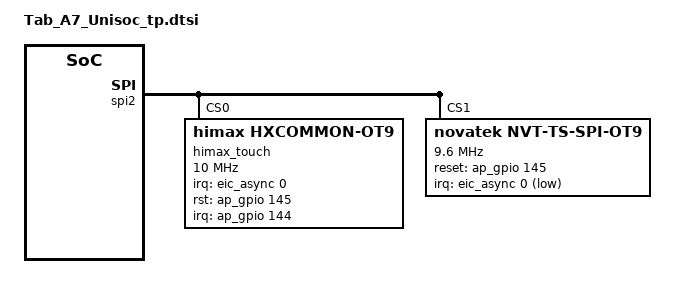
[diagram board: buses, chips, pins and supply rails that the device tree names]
/*Tab A7 T618 code for AX6189DEV-20|AX6189DEV-26 by suyurui at 2021/12/21 start*/

&spi2 {
	status = "okay";
	cs-gpios = <0>, <0>;

	himax_touch@0 {
		compatible = "himax,hxcommon-ot9";
		reg = <0>;
		status = "okay";
		spi-max-frequency = <10000000>;
		interrupt-parent = <&ap_gpio>;
		interrupts = <144 0x2004>;
		himax,panel-sense-nums = <18 32>;
		himax,panel-coords = <0 800 0 1340>;
		himax,display-coords = <0 800 0 1340>;
		himax,panel-max-points = <10>;
		himax,int-is-edge = <1>;
		/*Tab A7 T618 code for SR-AX6189A-01-425 by suyurui at 2021/12/28 start*/
		himax,irq-gpio = <&eic_async 0 GPIO_ACTIVE_HIGH>;
		/*Tab A7 T618 code for SR-AX6189A-01-425 by suyurui at 2021/12/28 end*/
		himax,rst-gpio = <&ap_gpio 145 GPIO_ACTIVE_HIGH>;
		report_type = <1>;
	};

	/*Tab A7 T618 code for SR-AX6189A-01-148 by suyurui at 2021/12/22 start*/
	novatek@1 {
		compatible = "novatek,NVT-ts-spi-ot9";
		reg = <1>; //Same as CS ID
		status = "ok";

		spi-max-frequency = <9600000>;	//4800000,9600000,15000000,19200000
		novatek,reset-gpio = <&ap_gpio 145 0x00>;
		/*Tab A7 T618 code for SR-AX6189A-01-425 by suyurui at 2021/12/28 start*/
		novatek,irq-gpio = <&eic_async 0 0x2001>;
		/*Tab A7 T618 code for SR-AX6189A-01-425 by suyurui at 2021/12/28 end*/

		//novatek,pen-support;
		//novatek,wgp-stylus;

		/* 525 */
		//novatek,swrst-n8-addr = <0x01F01A>;

		/* 672A, 525B, 675, 526, 672C, 523 */
		novatek,swrst-n8-addr = <0x03F0FE>;
		novatek,spi-rd-fast-addr = <0x03F310>;

		/*Panel setting*/
		novatek,resolution = <800 1340>;
		novatek,max_touch_num = <10>;
		novatek,area-size = <56 112 60>;	//indicator navigation edge
		novatek,fw_name = "novatek_ts_fw.bin", "tsp_novatek/nt36525_a01core_tp.bin";
		novatek,fw_name_mp = "novatek_ts_mp.bin", "tsp_novatek/nt36525_a01core_mp.bin";
		//novatek,support_ear_detect_mode;
		novatek,enable_settings_aot;

		/* MP */
		novatek,mp-support-dt;

		novatek-mp-criteria-724A@0 {
			#address-cells = <1>;
			#size-cells = <0>;
			compatible = "novatek-mp-criteria-724A";

			/* sec cmd test config */
			open_test_spec = <(-511) 5120>;
			short_test_spec = <10000 14008>;
			diff_test_frame = <50>;
			/* sec cmd fdm test config */
			fdm_x_num = <2>;
			fdm_diff_test_frame = <50>;

			/* MP Config */
			IC_X_CFG_SIZE = <22>;
			IC_Y_CFG_SIZE = <36>;
			IC_KEY_CFG_SIZE = <4>;
			X_Channel = <22>;
			Y_Channel = <36>;
			AIN_X = <0 1 2 3 4 5 6 7 8 9 10 11 12 13 14 15 16 17 18 19 20 21>;
			AIN_Y = <0 1 2 3 4 5 6 7 8 9 10 11 12 13 14 15 16 17
						18 19 20 21 22 23 24 25 26 27 28 29 30 31 32 33 34 35>;
			AIN_KEY = <0 1 2 0xFF 0xFF 0xFF 0xFF 0xFF>;

			/* MP Criteria */
			PS_Config_Lmt_Short_Rawdata_P = <
				14008 14008 14008 14008 14008 14008 14008 14008 14008 14008 14008 14008 14008 14008 14008 14008 14008 14008 14008 14008 14008 14008
				14008 14008 14008 14008 14008 14008 14008 14008 14008 14008 14008 14008 14008 14008 14008 14008 14008 14008 14008 14008 14008 14008
				14008 14008 14008 14008 14008 14008 14008 14008 14008 14008 14008 14008 14008 14008 14008 14008 14008 14008 14008 14008 14008 14008
				14008 14008 14008 14008 14008 14008 14008 14008 14008 14008 14008 14008 14008 14008 14008 14008 14008 14008 14008 14008 14008 14008
				14008 14008 14008 14008 14008 14008 14008 14008 14008 14008 14008 14008 14008 14008 14008 14008 14008 14008 14008 14008 14008 14008
				14008 14008 14008 14008 14008 14008 14008 14008 14008 14008 14008 14008 14008 14008 14008 14008 14008 14008 14008 14008 14008 14008
				14008 14008 14008 14008 14008 14008 14008 14008 14008 14008 14008 14008 14008 14008 14008 14008 14008 14008 14008 14008 14008 14008
				14008 14008 14008 14008 14008 14008 14008 14008 14008 14008 14008 14008 14008 14008 14008 14008 14008 14008 14008 14008 14008 14008
				14008 14008 14008 14008 14008 14008 14008 14008 14008 14008 14008 14008 14008 14008 14008 14008 14008 14008 14008 14008 14008 14008
				14008 14008 14008 14008 14008 14008 14008 14008 14008 14008 14008 14008 14008 14008 14008 14008 14008 14008 14008 14008 14008 14008
				14008 14008 14008 14008 14008 14008 14008 14008 14008 14008 14008 14008 14008 14008 14008 14008 14008 14008 14008 14008 14008 14008
				14008 14008 14008 14008 14008 14008 14008 14008 14008 14008 14008 14008 14008 14008 14008 14008 14008 14008 14008 14008 14008 14008
				14008 14008 14008 14008 14008 14008 14008 14008 14008 14008 14008 14008 14008 14008 14008 14008 14008 14008 14008 14008 14008 14008
				14008 14008 14008 14008 14008 14008 14008 14008 14008 14008 14008 14008 14008 14008 14008 14008 14008 14008 14008 14008 14008 14008
				14008 14008 14008 14008 14008 14008 14008 14008 14008 14008 14008 14008 14008 14008 14008 14008 14008 14008 14008 14008 14008 14008
				14008 14008 14008 14008 14008 14008 14008 14008 14008 14008 14008 14008 14008 14008 14008 14008 14008 14008 14008 14008 14008 14008
				14008 14008 14008 14008 14008 14008 14008 14008 14008 14008 14008 14008 14008 14008 14008 14008 14008 14008 14008 14008 14008 14008
				14008 14008 14008 14008 14008 14008 14008 14008 14008 14008 14008 14008 14008 14008 14008 14008 14008 14008 14008 14008 14008 14008
				14008 14008 14008 14008 14008 14008 14008 14008 14008 14008 14008 14008 14008 14008 14008 14008 14008 14008 14008 14008 14008 14008
				14008 14008 14008 14008 14008 14008 14008 14008 14008 14008 14008 14008 14008 14008 14008 14008 14008 14008 14008 14008 14008 14008
				14008 14008 14008 14008 14008 14008 14008 14008 14008 14008 14008 14008 14008 14008 14008 14008 14008 14008 14008 14008 14008 14008
				14008 14008 14008 14008 14008 14008 14008 14008 14008 14008 14008 14008 14008 14008 14008 14008 14008 14008 14008 14008 14008 14008
				14008 14008 14008 14008 14008 14008 14008 14008 14008 14008 14008 14008 14008 14008 14008 14008 14008 14008 14008 14008 14008 14008
				14008 14008 14008 14008 14008 14008 14008 14008 14008 14008 14008 14008 14008 14008 14008 14008 14008 14008 14008 14008 14008 14008
				14008 14008 14008 14008 14008 14008 14008 14008 14008 14008 14008 14008 14008 14008 14008 14008 14008 14008 14008 14008 14008 14008
				14008 14008 14008 14008 14008 14008 14008 14008 14008 14008 14008 14008 14008 14008 14008 14008 14008 14008 14008 14008 14008 14008
				14008 14008 14008 14008 14008 14008 14008 14008 14008 14008 14008 14008 14008 14008 14008 14008 14008 14008 14008 14008 14008 14008
				14008 14008 14008 14008 14008 14008 14008 14008 14008 14008 14008 14008 14008 14008 14008 14008 14008 14008 14008 14008 14008 14008
				14008 14008 14008 14008 14008 14008 14008 14008 14008 14008 14008 14008 14008 14008 14008 14008 14008 14008 14008 14008 14008 14008
				14008 14008 14008 14008 14008 14008 14008 14008 14008 14008 14008 14008 14008 14008 14008 14008 14008 14008 14008 14008 14008 14008
				14008 14008 14008 14008 14008 14008 14008 14008 14008 14008 14008 14008 14008 14008 14008 14008 14008 14008 14008 14008 14008 14008
				14008 14008 14008 14008 14008 14008 14008 14008 14008 14008 14008 14008 14008 14008 14008 14008 14008 14008 14008 14008 14008 14008
				14008 14008 14008 14008 14008 14008 14008 14008 14008 14008 14008 14008 14008 14008 14008 14008 14008 14008 14008 14008 14008 14008
				14008 14008 14008 14008 14008 14008 14008 14008 14008 14008 14008 14008 14008 14008 14008 14008 14008 14008 14008 14008 14008 14008
				14008 14008 14008 14008 14008 14008 14008 14008 14008 14008 14008 14008 14008 14008 14008 14008 14008 14008 14008 14008 14008 14008
				14008 14008 14008 14008 14008 14008 14008 14008 14008 14008 14008 14008 14008 14008 14008 14008 14008 14008 14008 14008 14008 14008
				14008 14008 14008>;

			PS_Config_Lmt_Short_Rawdata_N = <
				10100	10100	10100	10100	10100	10100	10100	10100	10100	10100	10100	10100	10100	10100	10100	10100	10100	10100	10100	10100	10100	10100
				10100	10100	10100	10100	10100	10100	10100	10100	10100	10100	10100	10100	10100	10100	10100	10100	10100	10100	10100	10100	10100	10100
				10100	10100	10100	10100	10100	10100	10100	10100	10100	10100	10100	10100	10100	10100	10100	10100	10100	10100	10100	10100	10100	10100
				10100	10100	10100	10100	10100	10100	10100	10100	10100	10100	10100	10100	10100	10100	10100	10100	10100	10100	10100	10100	10100	10100
				10100	10100	10100	10100	10100	10100	10100	10100	10100	10100	10100	10100	10100	10100	10100	10100	10100	10100	10100	10100	10100	10100
				10100	10100	10100	10100	10100	10100	10100	10100	10100	10100	10100	10100	10100	10100	10100	10100	10100	10100	10100	10100	10100	10100
				10100	10100	10100	10100	10100	10100	10100	10100	10100	10100	10100	10100	10100	10100	10100	10100	10100	10100	10100	10100	10100	10100
				10100	10100	10100	10100	10100	10100	10100	10100	10100	10100	10100	10100	10100	10100	10100	10100	10100	10100	10100	10100	10100	10100
				10100	10100	10100	10100	10100	10100	10100	10100	10100	10100	10100	10100	10100	10100	10100	10100	10100	10100	10100	10100	10100	10100
				10100	10100	10100	10100	10100	10100	10100	10100	10100	10100	10100	10100	10100	10100	10100	10100	10100	10100	10100	10100	10100	10100
				10100	10100	10100	10100	10100	10100	10100	10100	10100	10100	10100	10100	10100	10100	10100	10100	10100	10100	10100	10100	10100	10100
				10100	10100	10100	10100	10100	10100	10100	10100	10100	10100	10100	10100	10100	10100	10100	10100	10100	10100	10100	10100	10100	10100
				10100	10100	10100	10100	10100	10100	10100	10100	10100	10100	10100	10100	10100	10100	10100	10100	10100	10100	10100	10100	10100	10100
				10100	10100	10100	10100	10100	10100	10100	10100	10100	10100	10100	10100	10100	10100	10100	10100	10100	10100	10100	10100	10100	10100
				10100	10100	10100	10100	10100	10100	10100	10100	10100	10100	10100	10100	10100	10100	10100	10100	10100	10100	10100	10100	10100	10100
				10100	10100	10100	10100	10100	10100	10100	10100	10100	10100	10100	10100	10100	10100	10100	10100	10100	10100	10100	10100	10100	10100
				10100	10100	10100	10100	10100	10100	10100	10100	10100	10100	10100	10100	10100	10100	10100	10100	10100	10100	10100	10100	10100	10100
				10100	10100	10100	10100	10100	10100	10100	10100	10100	10100	10100	10100	10100	10100	10100	10100	10100	10100	10100	10100	10100	10100
				10100	10100	10100	10100	10100	10100	10100	10100	10100	10100	10100	10100	10100	10100	10100	10100	10100	10100	10100	10100	10100	10100
				10100	10100	10100	10100	10100	10100	10100	10100	10100	10100	10100	10100	10100	10100	10100	10100	10100	10100	10100	10100	10100	10100
				10100	10100	10100	10100	10100	10100	10100	10100	10100	10100	10100	10100	10100	10100	10100	10100	10100	10100	10100	10100	10100	10100
				10100	10100	10100	10100	10100	10100	10100	10100	10100	10100	10100	10100	10100	10100	10100	10100	10100	10100	10100	10100	10100	10100
				10100	10100	10100	10100	10100	10100	10100	10100	10100	10100	10100	10100	10100	10100	10100	10100	10100	10100	10100	10100	10100	10100
				10100	10100	10100	10100	10100	10100	10100	10100	10100	10100	10100	10100	10100	10100	10100	10100	10100	10100	10100	10100	10100	10100
				10100	10100	10100	10100	10100	10100	10100	10100	10100	10100	10100	10100	10100	10100	10100	10100	10100	10100	10100	10100	10100	10100
				10100	10100	10100	10100	10100	10100	10100	10100	10100	10100	10100	10100	10100	10100	10100	10100	10100	10100	10100	10100	10100	10100
				10100	10100	10100	10100	10100	10100	10100	10100	10100	10100	10100	10100	10100	10100	10100	10100	10100	10100	10100	10100	10100	10100
				10100	10100	10100	10100	10100	10100	10100	10100	10100	10100	10100	10100	10100	10100	10100	10100	10100	10100	10100	10100	10100	10100
				10100	10100	10100	10100	10100	10100	10100	10100	10100	10100	10100	10100	10100	10100	10100	10100	10100	10100	10100	10100	10100	10100
				10100	10100	10100	10100	10100	10100	10100	10100	10100	10100	10100	10100	10100	10100	10100	10100	10100	10100	10100	10100	10100	10100
				10100	10100	10100	10100	10100	10100	10100	10100	10100	10100	10100	10100	10100	10100	10100	10100	10100	10100	10100	10100	10100	10100
				10100	10100	10100	10100	10100	10100	10100	10100	10100	10100	10100	10100	10100	10100	10100	10100	10100	10100	10100	10100	10100	10100
				10100	10100	10100	10100	10100	10100	10100	10100	10100	10100	10100	10100	10100	10100	10100	10100	10100	10100	10100	10100	10100	10100
				10100	10100	10100	10100	10100	10100	10100	10100	10100	10100	10100	10100	10100	10100	10100	10100	10100	10100	10100	10100	10100	10100
				10100	10100	10100	10100	10100	10100	10100	10100	10100	10100	10100	10100	10100	10100	10100	10100	10100	10100	10100	10100	10100	10100
				10100	10100	10100	10100	10100	10100	10100	10100	10100	10100	10100	10100	10100	10100	10100	10100	10100	10100	10100	10100	10100	10100
				10000 10000 10000>;

			PS_Config_Lmt_Open_Rawdata_P = <
				3568	3542	3516	3416	3431	3397	3400	3369	3477	3388	3287	3339	3417	3354	3336	3413	3374	3403	3488	3607	3595	3565
				3494	3445	3483	3442	3396	3392	3306	3288	3365	3298	3250	3259	3343	3298	3318	3448	3399	3340	3420	3514	3498	3507
				3563	3542	3530	3438	3319	3390	3323	3288	3446	3364	3123	3320	3414	3383	3360	3474	3395	3379	3477	3571	3568	3399
				3497	3455	3462	3434	3337	3396	3392	3365	3403	3264	3259	3285	3357	3315	3313	3420	3371	3341	3460	3553	3451	3508
				3444	3484	3488	3418	3312	3395	3327	3264	3383	3201	3273	3284	3362	3337	3323	3425	3403	3319	3437	3504	3388	3544
				3537	3431	3441	3396	3301	3376	3318	3246	3339	3346	3222	3270	3346	3288	3288	3362	3341	3361	3327	3445	3488	3451
				3455	3453	3456	3459	3361	3438	3346	3197	3297	3313	3299	3285	3340	3319	3353	3339	3404	3358	3334	3414	3480	3535
				3539	3488	3490	3395	3318	3376	3236	3318	3386	3332	3245	3264	3365	3322	3281	3288	3360	3245	3428	3560	3543	3491
				3462	3444	3467	3477	3371	3465	3312	3312	3249	3325	3255	3276	3351	3316	3346	3340	3430	3353	3469	3574	3521	3542
				3498	3438	3484	3418	3200	3263	3326	3309	3257	3330	3312	3281	3407	3375	3308	3189	3256	3355	3435	3515	3491	3488
				3490	3427	3465	3427	3283	3413	3389	3325	3274	3374	3298	3313	3423	3368	3347	3308	3378	3417	3493	3568	3565	3498
				3493	3442	3465	3353	3392	3409	3346	3304	3263	3353	3291	3283	3368	3340	3176	3340	3411	3369	3453	3493	3500	3549
				3511	3460	3504	3460	3337	3437	3372	3362	3320	3414	3320	3332	3423	3409	3304	3357	3404	3400	3502	3500	3561	3529
				3483	3284	3325	3467	3399	3472	3404	3306	3284	3351	3309	3294	3361	3193	3374	3334	3437	3403	3430	3442	3519	3505
				3543	3505	3553	3501	3353	3430	3385	3386	3330	3431	3353	3357	3312	3414	3374	3348	3414	3395	3495	3501	3582	3584
				3322	3467	3490	3487	3376	3430	3404	3319	3280	3353	3295	3110	3264	3374	3347	3344	3472	3453	3469	3469	3518	3497
				3558	3522	3568	3529	3372	3277	3393	3332	3284	3428	3354	3341	3320	3438	3425	3376	3490	3442	3511	3516	3572	3563
				3494	3465	3481	3470	3368	3292	3393	3392	3353	3376	3313	3315	3287	3381	3358	3347	3438	3416	3472	3498	3551	3505
				3487	3472	3554	3537	3390	3311	3430	3379	3299	3400	3341	3351	3332	3430	3417	3396	3491	3488	3486	3515	3542	3537
				3567	3544	3500	3495	3367	3295	3414	3371	3358	3438	3383	3319	3318	3414	3378	3358	3425	3425	3530	3493	3571	3544
				3528	3487	3518	3515	3425	3353	3483	3400	3313	3403	3350	3334	3327	3413	3407	3420	3367	3493	3528	3493	3542	3525
				3518	3546	3556	3547	3371	3313	3418	3389	3333	3400	3367	3367	3304	3439	3400	3336	3319	3451	3497	3501	3602	3581
				3532	3497	3514	3512	3444	3360	3493	3424	3326	3231	3354	3365	3318	3413	3393	3399	3374	3511	3586	3532	3607	3556
				3519	3523	3508	3539	3382	3309	3410	3364	3326	3243	3353	3336	3319	3472	3451	3369	3337	3452	3515	3500	3553	3521
				3558	3521	3428	3519	3392	3313	3487	3424	3347	3259	3393	3417	3346	3487	3437	3407	3382	3500	3574	3557	3605	3599
				3497	3515	3444	3518	3455	3379	3431	3379	3323	3243	3371	3347	3316	3434	3414	3371	3364	3487	3523	3511	3528	3532
				3560	3536	3458	3551	3437	3322	3456	3413	3381	3302	3435	3409	3365	3487	3484	3382	3376	3480	3554	3578	3549	3595
				3519	3508	3439	3533	3425	3374	3495	3446	3313	3262	3368	3357	3318	3418	3421	3423	3344	3505	3556	3486	3493	3540
				3523	3563	3498	3586	3445	3327	3451	3411	3392	3306	3442	3386	3379	3340	3479	3418	3354	3479	3542	3550	3553	3606
				3565	3502	3452	3523	3434	3354	3445	3425	3325	3253	3358	3378	3302	3285	3432	3383	3354	3539	3598	3516	3511	3533
				3519	3582	3502	3595	3465	3343	3257	3409	3334	3257	3431	3361	3361	3341	3490	3459	3382	3544	3575	3558	3554	3591
				3536	3514	3444	3505	3402	3337	3267	3403	3390	3318	3379	3423	3326	3299	3424	3393	3348	3481	3540	3514	3528	3565
				3571	3564	3490	3627	3509	3404	3323	3495	3417	3308	3449	3459	3410	3381	3528	3494	3444	3578	3656	3572	3592	3600
				3568	3627	3556	3561	3462	3372	3308	3469	3404	3350	3480	3424	3362	3360	3502	3441	3388	3502	3584	3614	3556	3621
				3596	3574	3490	3568	3474	3417	3350	3523	3424	3294	3424	3486	3367	3364	3487	3465	3444	3402	3641	3596	3554	3588
				3586	3567	3554	3605	3519	3361	3318	3462	3420	3333	3434	3432	3416	3347	3518	3463	3369	3357	3599	3565	3567	3680
				5120 5120 5120>;

			PS_Config_Lmt_Open_Rawdata_N = <
				1529	1518	1507	1464	1470	1456	1457	1444	1490	1452	1408	1431	1464	1437	1429	1462	1446	1458	1495	1546	1540	1528
				1497	1476	1492	1475	1455	1453	1417	1409	1442	1413	1393	1396	1432	1413	1422	1477	1456	1431	1465	1506	1499	1503
				1527	1518	1513	1473	1422	1453	1424	1409	1477	1441	1338	1423	1463	1450	1440	1489	1455	1448	1490	1530	1529	1456
				1498	1480	1483	1471	1430	1455	1453	1442	1458	1399	1396	1408	1438	1420	1420	1465	1444	1432	1483	1522	1479	1503
				1476	1493	1495	1465	1419	1455	1426	1399	1450	1372	1402	1407	1441	1430	1424	1468	1458	1422	1473	1501	1452	1519
				1516	1470	1474	1455	1414	1447	1422	1391	1431	1434	1381	1401	1434	1409	1409	1441	1432	1440	1426	1476	1495	1479
				1480	1480	1481	1482	1440	1473	1434	1370	1413	1420	1414	1408	1431	1422	1437	1431	1459	1439	1429	1463	1491	1515
				1516	1495	1495	1455	1422	1447	1387	1422	1451	1428	1390	1399	1442	1423	1406	1409	1440	1390	1469	1525	1518	1496
				1483	1476	1486	1490	1444	1485	1419	1419	1392	1425	1395	1404	1436	1421	1434	1431	1470	1437	1486	1531	1509	1518
				1499	1473	1493	1465	1371	1398	1425	1418	1396	1427	1419	1406	1460	1446	1417	1366	1395	1438	1472	1506	1496	1495
				1495	1468	1485	1468	1407	1462	1452	1425	1403	1446	1413	1420	1467	1443	1434	1417	1447	1464	1497	1529	1528	1499
				1497	1475	1485	1437	1453	1461	1434	1416	1398	1437	1410	1407	1443	1431	1361	1431	1462	1444	1480	1497	1500	1521
				1504	1483	1501	1483	1430	1473	1445	1441	1423	1463	1423	1428	1467	1461	1416	1438	1459	1457	1501	1500	1526	1512
				1492	1407	1425	1486	1456	1488	1459	1417	1407	1436	1418	1411	1440	1368	1446	1429	1473	1458	1470	1475	1508	1502
				1518	1502	1522	1500	1437	1470	1450	1451	1427	1470	1437	1438	1419	1463	1446	1435	1463	1455	1498	1500	1535	1536
				1423	1486	1495	1494	1447	1470	1459	1422	1405	1437	1412	1333	1399	1446	1434	1433	1488	1480	1486	1486	1507	1498
				1525	1509	1529	1512	1445	1404	1454	1428	1407	1469	1437	1432	1423	1473	1468	1447	1495	1475	1504	1507	1531	1527
				1497	1485	1492	1487	1443	1411	1454	1453	1437	1447	1420	1420	1408	1449	1439	1434	1473	1464	1488	1499	1522	1502
				1494	1488	1523	1516	1453	1419	1470	1448	1414	1457	1432	1436	1428	1470	1464	1455	1496	1495	1494	1506	1518	1516
				1528	1519	1500	1498	1443	1412	1463	1444	1439	1473	1450	1422	1422	1463	1447	1439	1468	1468	1513	1497	1530	1519
				1512	1494	1507	1506	1468	1437	1492	1457	1420	1458	1435	1429	1426	1462	1460	1465	1443	1497	1512	1497	1518	1510
				1507	1519	1524	1520	1444	1420	1465	1452	1428	1457	1443	1443	1416	1474	1457	1429	1422	1479	1498	1500	1543	1534
				1513	1498	1506	1505	1476	1440	1497	1467	1425	1384	1437	1442	1422	1462	1454	1456	1446	1504	1537	1513	1546	1524
				1508	1510	1503	1516	1449	1418	1461	1441	1425	1390	1437	1429	1422	1488	1479	1444	1430	1479	1506	1500	1522	1509
				1525	1509	1469	1508	1453	1420	1494	1467	1434	1396	1454	1464	1434	1494	1473	1460	1449	1500	1531	1524	1545	1542
				1498	1506	1476	1507	1480	1448	1470	1448	1424	1390	1444	1434	1421	1471	1463	1444	1441	1494	1510	1504	1512	1513
				1525	1515	1482	1522	1473	1423	1481	1462	1449	1415	1472	1461	1442	1494	1493	1449	1447	1491	1523	1533	1521	1540
				1508	1503	1474	1514	1468	1446	1498	1477	1420	1398	1443	1438	1422	1465	1466	1467	1433	1502	1524	1494	1497	1517
				1510	1527	1499	1537	1476	1426	1479	1462	1453	1417	1475	1451	1448	1431	1491	1465	1437	1491	1518	1521	1522	1545
				1528	1501	1479	1510	1471	1437	1476	1468	1425	1394	1439	1447	1415	1408	1471	1450	1437	1516	1542	1507	1504	1514
				1508	1535	1501	1540	1485	1432	1396	1461	1429	1396	1470	1440	1440	1432	1495	1482	1449	1519	1532	1525	1523	1539
				1515	1506	1476	1502	1458	1430	1400	1458	1453	1422	1448	1467	1425	1414	1467	1454	1435	1492	1517	1506	1512	1528
				1530	1527	1495	1554	1504	1459	1424	1498	1464	1417	1478	1482	1461	1449	1512	1497	1476	1533	1567	1531	1539	1543
				1529	1554	1524	1526	1483	1445	1417	1486	1459	1435	1491	1467	1441	1440	1501	1474	1452	1501	1536	1549	1524	1552
				1541	1531	1495	1529	1489	1464	1435	1510	1467	1411	1467	1494	1443	1441	1494	1485	1476	1458	1560	1541	1523	1537
				1537	1528	1523	1545	1508	1440	1422	1483	1465	1428	1471	1471	1464	1434	1507	1484	1444	1438	1542	1528	1528	1577
				(-511) (-511) (-511)>;

			PS_Config_Lmt_FW_Rawdata_P = <
				1125	1122	1129	1127	1127	1118	1114	1120	1117	1120	1121	1122	1124	1117	1127	1121	1120	1114	1131	1122	1128	1129
				1115	1117	1124	1122	1110	1111	1118	1108	1128	1118	1128	1113	1124	1111	1120	1117	1118	1117	1122	1122	1113	1122
				1115	1117	1125	1121	1124	1120	1121	1122	1122	1115	1120	1122	1118	1120	1124	1124	1117	1117	1108	1114	1127	1115
				1118	1120	1121	1127	1122	1114	1117	1129	1113	1118	1111	1131	1121	1114	1117	1111	1128	1127	1117	1111	1104	1103
				1122	1125	1121	1118	1121	1107	1120	1138	1113	1111	1121	1127	1124	1120	1121	1122	1120	1113	1114	1118	1125	1115
				1127	1131	1121	1118	1129	1110	1125	1134	1115	1121	1122	1118	1118	1115	1131	1122	1120	1124	1125	1113	1103	1122
				1128	1120	1111	1122	1117	1122	1114	1117	1131	1115	1125	1120	1120	1121	1121	1120	1120	1111	1122	1125	1113	1122
				1122	1118	1122	1127	1114	1118	1118	1124	1117	1127	1122	1120	1118	1115	1118	1117	1114	1122	1122	1114	1125	1122
				1120	1114	1117	1128	1120	1121	1114	1113	1127	1122	1118	1124	1114	1117	1110	1117	1122	1120	1122	1113	1117	1118
				1122	1125	1124	1122	1120	1117	1118	1120	1122	1128	1120	1120	1117	1121	1128	1125	1117	1128	1120	1113	1117	1125
				1120	1122	1122	1118	1124	1114	1114	1121	1124	1125	1120	1113	1117	1120	1124	1111	1124	1115	1117	1125	1120	1114
				1122	1122	1122	1120	1117	1128	1135	1115	1128	1120	1113	1120	1124	1111	1124	1121	1125	1124	1132	1124	1117	1131
				1122	1120	1122	1124	1127	1114	1118	1128	1117	1121	1131	1120	1115	1122	1118	1118	1120	1122	1124	1117	1121	1122
				1114	1124	1115	1118	1132	1120	1122	1124	1111	1127	1118	1131	1118	1124	1121	1125	1121	1118	1121	1129	1108	1117
				1113	1115	1127	1134	1120	1115	1115	1121	1118	1117	1117	1128	1114	1122	1115	1115	1122	1113	1113	1113	1125	1122
				1110	1111	1121	1114	1121	1129	1113	1124	1120	1128	1120	1120	1129	1127	1122	1114	1111	1118	1117	1122	1115	1107
				1122	1114	1118	1124	1113	1121	1121	1122	1122	1124	1128	1113	1117	1120	1120	1122	1125	1118	1125	1111	1118	1120
				1110	1115	1124	1120	1118	1121	1125	1120	1115	1113	1107	1117	1114	1120	1125	1114	1122	1108	1114	1122	1127	1120
				1121	1124	1122	1122	1121	1118	1129	1125	1129	1121	1125	1128	1108	1121	1120	1113	1113	1117	1124	1118	1125	1120
				1117	1122	1121	1111	1120	1118	1138	1120	1127	1127	1117	1114	1121	1125	1128	1128	1122	1125	1118	1124	1122	1125
				1120	1131	1127	1124	1131	1115	1114	1132	1117	1115	1118	1127	1121	1124	1113	1117	1118	1117	1122	1115	1124	1124
				1127	1125	1121	1121	1121	1110	1118	1117	1121	1125	1122	1122	1122	1124	1129	1114	1131	1129	1120	1115	1117	1121
				1107	1114	1110	1115	1115	1120	1115	1120	1118	1117	1120	1124	1115	1125	1115	1111	1114	1117	1111	1114	1121	1124
				1118	1120	1125	1104	1118	1113	1115	1117	1121	1120	1114	1121	1110	1124	1111	1127	1117	1120	1120	1113	1129	1124
				1131	1120	1120	1118	1117	1125	1120	1124	1114	1115	1118	1117	1121	1115	1122	1121	1110	1121	1127	1115	1117	1118
				1136	1122	1122	1111	1114	1115	1120	1107	1120	1122	1104	1124	1114	1113	1121	1113	1118	1114	1129	1128	1120	1108
				1122	1120	1118	1114	1122	1127	1111	1127	1124	1114	1125	1124	1118	1129	1122	1122	1122	1117	1113	1120	1115	1129
				1127	1117	1120	1114	1125	1129	1118	1118	1121	1110	1120	1124	1124	1118	1124	1122	1127	1122	1129	1120	1138	1111
				1121	1127	1115	1121	1131	1114	1121	1118	1111	1120	1117	1118	1117	1114	1118	1120	1111	1114	1120	1111	1121	1118
				1114	1120	1113	1113	1120	1121	1113	1106	1127	1113	1120	1135	1117	1135	1127	1125	1114	1127	1108	1120	1121	1122
				1124	1122	1118	1117	1114	1121	1120	1122	1111	1124	1120	1117	1115	1115	1115	1122	1120	1118	1122	1124	1114	1118
				1124	1118	1108	1125	1117	1128	1121	1121	1127	1120	1117	1118	1127	1115	1118	1128	1117	1121	1114	1124	1127	1131
				1118	1120	1127	1118	1122	1115	1114	1120	1124	1125	1113	1117	1118	1114	1117	1122	1128	1114	1121	1120	1114	1118
				1114	1128	1121	1122	1124	1111	1117	1128	1117	1114	1114	1113	1120	1115	1129	1114	1107	1121	1125	1125	1125	1122
				1117	1114	1122	1124	1120	1113	1121	1127	1113	1120	1113	1122	1121	1122	1124	1124	1125	1121	1114	1110	1120	1125
				1121	1121	1124	1118	1124	1121	1125	1127	1124	1125	1120	1111	1115	1108	1121	1107	1127	1120	1118	1118	1117	1124
				3840 3840 3840>;

			PS_Config_Lmt_FW_Rawdata_N = <
				482	481	484	483	483	479	477	480	478	480	480	481	481	478	483	480	480	477	484	481	483	484
				478	478	481	481	475	476	479	475	483	479	483	477	481	476	480	478	479	478	481	481	477	481
				478	478	482	480	481	480	480	481	481	478	480	481	479	480	481	481	478	478	475	477	483	478
				479	480	480	483	481	477	478	484	477	479	476	484	480	477	478	476	483	483	478	476	473	472
				481	482	480	479	480	474	480	487	477	476	480	483	481	480	480	481	480	477	477	479	482	478
				483	484	480	479	484	475	482	486	478	480	481	479	479	478	484	481	480	481	482	477	472	481
				483	480	476	481	478	481	477	478	484	478	482	480	480	480	480	480	480	476	481	482	477	481
				481	479	481	483	477	479	479	481	478	483	481	480	479	478	479	478	477	481	481	477	482	481
				480	477	478	483	480	480	477	477	483	481	479	481	477	478	475	478	481	480	481	477	478	479
				481	482	481	481	480	478	479	480	481	483	480	480	478	480	483	482	478	483	480	477	478	482
				480	481	481	479	481	477	477	480	481	482	480	477	478	480	481	476	481	478	478	482	480	477
				481	481	481	480	478	483	486	478	483	480	477	480	481	476	481	480	482	481	485	481	478	484
				481	480	481	481	483	477	479	483	478	480	484	480	478	481	479	479	480	481	481	478	480	481
				477	481	478	479	485	480	481	481	476	483	479	484	479	481	480	482	480	479	480	484	475	478
				477	478	483	486	480	478	478	480	479	478	478	483	477	481	478	478	481	477	477	477	482	481
				475	476	480	477	480	484	477	481	480	483	480	480	484	483	481	477	476	479	478	481	478	474
				481	477	479	481	477	480	480	481	481	481	483	477	478	480	480	481	482	479	482	476	479	480
				475	478	481	480	479	480	482	480	478	477	474	478	477	480	482	477	481	475	477	481	483	480
				480	481	481	481	480	479	484	482	484	480	482	483	475	480	480	477	477	478	481	479	482	480
				478	481	480	476	480	479	487	480	483	483	478	477	480	482	483	483	481	482	479	481	481	482
				480	484	483	481	484	478	477	485	478	478	479	483	480	481	477	478	479	478	481	478	481	481
				483	482	480	480	480	475	479	478	480	482	481	481	481	481	484	477	484	484	480	478	478	480
				474	477	475	478	478	480	478	480	479	478	480	481	478	482	478	476	477	478	476	477	480	481
				479	480	482	473	479	477	478	478	480	480	477	480	475	481	476	483	478	480	480	477	484	481
				484	480	480	479	478	482	480	481	477	478	479	478	480	478	481	480	475	480	483	478	478	479
				487	481	481	476	477	478	480	474	480	481	473	481	477	477	480	477	479	477	484	483	480	475
				481	480	479	477	481	483	476	483	481	477	482	481	479	484	481	481	481	478	477	480	478	484
				483	478	480	477	482	484	479	479	480	475	480	481	481	479	481	481	483	481	484	480	487	476
				480	483	478	480	484	477	480	479	476	480	478	479	478	477	479	480	476	477	480	476	480	479
				477	480	477	477	480	480	477	474	483	477	480	486	478	486	483	482	477	483	475	480	480	481
				481	481	479	478	477	480	480	481	476	481	480	478	478	478	478	481	480	479	481	481	477	479
				481	479	475	482	478	483	480	480	483	480	478	479	483	478	479	483	478	480	477	481	483	484
				479	480	483	479	481	478	477	480	481	482	477	478	479	477	478	481	483	477	480	480	477	479
				477	483	480	481	481	476	478	483	478	477	477	477	480	478	484	477	474	480	482	482	482	481
				478	477	481	481	480	477	480	483	477	480	477	481	480	481	481	481	482	480	477	475	480	482
				480	480	481	479	481	480	482	483	481	482	480	476	478	475	480	474	483	480	479	479	478	481
				240 240 240>;

			PS_Config_Lmt_FW_CC_P = <
				71	69	70	69	67	69	71	70	70	70	70	66	70	69	70	70	70	70	71	71	70	71
				70	67	67	69	66	69	69	67	67	69	67	64	69	69	69	69	69	69	69	67	69	70
				70	69	69	69	63	67	67	69	70	70	69	70	70	69	69	69	69	69	69	69	70	70
				69	67	69	69	64	69	69	69	69	69	69	69	69	69	69	69	69	69	70	69	69	69
				70	69	70	69	69	70	67	69	69	69	69	69	69	70	69	69	70	69	70	69	69	71
				71	67	69	69	67	69	69	69	69	70	69	70	70	69	69	67	69	70	69	69	70	69
				70	67	69	69	69	69	70	69	67	69	70	70	69	69	70	64	70	69	69	69	69	70
				70	70	70	69	69	69	69	69	67	70	69	70	69	70	69	63	69	69	69	70	70	70
				69	67	69	70	69	70	69	70	63	69	69	69	69	70	69	70	70	70	70	69	70	70
				70	66	70	69	67	69	70	69	64	69	70	69	70	70	70	69	69	69	70	69	69	70
				70	63	69	69	69	70	70	69	69	70	69	70	70	70	70	69	69	71	69	69	70	70
				69	64	69	70	70	69	69	69	67	69	69	70	69	69	69	70	70	69	69	66	69	70
				70	69	70	69	69	69	69	69	69	70	70	70	69	70	70	70	69	69	71	64	70	70
				70	67	69	69	70	70	70	69	69	70	69	69	67	69	70	69	70	70	69	63	69	70
				70	69	70	70	69	69	69	70	69	70	70	71	64	70	69	69	69	70	69	70	70	71
				69	69	70	69	69	67	70	69	67	69	70	69	63	69	69	69	70	70	70	69	69	70
				71	69	70	70	70	63	69	69	69	71	70	70	70	71	69	69	70	70	70	69	69	71
				70	67	69	70	69	64	70	70	70	70	69	70	67	69	69	69	69	69	70	70	70	70
				69	69	70	70	69	69	70	69	69	69	70	70	69	70	71	69	69	70	70	70	70	70
				71	70	70	69	69	67	69	69	70	70	70	70	69	70	69	69	67	70	70	69	70	71
				69	69	69	69	70	69	70	70	69	69	70	70	69	70	70	70	64	70	69	69	70	70
				71	69	70	70	69	69	70	69	69	67	70	70	69	70	71	69	63	70	69	69	70	71
				71	69	69	70	70	69	70	70	70	63	69	69	69	70	70	69	70	71	70	69	70	71
				70	69	67	70	69	67	69	70	69	64	70	69	69	71	70	70	67	70	69	69	69	70
				70	70	63	69	69	69	71	70	69	69	71	70	69	70	70	70	69	70	71	69	69	71
				70	69	64	70	70	70	70	69	69	67	70	69	69	69	70	69	69	71	69	69	67	70
				71	69	69	71	69	69	70	70	70	69	70	71	69	70	70	70	69	70	70	70	64	71
				70	69	67	70	69	69	70	70	69	69	70	69	69	67	70	70	69	70	71	69	63	70
				70	70	69	70	70	69	69	70	70	69	71	70	70	64	70	69	69	70	70	69	71	73
				71	69	69	70	69	69	69	70	69	67	70	71	69	63	70	69	69	71	70	70	67	70
				70	70	69	70	70	69	63	69	69	69	71	70	69	70	71	69	69	70	70	70	69	70
				71	69	67	69	70	69	64	70	70	70	70	70	69	67	69	69	69	69	69	69	69	71
				70	69	69	71	70	69	69	70	69	69	70	70	70	69	70	71	69	70	70	69	69	71
				70	70	69	70	69	69	67	69	69	69	70	69	69	69	70	69	69	67	69	70	69	71
				71	69	69	69	69	69	67	70	70	67	69	70	69	69	70	69	70	64	70	69	69	70
				70	69	69	70	70	67	69	70	69	69	69	69	69	69	70	70	67	63	69	69	69	71
				314 314 314>;

			PS_Config_Lmt_FW_CC_N = <
				32	31	31	31	30	31	32	31	31	31	31	29	31	31	31	31	31	31	32	32	31	32
				31	30	30	31	29	31	31	30	30	31	30	29	31	31	31	31	31	31	31	30	31	31
				31	31	31	31	28	30	30	31	31	31	31	31	31	31	31	31	31	31	31	31	31	31
				31	30	31	31	29	31	31	31	31	31	31	31	31	31	31	31	31	31	31	31	31	31
				31	31	31	31	31	31	30	31	31	31	31	31	31	31	31	31	31	31	31	31	31	32
				32	30	31	31	30	31	31	31	31	31	31	31	31	31	31	30	31	31	31	31	31	31
				31	30	31	31	31	31	31	31	30	31	31	31	31	31	31	29	31	31	31	31	31	31
				31	31	31	31	31	31	31	31	30	31	31	31	31	31	31	28	31	31	31	31	31	31
				31	30	31	31	31	31	31	31	28	31	31	31	31	31	31	31	31	31	31	31	31	31
				31	29	31	31	30	31	31	31	29	31	31	31	31	31	31	31	31	31	31	31	31	31
				31	28	31	31	31	31	31	31	31	31	31	31	31	31	31	31	31	32	31	31	31	31
				31	29	31	31	31	31	31	31	30	31	31	31	31	31	31	31	31	31	31	29	31	31
				31	31	31	31	31	31	31	31	31	31	31	31	31	31	31	31	31	31	32	29	31	31
				31	30	31	31	31	31	31	31	31	31	31	31	30	31	31	31	31	31	31	28	31	31
				31	31	31	31	31	31	31	31	31	31	31	32	29	31	31	31	31	31	31	31	31	32
				31	31	31	31	31	30	31	31	30	31	31	31	28	31	31	31	31	31	31	31	31	31
				32	31	31	31	31	28	31	31	31	32	31	31	31	32	31	31	31	31	31	31	31	32
				31	30	31	31	31	29	31	31	31	31	31	31	30	31	31	31	31	31	31	31	31	31
				31	31	31	31	31	31	31	31	31	31	31	31	31	31	32	31	31	31	31	31	31	31
				32	31	31	31	31	30	31	31	31	31	31	31	31	31	31	31	30	31	31	31	31	32
				31	31	31	31	31	31	31	31	31	31	31	31	31	31	31	31	29	31	31	31	31	31
				32	31	31	31	31	31	31	31	31	30	31	31	31	31	32	31	28	31	31	31	31	32
				32	31	31	31	31	31	31	31	31	28	31	31	31	31	31	31	31	32	31	31	31	32
				31	31	30	31	31	30	31	31	31	29	31	31	31	32	31	31	30	31	31	31	31	31
				31	31	28	31	31	31	32	31	31	31	32	31	31	31	31	31	31	31	32	31	31	32
				31	31	29	31	31	31	31	31	31	30	31	31	31	31	31	31	31	32	31	31	30	31
				32	31	31	32	31	31	31	31	31	31	31	32	31	31	31	31	31	31	31	31	29	32
				31	31	30	31	31	31	31	31	31	31	31	31	31	30	31	31	31	31	32	31	28	31
				31	31	31	31	31	31	31	31	31	31	32	31	31	29	31	31	31	31	31	31	32	32
				32	31	31	31	31	31	31	31	31	30	31	32	31	28	31	31	31	32	31	31	30	31
				31	31	31	31	31	31	28	31	31	31	32	31	31	31	32	31	31	31	31	31	31	31
				32	31	30	31	31	31	29	31	31	31	31	31	31	30	31	31	31	31	31	31	31	32
				31	31	31	32	31	31	31	31	31	31	31	31	31	31	31	32	31	31	31	31	31	32
				31	31	31	31	31	31	30	31	31	31	31	31	31	31	31	31	31	30	31	31	31	32
				32	31	31	31	31	31	30	31	31	30	31	31	31	31	31	31	31	29	31	31	31	31
				31	31	31	31	31	30	31	31	31	31	31	31	31	31	31	31	30	28	31	31	31	32
				0 0 0>;

			PS_Config_Lmt_FW_Diff_P = <
				50	50	50	50	50	50	50	50	50	50	50	50	50	50	50	50	50	50	50	50	50	50
				50	50	50	50	50	50	50	50	50	50	50	50	50	50	50	50	50	50	50	50	50	50
				50	50	50	50	50	50	50	50	50	50	50	50	50	50	50	50	50	50	50	50	50	50
				50	50	50	50	50	50	50	50	50	50	50	50	50	50	50	50	50	50	50	50	50	50
				50	50	50	50	50	50	50	50	50	50	50	50	50	50	50	50	50	50	50	50	50	50
				50	50	50	50	50	50	50	50	50	50	50	50	50	50	50	50	50	50	50	50	50	50
				50	50	50	50	50	50	50	50	50	50	50	50	50	50	50	50	50	50	50	50	50	50
				50	50	50	50	50	50	50	50	50	50	50	50	50	50	50	50	50	50	50	50	50	50
				50	50	50	50	50	50	50	50	50	50	50	50	50	50	50	50	50	50	50	50	50	50
				50	50	50	50	50	50	50	50	50	50	50	50	50	50	50	50	50	50	50	50	50	50
				50	50	50	50	50	50	50	50	50	50	50	50	50	50	50	50	50	50	50	50	50	50
				50	50	50	50	50	50	50	50	50	50	50	50	50	50	50	50	50	50	50	50	50	50
				50	50	50	50	50	50	50	50	50	50	50	50	50	50	50	50	50	50	50	50	50	50
				50	50	50	50	50	50	50	50	50	50	50	50	50	50	50	50	50	50	50	50	50	50
				50	50	50	50	50	50	50	50	50	50	50	50	50	50	50	50	50	50	50	50	50	50
				50	50	50	50	50	50	50	50	50	50	50	50	50	50	50	50	50	50	50	50	50	50
				50	50	50	50	50	50	50	50	50	50	50	50	50	50	50	50	50	50	50	50	50	50
				50	50	50	50	50	50	50	50	50	50	50	50	50	50	50	50	50	50	50	50	50	50
				50	50	50	50	50	50	50	50	50	50	50	50	50	50	50	50	50	50	50	50	50	50
				50	50	50	50	50	50	50	50	50	50	50	50	50	50	50	50	50	50	50	50	50	50
				50	50	50	50	50	50	50	50	50	50	50	50	50	50	50	50	50	50	50	50	50	50
				50	50	50	50	50	50	50	50	50	50	50	50	50	50	50	50	50	50	50	50	50	50
				50	50	50	50	50	50	50	50	50	50	50	50	50	50	50	50	50	50	50	50	50	50
				50	50	50	50	50	50	50	50	50	50	50	50	50	50	50	50	50	50	50	50	50	50
				50	50	50	50	50	50	50	50	50	50	50	50	50	50	50	50	50	50	50	50	50	50
				50	50	50	50	50	50	50	50	50	50	50	50	50	50	50	50	50	50	50	50	50	50
				50	50	50	50	50	50	50	50	50	50	50	50	50	50	50	50	50	50	50	50	50	50
				50	50	50	50	50	50	50	50	50	50	50	50	50	50	50	50	50	50	50	50	50	50
				50	50	50	50	50	50	50	50	50	50	50	50	50	50	50	50	50	50	50	50	50	50
				50	50	50	50	50	50	50	50	50	50	50	50	50	50	50	50	50	50	50	50	50	50
				50	50	50	50	50	50	50	50	50	50	50	50	50	50	50	50	50	50	50	50	50	50
				50	50	50	50	50	50	50	50	50	50	50	50	50	50	50	50	50	50	50	50	50	50
				50	50	50	50	50	50	50	50	50	50	50	50	50	50	50	50	50	50	50	50	50	50
				50	50	50	50	50	50	50	50	50	50	50	50	50	50	50	50	50	50	50	50	50	50
				50	50	50	50	50	50	50	50	50	50	50	50	50	50	50	50	50	50	50	50	50	50
				50	50	50	50	50	50	50	50	50	50	50	50	50	50	50	50	50	50	50	50	50	50
				75 75 75>;

			PS_Config_Lmt_FW_Diff_N = <
				(-50)	(-50)	(-50)	(-50)	(-50)	(-50)	(-50)	(-50)	(-50)	(-50)	(-50)	(-50)	(-50)	(-50)	(-50)	(-50)	(-50)	(-50)	(-50)	(-50)	(-50)	(-50)
				(-50)	(-50)	(-50)	(-50)	(-50)	(-50)	(-50)	(-50)	(-50)	(-50)	(-50)	(-50)	(-50)	(-50)	(-50)	(-50)	(-50)	(-50)	(-50)	(-50)	(-50)	(-50)
				(-50)	(-50)	(-50)	(-50)	(-50)	(-50)	(-50)	(-50)	(-50)	(-50)	(-50)	(-50)	(-50)	(-50)	(-50)	(-50)	(-50)	(-50)	(-50)	(-50)	(-50)	(-50)
				(-50)	(-50)	(-50)	(-50)	(-50)	(-50)	(-50)	(-50)	(-50)	(-50)	(-50)	(-50)	(-50)	(-50)	(-50)	(-50)	(-50)	(-50)	(-50)	(-50)	(-50)	(-50)
				(-50)	(-50)	(-50)	(-50)	(-50)	(-50)	(-50)	(-50)	(-50)	(-50)	(-50)	(-50)	(-50)	(-50)	(-50)	(-50)	(-50)	(-50)	(-50)	(-50)	(-50)	(-50)
				(-50)	(-50)	(-50)	(-50)	(-50)	(-50)	(-50)	(-50)	(-50)	(-50)	(-50)	(-50)	(-50)	(-50)	(-50)	(-50)	(-50)	(-50)	(-50)	(-50)	(-50)	(-50)
				(-50)	(-50)	(-50)	(-50)	(-50)	(-50)	(-50)	(-50)	(-50)	(-50)	(-50)	(-50)	(-50)	(-50)	(-50)	(-50)	(-50)	(-50)	(-50)	(-50)	(-50)	(-50)
				(-50)	(-50)	(-50)	(-50)	(-50)	(-50)	(-50)	(-50)	(-50)	(-50)	(-50)	(-50)	(-50)	(-50)	(-50)	(-50)	(-50)	(-50)	(-50)	(-50)	(-50)	(-50)
				(-50)	(-50)	(-50)	(-50)	(-50)	(-50)	(-50)	(-50)	(-50)	(-50)	(-50)	(-50)	(-50)	(-50)	(-50)	(-50)	(-50)	(-50)	(-50)	(-50)	(-50)	(-50)
				(-50)	(-50)	(-50)	(-50)	(-50)	(-50)	(-50)	(-50)	(-50)	(-50)	(-50)	(-50)	(-50)	(-50)	(-50)	(-50)	(-50)	(-50)	(-50)	(-50)	(-50)	(-50)
				(-50)	(-50)	(-50)	(-50)	(-50)	(-50)	(-50)	(-50)	(-50)	(-50)	(-50)	(-50)	(-50)	(-50)	(-50)	(-50)	(-50)	(-50)	(-50)	(-50)	(-50)	(-50)
				(-50)	(-50)	(-50)	(-50)	(-50)	(-50)	(-50)	(-50)	(-50)	(-50)	(-50)	(-50)	(-50)	(-50)	(-50)	(-50)	(-50)	(-50)	(-50)	(-50)	(-50)	(-50)
				(-50)	(-50)	(-50)	(-50)	(-50)	(-50)	(-50)	(-50)	(-50)	(-50)	(-50)	(-50)	(-50)	(-50)	(-50)	(-50)	(-50)	(-50)	(-50)	(-50)	(-50)	(-50)
				(-50)	(-50)	(-50)	(-50)	(-50)	(-50)	(-50)	(-50)	(-50)	(-50)	(-50)	(-50)	(-50)	(-50)	(-50)	(-50)	(-50)	(-50)	(-50)	(-50)	(-50)	(-50)
				(-50)	(-50)	(-50)	(-50)	(-50)	(-50)	(-50)	(-50)	(-50)	(-50)	(-50)	(-50)	(-50)	(-50)	(-50)	(-50)	(-50)	(-50)	(-50)	(-50)	(-50)	(-50)
				(-50)	(-50)	(-50)	(-50)	(-50)	(-50)	(-50)	(-50)	(-50)	(-50)	(-50)	(-50)	(-50)	(-50)	(-50)	(-50)	(-50)	(-50)	(-50)	(-50)	(-50)	(-50)
				(-50)	(-50)	(-50)	(-50)	(-50)	(-50)	(-50)	(-50)	(-50)	(-50)	(-50)	(-50)	(-50)	(-50)	(-50)	(-50)	(-50)	(-50)	(-50)	(-50)	(-50)	(-50)
				(-50)	(-50)	(-50)	(-50)	(-50)	(-50)	(-50)	(-50)	(-50)	(-50)	(-50)	(-50)	(-50)	(-50)	(-50)	(-50)	(-50)	(-50)	(-50)	(-50)	(-50)	(-50)
				(-50)	(-50)	(-50)	(-50)	(-50)	(-50)	(-50)	(-50)	(-50)	(-50)	(-50)	(-50)	(-50)	(-50)	(-50)	(-50)	(-50)	(-50)	(-50)	(-50)	(-50)	(-50)
				(-50)	(-50)	(-50)	(-50)	(-50)	(-50)	(-50)	(-50)	(-50)	(-50)	(-50)	(-50)	(-50)	(-50)	(-50)	(-50)	(-50)	(-50)	(-50)	(-50)	(-50)	(-50)
				(-50)	(-50)	(-50)	(-50)	(-50)	(-50)	(-50)	(-50)	(-50)	(-50)	(-50)	(-50)	(-50)	(-50)	(-50)	(-50)	(-50)	(-50)	(-50)	(-50)	(-50)	(-50)
				(-50)	(-50)	(-50)	(-50)	(-50)	(-50)	(-50)	(-50)	(-50)	(-50)	(-50)	(-50)	(-50)	(-50)	(-50)	(-50)	(-50)	(-50)	(-50)	(-50)	(-50)	(-50)
				(-50)	(-50)	(-50)	(-50)	(-50)	(-50)	(-50)	(-50)	(-50)	(-50)	(-50)	(-50)	(-50)	(-50)	(-50)	(-50)	(-50)	(-50)	(-50)	(-50)	(-50)	(-50)
				(-50)	(-50)	(-50)	(-50)	(-50)	(-50)	(-50)	(-50)	(-50)	(-50)	(-50)	(-50)	(-50)	(-50)	(-50)	(-50)	(-50)	(-50)	(-50)	(-50)	(-50)	(-50)
				(-50)	(-50)	(-50)	(-50)	(-50)	(-50)	(-50)	(-50)	(-50)	(-50)	(-50)	(-50)	(-50)	(-50)	(-50)	(-50)	(-50)	(-50)	(-50)	(-50)	(-50)	(-50)
				(-50)	(-50)	(-50)	(-50)	(-50)	(-50)	(-50)	(-50)	(-50)	(-50)	(-50)	(-50)	(-50)	(-50)	(-50)	(-50)	(-50)	(-50)	(-50)	(-50)	(-50)	(-50)
				(-50)	(-50)	(-50)	(-50)	(-50)	(-50)	(-50)	(-50)	(-50)	(-50)	(-50)	(-50)	(-50)	(-50)	(-50)	(-50)	(-50)	(-50)	(-50)	(-50)	(-50)	(-50)
				(-50)	(-50)	(-50)	(-50)	(-50)	(-50)	(-50)	(-50)	(-50)	(-50)	(-50)	(-50)	(-50)	(-50)	(-50)	(-50)	(-50)	(-50)	(-50)	(-50)	(-50)	(-50)
				(-50)	(-50)	(-50)	(-50)	(-50)	(-50)	(-50)	(-50)	(-50)	(-50)	(-50)	(-50)	(-50)	(-50)	(-50)	(-50)	(-50)	(-50)	(-50)	(-50)	(-50)	(-50)
				(-50)	(-50)	(-50)	(-50)	(-50)	(-50)	(-50)	(-50)	(-50)	(-50)	(-50)	(-50)	(-50)	(-50)	(-50)	(-50)	(-50)	(-50)	(-50)	(-50)	(-50)	(-50)
				(-50)	(-50)	(-50)	(-50)	(-50)	(-50)	(-50)	(-50)	(-50)	(-50)	(-50)	(-50)	(-50)	(-50)	(-50)	(-50)	(-50)	(-50)	(-50)	(-50)	(-50)	(-50)
				(-50)	(-50)	(-50)	(-50)	(-50)	(-50)	(-50)	(-50)	(-50)	(-50)	(-50)	(-50)	(-50)	(-50)	(-50)	(-50)	(-50)	(-50)	(-50)	(-50)	(-50)	(-50)
				(-50)	(-50)	(-50)	(-50)	(-50)	(-50)	(-50)	(-50)	(-50)	(-50)	(-50)	(-50)	(-50)	(-50)	(-50)	(-50)	(-50)	(-50)	(-50)	(-50)	(-50)	(-50)
				(-50)	(-50)	(-50)	(-50)	(-50)	(-50)	(-50)	(-50)	(-50)	(-50)	(-50)	(-50)	(-50)	(-50)	(-50)	(-50)	(-50)	(-50)	(-50)	(-50)	(-50)	(-50)
				(-50)	(-50)	(-50)	(-50)	(-50)	(-50)	(-50)	(-50)	(-50)	(-50)	(-50)	(-50)	(-50)	(-50)	(-50)	(-50)	(-50)	(-50)	(-50)	(-50)	(-50)	(-50)
				(-50)	(-50)	(-50)	(-50)	(-50)	(-50)	(-50)	(-50)	(-50)	(-50)	(-50)	(-50)	(-50)	(-50)	(-50)	(-50)	(-50)	(-50)	(-50)	(-50)	(-50)	(-50)
				(-75) (-75) (-75)>;

			PS_Config_Diff_Test_Frame = <50>;

			PS_Config_Lmt_LPWG_Rawdata_P = <
				3840 3840 3840 3840 3840 3840 3840 3840 3840 3840 3840 3840 3840 3840 3840 3840 3840 3840 3840 3840 3840 3840 3840 3840 3840 3840 3840 3840 3840 3840 3840 3840
				3840 3840 3840 3840 3840 3840 3840 3840 3840 3840 3840 3840 3840 3840 3840 3840 3840 3840 3840 3840 3840 3840 3840 3840 3840 3840 3840 3840 3840 3840 3840 3840
				3840 3840 3840 3840 3840 3840 3840 3840 3840 3840 3840 3840 3840 3840 3840 3840 3840 3840 3840 3840 3840 3840 3840 3840 3840 3840 3840 3840 3840 3840 3840 3840
				3840 3840 3840 3840 3840 3840 3840 3840 3840 3840 3840 3840 3840 3840 3840 3840 3840 3840 3840 3840 3840 3840 3840 3840 3840 3840 3840 3840 3840 3840 3840 3840
				3840 3840 3840 3840 3840 3840 3840 3840 3840 3840 3840 3840 3840 3840 3840 3840 3840 3840 3840 3840 3840 3840 3840 3840 3840 3840 3840 3840 3840 3840 3840 3840
				3840 3840 3840 3840 3840 3840 3840 3840 3840 3840 3840 3840 3840 3840 3840 3840 3840 3840 3840 3840 3840 3840 3840 3840 3840 3840 3840 3840 3840 3840 3840 3840
				3840 3840 3840 3840 3840 3840 3840 3840 3840 3840 3840 3840 3840 3840 3840 3840 3840 3840 3840 3840 3840 3840 3840 3840 3840 3840 3840 3840 3840 3840 3840 3840
				3840 3840 3840 3840 3840 3840 3840 3840 3840 3840 3840 3840 3840 3840 3840 3840 3840 3840 3840 3840 3840 3840 3840 3840 3840 3840 3840 3840 3840 3840 3840 3840
				3840 3840 3840 3840 3840 3840 3840 3840 3840 3840 3840 3840 3840 3840 3840 3840 3840 3840 3840 3840 3840 3840 3840 3840 3840 3840 3840 3840 3840 3840 3840 3840
				3840 3840 3840 3840 3840 3840 3840 3840 3840 3840 3840 3840 3840 3840 3840 3840 3840 3840 3840 3840 3840 3840 3840 3840 3840 3840 3840 3840 3840 3840 3840 3840
				3840 3840 3840 3840 3840 3840 3840 3840 3840 3840 3840 3840 3840 3840 3840 3840 3840 3840 3840 3840 3840 3840 3840 3840 3840 3840 3840 3840 3840 3840 3840 3840
				3840 3840 3840 3840 3840 3840 3840 3840 3840 3840 3840 3840 3840 3840 3840 3840 3840 3840 3840 3840 3840 3840 3840 3840 3840 3840 3840 3840 3840 3840 3840 3840
				3840 3840 3840 3840 3840 3840 3840 3840 3840 3840 3840 3840 3840 3840 3840 3840 3840 3840 3840 3840 3840 3840 3840 3840 3840 3840 3840 3840 3840 3840 3840 3840
				3840 3840 3840 3840 3840 3840 3840 3840 3840 3840 3840 3840 3840 3840 3840 3840 3840 3840 3840 3840 3840 3840 3840 3840 3840 3840 3840 3840 3840 3840 3840 3840
				3840 3840 3840 3840 3840 3840 3840 3840 3840 3840 3840 3840 3840 3840 3840 3840 3840 3840 3840 3840 3840 3840 3840 3840 3840 3840 3840 3840 3840 3840 3840 3840
				3840 3840 3840 3840 3840 3840 3840 3840 3840 3840 3840 3840 3840 3840 3840 3840 3840 3840 3840 3840 3840 3840 3840 3840 3840 3840 3840 3840 3840 3840 3840 3840
				3840 3840 3840 3840 3840 3840 3840 3840 3840 3840 3840 3840 3840 3840 3840 3840 3840 3840 3840 3840 3840 3840 3840 3840 3840 3840 3840 3840 3840 3840 3840 3840
				3840 3840 3840 3840 3840 3840 3840 3840 3840 3840 3840 3840 3840 3840 3840 3840 3840 3840 3840 3840 3840 3840 3840 3840 3840 3840 3840 3840 3840 3840 3840 3840
				3840 3840 3840 3840 3840 3840 3840 3840 3840 3840 3840 3840 3840 3840 3840 3840 3840 3840 3840 3840 3840 3840 3840 3840 3840 3840 3840 3840 3840 3840 3840 3840
				3840 3840 3840 3840 3840 3840 3840 3840 3840 3840 3840 3840 3840 3840 3840 3840 3840 3840 3840 3840 3840 3840 3840 3840 3840 3840 3840 3840 3840 3840 3840 3840
				3840 3840 3840 3840 3840 3840 3840 3840 3840 3840 3840 3840 3840 3840 3840 3840 3840 3840 3840 3840 3840 3840 3840 3840 3840 3840 3840 3840 3840 3840 3840 3840
				3840 3840 3840 3840 3840 3840 3840 3840 3840 3840 3840 3840 3840 3840 3840 3840 3840 3840 3840 3840 3840 3840 3840 3840 3840 3840 3840 3840 3840 3840 3840 3840
				3840 3840 3840 3840 3840 3840 3840 3840 3840 3840 3840 3840 3840 3840 3840 3840 3840 3840 3840 3840 3840 3840 3840 3840 3840 3840 3840 3840 3840 3840 3840 3840
				3840 3840 3840 3840 3840 3840 3840 3840 3840 3840 3840 3840 3840 3840 3840 3840 3840 3840 3840 3840 3840 3840 3840 3840 3840 3840 3840 3840 3840 3840 3840 3840
				3840 3840 3840 3840 3840 3840 3840 3840 3840 3840 3840 3840 3840 3840 3840 3840 3840 3840 3840 3840 3840 3840 3840 3840 3840 3840 3840 3840 3840 3840 3840 3840
				3840 3840 3840 3840 3840 3840 3840 3840 3840 3840 3840 3840 3840 3840 3840 3840 3840 3840 3840 3840 3840 3840 3840 3840 3840 3840 3840 3840 3840 3840 3840 3840
				3840 3840 3840 3840 3840 3840 3840 3840 3840 3840 3840 3840 3840 3840 3840 3840 3840 3840 3840 3840 3840 3840 3840 3840 3840 3840 3840 3840 3840 3840 3840 3840
				3840 3840 3840 3840 3840 3840 3840 3840 3840 3840 3840 3840 3840 3840 3840 3840 3840 3840 3840 3840 3840 3840 3840 3840 3840 3840 3840 3840 3840 3840 3840 3840
				3840 3840 3840 3840 3840 3840 3840 3840 3840 3840 3840 3840 3840 3840 3840 3840 3840 3840 3840 3840 3840 3840 3840 3840 3840 3840 3840 3840 3840 3840 3840 3840
				3840 3840 3840 3840 3840 3840 3840 3840 3840 3840 3840 3840 3840 3840 3840 3840 3840 3840 3840 3840 3840 3840 3840 3840 3840 3840 3840 3840 3840 3840 3840 3840
				3840 3840 3840 3840 3840 3840 3840 3840 3840 3840 3840 3840 3840 3840 3840 3840 3840 3840 3840 3840 3840 3840 3840 3840 3840 3840 3840 3840 3840 3840 3840 3840
				3840 3840 3840 3840 3840 3840 3840 3840 3840 3840 3840 3840 3840 3840 3840 3840 3840 3840 3840 3840 3840 3840 3840 3840 3840 3840 3840 3840 3840 3840 3840 3840
				3840 3840 3840 3840 3840 3840 3840 3840 3840 3840 3840 3840 3840 3840 3840 3840 3840 3840 3840 3840 3840 3840 3840 3840 3840 3840 3840 3840 3840 3840 3840 3840
				3840 3840 3840 3840 3840 3840 3840 3840 3840 3840 3840 3840 3840 3840 3840 3840 3840 3840 3840 3840 3840 3840 3840 3840 3840 3840 3840 3840 3840 3840 3840 3840
				3840 3840 3840 3840 3840 3840 3840 3840 3840 3840 3840 3840 3840 3840 3840 3840 3840 3840 3840 3840 3840 3840 3840 3840 3840 3840 3840 3840 3840 3840 3840 3840
				3840 3840 3840 3840 3840 3840 3840 3840 3840 3840 3840 3840 3840 3840 3840 3840 3840 3840 3840 3840 3840 3840 3840 3840 3840 3840 3840 3840 3840 3840 3840 3840
				3840 3840 3840 3840 3840 3840 3840 3840 3840 3840 3840 3840 3840 3840 3840 3840 3840 3840 3840 3840 3840 3840 3840 3840 3840 3840 3840 3840 3840 3840 3840 3840
				3840 3840 3840 3840 3840 3840 3840 3840 3840 3840 3840 3840 3840 3840 3840 3840 3840 3840 3840 3840 3840 3840 3840 3840 3840 3840 3840 3840 3840 3840 3840 3840
				3840 3840 3840 3840 3840 3840 3840 3840 3840 3840 3840 3840 3840 3840 3840 3840 3840 3840 3840 3840 3840 3840 3840 3840 3840 3840 3840 3840 3840 3840 3840 3840
				3840 3840 3840 3840 3840 3840 3840 3840 3840 3840 3840 3840 3840 3840 3840 3840 3840 3840 3840 3840 3840 3840 3840 3840 3840 3840 3840 3840 3840 3840 3840 3840
				3840 3840 3840 3840 3840 3840 3840 3840 3840 3840 3840 3840 3840 3840 3840 3840 3840 3840 3840 3840 3840 3840 3840 3840 3840 3840 3840 3840 3840 3840 3840 3840
				3840 3840 3840 3840 3840 3840 3840 3840 3840 3840 3840 3840 3840 3840 3840 3840 3840 3840 3840 3840 3840 3840 3840 3840 3840 3840 3840 3840 3840 3840 3840 3840
				3840 3840 3840 3840 3840 3840 3840 3840 3840 3840 3840 3840 3840 3840 3840 3840 3840 3840 3840 3840 3840 3840 3840 3840 3840 3840 3840 3840 3840 3840 3840 3840
				3840 3840 3840 3840 3840 3840 3840 3840 3840 3840 3840 3840 3840 3840 3840 3840 3840 3840 3840 3840 3840 3840 3840 3840 3840 3840 3840 3840 3840 3840 3840 3840
				3840 3840 3840 3840 3840 3840 3840 3840 3840 3840 3840 3840 3840 3840 3840 3840 3840 3840 3840 3840 3840 3840 3840 3840 3840 3840 3840 3840 3840 3840 3840 3840
				3840 3840 3840 3840 3840 3840 3840 3840 3840 3840 3840 3840 3840 3840 3840 3840 3840 3840 3840 3840 3840 3840 3840 3840 3840 3840 3840 3840 3840 3840 3840 3840
				3840 3840 3840 3840 3840 3840 3840 3840 3840 3840 3840 3840 3840 3840 3840 3840 3840 3840 3840 3840 3840 3840 3840 3840 3840 3840 3840 3840 3840 3840 3840 3840
				3840 3840 3840 3840 3840 3840 3840 3840 3840 3840 3840 3840 3840 3840 3840 3840 3840 3840 3840 3840 3840 3840 3840 3840 3840 3840 3840 3840 3840 3840 3840 3840
				3840 3840 3840 3840 3840 3840 3840 3840 3840 3840 3840 3840 3840 3840 3840 3840 3840 3840 3840 3840 3840 3840 3840 3840 3840 3840 3840 3840 3840 3840 3840 3840
				3840 3840 3840 3840 3840 3840 3840 3840 3840 3840 3840 3840 3840 3840 3840 3840 3840 3840 3840 3840 3840 3840 3840 3840 3840 3840 3840 3840 3840 3840 3840 3840
				3840 3840 3840>;

			PS_Config_Lmt_LPWG_Rawdata_N = <
				240 240 240 240 240 240 240 240 240 240 240 240 240 240 240 240 240 240 240 240 240 240 240 240 240 240 240 240 240 240 240 240
				240 240 240 240 240 240 240 240 240 240 240 240 240 240 240 240 240 240 240 240 240 240 240 240 240 240 240 240 240 240 240 240
				240 240 240 240 240 240 240 240 240 240 240 240 240 240 240 240 240 240 240 240 240 240 240 240 240 240 240 240 240 240 240 240
				240 240 240 240 240 240 240 240 240 240 240 240 240 240 240 240 240 240 240 240 240 240 240 240 240 240 240 240 240 240 240 240
				240 240 240 240 240 240 240 240 240 240 240 240 240 240 240 240 240 240 240 240 240 240 240 240 240 240 240 240 240 240 240 240
				240 240 240 240 240 240 240 240 240 240 240 240 240 240 240 240 240 240 240 240 240 240 240 240 240 240 240 240 240 240 240 240
				240 240 240 240 240 240 240 240 240 240 240 240 240 240 240 240 240 240 240 240 240 240 240 240 240 240 240 240 240 240 240 240
				240 240 240 240 240 240 240 240 240 240 240 240 240 240 240 240 240 240 240 240 240 240 240 240 240 240 240 240 240 240 240 240
				240 240 240 240 240 240 240 240 240 240 240 240 240 240 240 240 240 240 240 240 240 240 240 240 240 240 240 240 240 240 240 240
				240 240 240 240 240 240 240 240 240 240 240 240 240 240 240 240 240 240 240 240 240 240 240 240 240 240 240 240 240 240 240 240
				240 240 240 240 240 240 240 240 240 240 240 240 240 240 240 240 240 240 240 240 240 240 240 240 240 240 240 240 240 240 240 240
				240 240 240 240 240 240 240 240 240 240 240 240 240 240 240 240 240 240 240 240 240 240 240 240 240 240 240 240 240 240 240 240
				240 240 240 240 240 240 240 240 240 240 240 240 240 240 240 240 240 240 240 240 240 240 240 240 240 240 240 240 240 240 240 240
				240 240 240 240 240 240 240 240 240 240 240 240 240 240 240 240 240 240 240 240 240 240 240 240 240 240 240 240 240 240 240 240
				240 240 240 240 240 240 240 240 240 240 240 240 240 240 240 240 240 240 240 240 240 240 240 240 240 240 240 240 240 240 240 240
				240 240 240 240 240 240 240 240 240 240 240 240 240 240 240 240 240 240 240 240 240 240 240 240 240 240 240 240 240 240 240 240
				240 240 240 240 240 240 240 240 240 240 240 240 240 240 240 240 240 240 240 240 240 240 240 240 240 240 240 240 240 240 240 240
				240 240 240 240 240 240 240 240 240 240 240 240 240 240 240 240 240 240 240 240 240 240 240 240 240 240 240 240 240 240 240 240
				240 240 240 240 240 240 240 240 240 240 240 240 240 240 240 240 240 240 240 240 240 240 240 240 240 240 240 240 240 240 240 240
				240 240 240 240 240 240 240 240 240 240 240 240 240 240 240 240 240 240 240 240 240 240 240 240 240 240 240 240 240 240 240 240
				240 240 240 240 240 240 240 240 240 240 240 240 240 240 240 240 240 240 240 240 240 240 240 240 240 240 240 240 240 240 240 240
				240 240 240 240 240 240 240 240 240 240 240 240 240 240 240 240 240 240 240 240 240 240 240 240 240 240 240 240 240 240 240 240
				240 240 240 240 240 240 240 240 240 240 240 240 240 240 240 240 240 240 240 240 240 240 240 240 240 240 240 240 240 240 240 240
				240 240 240 240 240 240 240 240 240 240 240 240 240 240 240 240 240 240 240 240 240 240 240 240 240 240 240 240 240 240 240 240
				240 240 240 240 240 240 240 240 240 240 240 240 240 240 240 240 240 240 240 240 240 240 240 240 240 240 240 240 240 240 240 240
				240 240 240 240 240 240 240 240 240 240 240 240 240 240 240 240 240 240 240 240 240 240 240 240 240 240 240 240 240 240 240 240
				240 240 240 240 240 240 240 240 240 240 240 240 240 240 240 240 240 240 240 240 240 240 240 240 240 240 240 240 240 240 240 240
				240 240 240 240 240 240 240 240 240 240 240 240 240 240 240 240 240 240 240 240 240 240 240 240 240 240 240 240 240 240 240 240
				240 240 240 240 240 240 240 240 240 240 240 240 240 240 240 240 240 240 240 240 240 240 240 240 240 240 240 240 240 240 240 240
				240 240 240 240 240 240 240 240 240 240 240 240 240 240 240 240 240 240 240 240 240 240 240 240 240 240 240 240 240 240 240 240
				240 240 240 240 240 240 240 240 240 240 240 240 240 240 240 240 240 240 240 240 240 240 240 240 240 240 240 240 240 240 240 240
				240 240 240 240 240 240 240 240 240 240 240 240 240 240 240 240 240 240 240 240 240 240 240 240 240 240 240 240 240 240 240 240
				240 240 240 240 240 240 240 240 240 240 240 240 240 240 240 240 240 240 240 240 240 240 240 240 240 240 240 240 240 240 240 240
				240 240 240 240 240 240 240 240 240 240 240 240 240 240 240 240 240 240 240 240 240 240 240 240 240 240 240 240 240 240 240 240
				240 240 240 240 240 240 240 240 240 240 240 240 240 240 240 240 240 240 240 240 240 240 240 240 240 240 240 240 240 240 240 240
				240 240 240 240 240 240 240 240 240 240 240 240 240 240 240 240 240 240 240 240 240 240 240 240 240 240 240 240 240 240 240 240
				240 240 240 240 240 240 240 240 240 240 240 240 240 240 240 240 240 240 240 240 240 240 240 240 240 240 240 240 240 240 240 240
				240 240 240 240 240 240 240 240 240 240 240 240 240 240 240 240 240 240 240 240 240 240 240 240 240 240 240 240 240 240 240 240
				240 240 240 240 240 240 240 240 240 240 240 240 240 240 240 240 240 240 240 240 240 240 240 240 240 240 240 240 240 240 240 240
				240 240 240 240 240 240 240 240 240 240 240 240 240 240 240 240 240 240 240 240 240 240 240 240 240 240 240 240 240 240 240 240
				240 240 240 240 240 240 240 240 240 240 240 240 240 240 240 240 240 240 240 240 240 240 240 240 240 240 240 240 240 240 240 240
				240 240 240 240 240 240 240 240 240 240 240 240 240 240 240 240 240 240 240 240 240 240 240 240 240 240 240 240 240 240 240 240
				240 240 240 240 240 240 240 240 240 240 240 240 240 240 240 240 240 240 240 240 240 240 240 240 240 240 240 240 240 240 240 240
				240 240 240 240 240 240 240 240 240 240 240 240 240 240 240 240 240 240 240 240 240 240 240 240 240 240 240 240 240 240 240 240
				240 240 240 240 240 240 240 240 240 240 240 240 240 240 240 240 240 240 240 240 240 240 240 240 240 240 240 240 240 240 240 240
				240 240 240 240 240 240 240 240 240 240 240 240 240 240 240 240 240 240 240 240 240 240 240 240 240 240 240 240 240 240 240 240
				240 240 240 240 240 240 240 240 240 240 240 240 240 240 240 240 240 240 240 240 240 240 240 240 240 240 240 240 240 240 240 240
				240 240 240 240 240 240 240 240 240 240 240 240 240 240 240 240 240 240 240 240 240 240 240 240 240 240 240 240 240 240 240 240
				240 240 240 240 240 240 240 240 240 240 240 240 240 240 240 240 240 240 240 240 240 240 240 240 240 240 240 240 240 240 240 240
				240 240 240 240 240 240 240 240 240 240 240 240 240 240 240 240 240 240 240 240 240 240 240 240 240 240 240 240 240 240 240 240
				240 240 240>;

			PS_Config_Lmt_LPWG_Diff_P = <
				75 75 75 75 75 75 75 75 75 75 75 75 75 75 75 75 75 75 75 75 75 75 75 75 75 75 75 75 75 75 75 75
				75 75 75 75 75 75 75 75 75 75 75 75 75 75 75 75 75 75 75 75 75 75 75 75 75 75 75 75 75 75 75 75
				75 75 75 75 75 75 75 75 75 75 75 75 75 75 75 75 75 75 75 75 75 75 75 75 75 75 75 75 75 75 75 75
				75 75 75 75 75 75 75 75 75 75 75 75 75 75 75 75 75 75 75 75 75 75 75 75 75 75 75 75 75 75 75 75
				75 75 75 75 75 75 75 75 75 75 75 75 75 75 75 75 75 75 75 75 75 75 75 75 75 75 75 75 75 75 75 75
				75 75 75 75 75 75 75 75 75 75 75 75 75 75 75 75 75 75 75 75 75 75 75 75 75 75 75 75 75 75 75 75
				75 75 75 75 75 75 75 75 75 75 75 75 75 75 75 75 75 75 75 75 75 75 75 75 75 75 75 75 75 75 75 75
				75 75 75 75 75 75 75 75 75 75 75 75 75 75 75 75 75 75 75 75 75 75 75 75 75 75 75 75 75 75 75 75
				75 75 75 75 75 75 75 75 75 75 75 75 75 75 75 75 75 75 75 75 75 75 75 75 75 75 75 75 75 75 75 75
				75 75 75 75 75 75 75 75 75 75 75 75 75 75 75 75 75 75 75 75 75 75 75 75 75 75 75 75 75 75 75 75
				75 75 75 75 75 75 75 75 75 75 75 75 75 75 75 75 75 75 75 75 75 75 75 75 75 75 75 75 75 75 75 75
				75 75 75 75 75 75 75 75 75 75 75 75 75 75 75 75 75 75 75 75 75 75 75 75 75 75 75 75 75 75 75 75
				75 75 75 75 75 75 75 75 75 75 75 75 75 75 75 75 75 75 75 75 75 75 75 75 75 75 75 75 75 75 75 75
				75 75 75 75 75 75 75 75 75 75 75 75 75 75 75 75 75 75 75 75 75 75 75 75 75 75 75 75 75 75 75 75
				75 75 75 75 75 75 75 75 75 75 75 75 75 75 75 75 75 75 75 75 75 75 75 75 75 75 75 75 75 75 75 75
				75 75 75 75 75 75 75 75 75 75 75 75 75 75 75 75 75 75 75 75 75 75 75 75 75 75 75 75 75 75 75 75
				75 75 75 75 75 75 75 75 75 75 75 75 75 75 75 75 75 75 75 75 75 75 75 75 75 75 75 75 75 75 75 75
				75 75 75 75 75 75 75 75 75 75 75 75 75 75 75 75 75 75 75 75 75 75 75 75 75 75 75 75 75 75 75 75
				75 75 75 75 75 75 75 75 75 75 75 75 75 75 75 75 75 75 75 75 75 75 75 75 75 75 75 75 75 75 75 75
				75 75 75 75 75 75 75 75 75 75 75 75 75 75 75 75 75 75 75 75 75 75 75 75 75 75 75 75 75 75 75 75
				75 75 75 75 75 75 75 75 75 75 75 75 75 75 75 75 75 75 75 75 75 75 75 75 75 75 75 75 75 75 75 75
				75 75 75 75 75 75 75 75 75 75 75 75 75 75 75 75 75 75 75 75 75 75 75 75 75 75 75 75 75 75 75 75
				75 75 75 75 75 75 75 75 75 75 75 75 75 75 75 75 75 75 75 75 75 75 75 75 75 75 75 75 75 75 75 75
				75 75 75 75 75 75 75 75 75 75 75 75 75 75 75 75 75 75 75 75 75 75 75 75 75 75 75 75 75 75 75 75
				75 75 75 75 75 75 75 75 75 75 75 75 75 75 75 75 75 75 75 75 75 75 75 75 75 75 75 75 75 75 75 75
				75 75 75 75 75 75 75 75 75 75 75 75 75 75 75 75 75 75 75 75 75 75 75 75 75 75 75 75 75 75 75 75
				75 75 75 75 75 75 75 75 75 75 75 75 75 75 75 75 75 75 75 75 75 75 75 75 75 75 75 75 75 75 75 75
				75 75 75 75 75 75 75 75 75 75 75 75 75 75 75 75 75 75 75 75 75 75 75 75 75 75 75 75 75 75 75 75
				75 75 75 75 75 75 75 75 75 75 75 75 75 75 75 75 75 75 75 75 75 75 75 75 75 75 75 75 75 75 75 75
				75 75 75 75 75 75 75 75 75 75 75 75 75 75 75 75 75 75 75 75 75 75 75 75 75 75 75 75 75 75 75 75
				75 75 75 75 75 75 75 75 75 75 75 75 75 75 75 75 75 75 75 75 75 75 75 75 75 75 75 75 75 75 75 75
				75 75 75 75 75 75 75 75 75 75 75 75 75 75 75 75 75 75 75 75 75 75 75 75 75 75 75 75 75 75 75 75
				75 75 75 75 75 75 75 75 75 75 75 75 75 75 75 75 75 75 75 75 75 75 75 75 75 75 75 75 75 75 75 75
				75 75 75 75 75 75 75 75 75 75 75 75 75 75 75 75 75 75 75 75 75 75 75 75 75 75 75 75 75 75 75 75
				75 75 75 75 75 75 75 75 75 75 75 75 75 75 75 75 75 75 75 75 75 75 75 75 75 75 75 75 75 75 75 75
				75 75 75 75 75 75 75 75 75 75 75 75 75 75 75 75 75 75 75 75 75 75 75 75 75 75 75 75 75 75 75 75
				75 75 75 75 75 75 75 75 75 75 75 75 75 75 75 75 75 75 75 75 75 75 75 75 75 75 75 75 75 75 75 75
				75 75 75 75 75 75 75 75 75 75 75 75 75 75 75 75 75 75 75 75 75 75 75 75 75 75 75 75 75 75 75 75
				75 75 75 75 75 75 75 75 75 75 75 75 75 75 75 75 75 75 75 75 75 75 75 75 75 75 75 75 75 75 75 75
				75 75 75 75 75 75 75 75 75 75 75 75 75 75 75 75 75 75 75 75 75 75 75 75 75 75 75 75 75 75 75 75
				75 75 75 75 75 75 75 75 75 75 75 75 75 75 75 75 75 75 75 75 75 75 75 75 75 75 75 75 75 75 75 75
				75 75 75 75 75 75 75 75 75 75 75 75 75 75 75 75 75 75 75 75 75 75 75 75 75 75 75 75 75 75 75 75
				75 75 75 75 75 75 75 75 75 75 75 75 75 75 75 75 75 75 75 75 75 75 75 75 75 75 75 75 75 75 75 75
				75 75 75 75 75 75 75 75 75 75 75 75 75 75 75 75 75 75 75 75 75 75 75 75 75 75 75 75 75 75 75 75
				75 75 75 75 75 75 75 75 75 75 75 75 75 75 75 75 75 75 75 75 75 75 75 75 75 75 75 75 75 75 75 75
				75 75 75 75 75 75 75 75 75 75 75 75 75 75 75 75 75 75 75 75 75 75 75 75 75 75 75 75 75 75 75 75
				75 75 75 75 75 75 75 75 75 75 75 75 75 75 75 75 75 75 75 75 75 75 75 75 75 75 75 75 75 75 75 75
				75 75 75 75 75 75 75 75 75 75 75 75 75 75 75 75 75 75 75 75 75 75 75 75 75 75 75 75 75 75 75 75
				75 75 75 75 75 75 75 75 75 75 75 75 75 75 75 75 75 75 75 75 75 75 75 75 75 75 75 75 75 75 75 75
				75 75 75 75 75 75 75 75 75 75 75 75 75 75 75 75 75 75 75 75 75 75 75 75 75 75 75 75 75 75 75 75
				75 75 75>;

			PS_Config_Lmt_LPWG_Diff_N = <
				(-75) (-75) (-75) (-75) (-75) (-75) (-75) (-75) (-75) (-75) (-75) (-75) (-75) (-75) (-75) (-75) (-75) (-75) (-75) (-75) (-75) (-75) (-75) (-75) (-75) (-75) (-75) (-75) (-75) (-75) (-75) (-75) (-75) (-75) (-75) (-75)
				(-75) (-75) (-75) (-75) (-75) (-75) (-75) (-75) (-75) (-75) (-75) (-75) (-75) (-75) (-75) (-75) (-75) (-75) (-75) (-75) (-75) (-75) (-75) (-75) (-75) (-75) (-75) (-75) (-75) (-75) (-75) (-75) (-75) (-75) (-75) (-75)
				(-75) (-75) (-75) (-75) (-75) (-75) (-75) (-75) (-75) (-75) (-75) (-75) (-75) (-75) (-75) (-75) (-75) (-75) (-75) (-75) (-75) (-75) (-75) (-75) (-75) (-75) (-75) (-75) (-75) (-75) (-75) (-75) (-75) (-75) (-75) (-75)
				(-75) (-75) (-75) (-75) (-75) (-75) (-75) (-75) (-75) (-75) (-75) (-75) (-75) (-75) (-75) (-75) (-75) (-75) (-75) (-75) (-75) (-75) (-75) (-75) (-75) (-75) (-75) (-75) (-75) (-75) (-75) (-75) (-75) (-75) (-75) (-75)
				(-75) (-75) (-75) (-75) (-75) (-75) (-75) (-75) (-75) (-75) (-75) (-75) (-75) (-75) (-75) (-75) (-75) (-75) (-75) (-75) (-75) (-75) (-75) (-75) (-75) (-75) (-75) (-75) (-75) (-75) (-75) (-75) (-75) (-75) (-75) (-75)
				(-75) (-75) (-75) (-75) (-75) (-75) (-75) (-75) (-75) (-75) (-75) (-75) (-75) (-75) (-75) (-75) (-75) (-75) (-75) (-75) (-75) (-75) (-75) (-75) (-75) (-75) (-75) (-75) (-75) (-75) (-75) (-75) (-75) (-75) (-75) (-75)
				(-75) (-75) (-75) (-75) (-75) (-75) (-75) (-75) (-75) (-75) (-75) (-75) (-75) (-75) (-75) (-75) (-75) (-75) (-75) (-75) (-75) (-75) (-75) (-75) (-75) (-75) (-75) (-75) (-75) (-75) (-75) (-75) (-75) (-75) (-75) (-75)
				(-75) (-75) (-75) (-75) (-75) (-75) (-75) (-75) (-75) (-75) (-75) (-75) (-75) (-75) (-75) (-75) (-75) (-75) (-75) (-75) (-75) (-75) (-75) (-75) (-75) (-75) (-75) (-75) (-75) (-75) (-75) (-75) (-75) (-75) (-75) (-75)
				(-75) (-75) (-75) (-75) (-75) (-75) (-75) (-75) (-75) (-75) (-75) (-75) (-75) (-75) (-75) (-75) (-75) (-75) (-75) (-75) (-75) (-75) (-75) (-75) (-75) (-75) (-75) (-75) (-75) (-75) (-75) (-75) (-75) (-75) (-75) (-75)
				(-75) (-75) (-75) (-75) (-75) (-75) (-75) (-75) (-75) (-75) (-75) (-75) (-75) (-75) (-75) (-75) (-75) (-75) (-75) (-75) (-75) (-75) (-75) (-75) (-75) (-75) (-75) (-75) (-75) (-75) (-75) (-75) (-75) (-75) (-75) (-75)
				(-75) (-75) (-75) (-75) (-75) (-75) (-75) (-75) (-75) (-75) (-75) (-75) (-75) (-75) (-75) (-75) (-75) (-75) (-75) (-75) (-75) (-75) (-75) (-75) (-75) (-75) (-75) (-75) (-75) (-75) (-75) (-75) (-75) (-75) (-75) (-75)
				(-75) (-75) (-75) (-75) (-75) (-75) (-75) (-75) (-75) (-75) (-75) (-75) (-75) (-75) (-75) (-75) (-75) (-75) (-75) (-75) (-75) (-75) (-75) (-75) (-75) (-75) (-75) (-75) (-75) (-75) (-75) (-75) (-75) (-75) (-75) (-75)
				(-75) (-75) (-75) (-75) (-75) (-75) (-75) (-75) (-75) (-75) (-75) (-75) (-75) (-75) (-75) (-75) (-75) (-75) (-75) (-75) (-75) (-75) (-75) (-75) (-75) (-75) (-75) (-75) (-75) (-75) (-75) (-75) (-75) (-75) (-75) (-75)
				(-75) (-75) (-75) (-75) (-75) (-75) (-75) (-75) (-75) (-75) (-75) (-75) (-75) (-75) (-75) (-75) (-75) (-75) (-75) (-75) (-75) (-75) (-75) (-75) (-75) (-75) (-75) (-75) (-75) (-75) (-75) (-75) (-75) (-75) (-75) (-75)
				(-75) (-75) (-75) (-75) (-75) (-75) (-75) (-75) (-75) (-75) (-75) (-75) (-75) (-75) (-75) (-75) (-75) (-75) (-75) (-75) (-75) (-75) (-75) (-75) (-75) (-75) (-75) (-75) (-75) (-75) (-75) (-75) (-75) (-75) (-75) (-75)
				(-75) (-75) (-75) (-75) (-75) (-75) (-75) (-75) (-75) (-75) (-75) (-75) (-75) (-75) (-75) (-75) (-75) (-75) (-75) (-75) (-75) (-75) (-75) (-75) (-75) (-75) (-75) (-75) (-75) (-75) (-75) (-75) (-75) (-75) (-75) (-75)
				(-75) (-75) (-75) (-75) (-75) (-75) (-75) (-75) (-75) (-75) (-75) (-75) (-75) (-75) (-75) (-75) (-75) (-75) (-75) (-75) (-75) (-75) (-75) (-75) (-75) (-75) (-75) (-75) (-75) (-75) (-75) (-75) (-75) (-75) (-75) (-75)
				(-75) (-75) (-75) (-75) (-75) (-75) (-75) (-75) (-75) (-75) (-75) (-75) (-75) (-75) (-75) (-75) (-75) (-75) (-75) (-75) (-75) (-75) (-75) (-75) (-75) (-75) (-75) (-75) (-75) (-75) (-75) (-75) (-75) (-75) (-75) (-75)
				(-75) (-75) (-75) (-75) (-75) (-75) (-75) (-75) (-75) (-75) (-75) (-75) (-75) (-75) (-75) (-75) (-75) (-75) (-75) (-75) (-75) (-75) (-75) (-75) (-75) (-75) (-75) (-75) (-75) (-75) (-75) (-75) (-75) (-75) (-75) (-75)
				(-75) (-75) (-75) (-75) (-75) (-75) (-75) (-75) (-75) (-75) (-75) (-75) (-75) (-75) (-75) (-75) (-75) (-75) (-75) (-75) (-75) (-75) (-75) (-75) (-75) (-75) (-75) (-75) (-75) (-75) (-75) (-75) (-75) (-75) (-75) (-75)
				(-75) (-75) (-75) (-75) (-75) (-75) (-75) (-75) (-75) (-75) (-75) (-75) (-75) (-75) (-75) (-75) (-75) (-75) (-75) (-75) (-75) (-75) (-75) (-75) (-75) (-75) (-75) (-75) (-75) (-75) (-75) (-75) (-75) (-75) (-75) (-75)
				(-75) (-75) (-75) (-75) (-75) (-75) (-75) (-75) (-75) (-75) (-75) (-75) (-75) (-75) (-75) (-75) (-75) (-75) (-75) (-75) (-75) (-75) (-75) (-75) (-75) (-75) (-75) (-75) (-75) (-75) (-75) (-75) (-75) (-75) (-75) (-75)
				(-75) (-75) (-75) (-75) (-75) (-75) (-75) (-75) (-75) (-75) (-75) (-75) (-75) (-75) (-75) (-75) (-75) (-75) (-75) (-75) (-75) (-75) (-75) (-75) (-75) (-75) (-75) (-75) (-75) (-75) (-75) (-75) (-75) (-75) (-75) (-75)
				(-75) (-75) (-75) (-75) (-75) (-75) (-75) (-75) (-75) (-75) (-75) (-75) (-75) (-75) (-75) (-75) (-75) (-75) (-75) (-75) (-75) (-75) (-75) (-75) (-75) (-75) (-75) (-75) (-75) (-75) (-75) (-75) (-75) (-75) (-75) (-75)
				(-75) (-75) (-75) (-75) (-75) (-75) (-75) (-75) (-75) (-75) (-75) (-75) (-75) (-75) (-75) (-75) (-75) (-75) (-75) (-75) (-75) (-75) (-75) (-75) (-75) (-75) (-75) (-75) (-75) (-75) (-75) (-75) (-75) (-75) (-75) (-75)
				(-75) (-75) (-75) (-75) (-75) (-75) (-75) (-75) (-75) (-75) (-75) (-75) (-75) (-75) (-75) (-75) (-75) (-75) (-75) (-75) (-75) (-75) (-75) (-75) (-75) (-75) (-75) (-75) (-75) (-75) (-75) (-75) (-75) (-75) (-75) (-75)
				(-75) (-75) (-75) (-75) (-75) (-75) (-75) (-75) (-75) (-75) (-75) (-75) (-75) (-75) (-75) (-75) (-75) (-75) (-75) (-75) (-75) (-75) (-75) (-75) (-75) (-75) (-75) (-75) (-75) (-75) (-75) (-75) (-75) (-75) (-75) (-75)
				(-75) (-75) (-75) (-75) (-75) (-75) (-75) (-75) (-75) (-75) (-75) (-75) (-75) (-75) (-75) (-75) (-75) (-75) (-75) (-75) (-75) (-75) (-75) (-75) (-75) (-75) (-75) (-75) (-75) (-75) (-75) (-75) (-75) (-75) (-75) (-75)
				(-75) (-75) (-75) (-75) (-75) (-75) (-75) (-75) (-75) (-75) (-75) (-75) (-75) (-75) (-75) (-75) (-75) (-75) (-75) (-75) (-75) (-75) (-75) (-75) (-75) (-75) (-75) (-75) (-75) (-75) (-75) (-75) (-75) (-75) (-75) (-75)
				(-75) (-75) (-75) (-75) (-75) (-75) (-75) (-75) (-75) (-75) (-75) (-75) (-75) (-75) (-75) (-75) (-75) (-75) (-75) (-75) (-75) (-75) (-75) (-75) (-75) (-75) (-75) (-75) (-75) (-75) (-75) (-75) (-75) (-75) (-75) (-75)
				(-75) (-75) (-75) (-75) (-75) (-75) (-75) (-75) (-75) (-75) (-75) (-75) (-75) (-75) (-75) (-75) (-75) (-75) (-75) (-75) (-75) (-75) (-75) (-75) (-75) (-75) (-75) (-75) (-75) (-75) (-75) (-75) (-75) (-75) (-75) (-75)
				(-75) (-75) (-75) (-75) (-75) (-75) (-75) (-75) (-75) (-75) (-75) (-75) (-75) (-75) (-75) (-75) (-75) (-75) (-75) (-75) (-75) (-75) (-75) (-75) (-75) (-75) (-75) (-75) (-75) (-75) (-75) (-75) (-75) (-75) (-75) (-75)
				(-75) (-75) (-75) (-75) (-75) (-75) (-75) (-75) (-75) (-75) (-75) (-75) (-75) (-75) (-75) (-75) (-75) (-75) (-75) (-75) (-75) (-75) (-75) (-75) (-75) (-75) (-75) (-75) (-75) (-75) (-75) (-75) (-75) (-75) (-75) (-75)
				(-75) (-75) (-75) (-75) (-75) (-75) (-75) (-75) (-75) (-75) (-75) (-75) (-75) (-75) (-75) (-75) (-75) (-75) (-75) (-75) (-75) (-75) (-75) (-75) (-75) (-75) (-75) (-75) (-75) (-75) (-75) (-75) (-75) (-75) (-75) (-75)
				(-75) (-75) (-75) (-75) (-75) (-75) (-75) (-75) (-75) (-75) (-75) (-75) (-75) (-75) (-75) (-75) (-75) (-75) (-75) (-75) (-75) (-75) (-75) (-75) (-75) (-75) (-75) (-75) (-75) (-75) (-75) (-75) (-75) (-75) (-75) (-75)
				(-75) (-75) (-75) (-75) (-75) (-75) (-75) (-75) (-75) (-75) (-75) (-75) (-75) (-75) (-75) (-75) (-75) (-75) (-75) (-75) (-75) (-75) (-75) (-75) (-75) (-75) (-75) (-75) (-75) (-75) (-75) (-75) (-75) (-75) (-75) (-75)
				(-75) (-75) (-75) (-75) (-75) (-75) (-75) (-75) (-75) (-75) (-75) (-75) (-75) (-75) (-75) (-75) (-75) (-75) (-75) (-75) (-75) (-75) (-75) (-75) (-75) (-75) (-75) (-75) (-75) (-75) (-75) (-75) (-75) (-75) (-75) (-75)
				(-75) (-75) (-75) (-75) (-75) (-75) (-75) (-75) (-75) (-75) (-75) (-75) (-75) (-75) (-75) (-75) (-75) (-75) (-75) (-75) (-75) (-75) (-75) (-75) (-75) (-75) (-75) (-75) (-75) (-75) (-75) (-75) (-75) (-75) (-75) (-75)
				(-75) (-75) (-75) (-75) (-75) (-75) (-75) (-75) (-75) (-75) (-75) (-75) (-75) (-75) (-75) (-75) (-75) (-75) (-75) (-75) (-75) (-75) (-75) (-75) (-75) (-75) (-75) (-75) (-75) (-75) (-75) (-75) (-75) (-75) (-75) (-75)
				(-75) (-75) (-75) (-75) (-75) (-75) (-75) (-75) (-75) (-75) (-75) (-75) (-75) (-75) (-75) (-75) (-75) (-75) (-75) (-75) (-75) (-75) (-75) (-75) (-75) (-75) (-75) (-75) (-75) (-75) (-75) (-75) (-75) (-75) (-75) (-75)
				(-75) (-75) (-75) (-75) (-75) (-75) (-75) (-75) (-75) (-75) (-75) (-75) (-75) (-75) (-75) (-75) (-75) (-75) (-75) (-75) (-75) (-75) (-75) (-75) (-75) (-75) (-75) (-75) (-75) (-75) (-75) (-75) (-75) (-75) (-75) (-75)
				(-75) (-75) (-75) (-75) (-75) (-75) (-75) (-75) (-75) (-75) (-75) (-75) (-75) (-75) (-75) (-75) (-75) (-75) (-75) (-75) (-75) (-75) (-75) (-75) (-75) (-75) (-75) (-75) (-75) (-75) (-75) (-75) (-75) (-75) (-75) (-75)
				(-75) (-75) (-75) (-75) (-75) (-75) (-75) (-75) (-75) (-75) (-75) (-75) (-75) (-75) (-75) (-75) (-75) (-75) (-75) (-75) (-75) (-75) (-75) (-75) (-75) (-75) (-75) (-75) (-75) (-75) (-75) (-75) (-75) (-75) (-75) (-75)
				(-75) (-75) (-75) (-75) (-75) (-75) (-75) (-75) (-75) (-75) (-75) (-75) (-75) (-75) (-75) (-75) (-75) (-75) (-75) (-75) (-75) (-75) (-75) (-75) (-75) (-75) (-75) (-75) (-75) (-75) (-75) (-75) (-75) (-75) (-75) (-75)
				(-75) (-75) (-75) (-75) (-75) (-75) (-75) (-75) (-75) (-75) (-75) (-75) (-75) (-75) (-75) (-75) (-75) (-75) (-75) (-75) (-75) (-75) (-75) (-75) (-75) (-75) (-75) (-75) (-75) (-75) (-75) (-75) (-75) (-75) (-75) (-75)
				(-75) (-75) (-75) (-75) (-75) (-75) (-75) (-75) (-75) (-75) (-75) (-75) (-75) (-75) (-75) (-75) (-75) (-75) (-75) (-75) (-75) (-75) (-75) (-75) (-75) (-75) (-75) (-75) (-75) (-75) (-75) (-75) (-75) (-75) (-75) (-75)
				(-75) (-75) (-75) (-75) (-75) (-75) (-75) (-75) (-75) (-75) (-75) (-75) (-75) (-75) (-75) (-75) (-75) (-75) (-75) (-75) (-75) (-75) (-75) (-75) (-75) (-75) (-75) (-75) (-75) (-75) (-75) (-75) (-75) (-75) (-75) (-75)
				(-75) (-75) (-75) (-75) (-75) (-75) (-75) (-75) (-75) (-75) (-75) (-75) (-75) (-75) (-75) (-75) (-75) (-75) (-75) (-75) (-75) (-75) (-75) (-75) (-75) (-75) (-75) (-75) (-75) (-75) (-75) (-75) (-75) (-75) (-75) (-75)
				(-75) (-75) (-75) (-75) (-75) (-75) (-75) (-75) (-75) (-75) (-75) (-75) (-75) (-75) (-75) (-75) (-75) (-75) (-75) (-75) (-75) (-75) (-75) (-75) (-75) (-75) (-75) (-75) (-75) (-75) (-75) (-75) (-75) (-75) (-75) (-75)
				(-75) (-75) (-75) (-75) (-75) (-75) (-75) (-75) (-75) (-75) (-75) (-75) (-75) (-75) (-75) (-75) (-75) (-75) (-75) (-75) (-75) (-75) (-75) (-75) (-75) (-75) (-75) (-75) (-75) (-75) (-75) (-75) (-75) (-75) (-75) (-75)
				(-75) (-75) (-75)>;

			/* FDM config */
			FDM_X_Channel = <2>;

			PS_Config_Lmt_FDM_Rawdata_P = <
				900 900
				900 900
				900 900
				900 900
				900 900
				900 900
				900 900
				900 900
				900 900
				900 900
				900 900
				900 900
				900 900
				900 900
				900 900
				900 900
				900 900
				900 900
				900 900
				900 900
				900 900
				900 900
				900 900
				900 900
				900 900
				900 900
				900 900
				900 900
				900 900
				900 900
				900 900
				900 900
				900 900
				900 900
				900 900
				900 900
				900 900
				900 900
				900 900
				900 900
				900 900
				900 900
				900 900
				900 900
				900 900
				900 900
				900 900
				900 900
				900 900
				900 900>;

			PS_Config_Lmt_FDM_Rawdata_N = <
				50 50
				50 50
				50 50
				50 50
				50 50
				50 50
				50 50
				50 50
				50 50
				50 50
				50 50
				50 50
				50 50
				50 50
				50 50
				50 50
				50 50
				50 50
				50 50
				50 50
				50 50
				50 50
				50 50
				50 50
				50 50
				50 50
				50 50
				50 50
				50 50
				50 50
				50 50
				50 50
				50 50
				50 50
				50 50
				50 50
				50 50
				50 50
				50 50
				50 50
				50 50
				50 50
				50 50
				50 50
				50 50
				50 50
				50 50
				50 50
				50 50
				50 50>;

			PS_Config_FDM_Noise_Test_Frame = <50>;
			PS_Config_Lmt_FDM_Diff_P = <
				180 180
				180 180
				180 180
				180 180
				180 180
				180 180
				180 180
				180 180
				180 180
				180 180
				180 180
				180 180
				180 180
				180 180
				180 180
				180 180
				180 180
				180 180
				180 180
				180 180
				180 180
				180 180
				180 180
				180 180
				180 180
				180 180
				180 180
				180 180
				180 180
				180 180
				180 180
				180 180
				180 180
				180 180
				180 180
				180 180
				180 180
				180 180
				180 180
				180 180
				180 180
				180 180
				180 180
				180 180
				180 180
				180 180
				180 180
				180 180
				180 180
				180 180>;

			PS_Config_Lmt_FDM_Diff_N = <
				(-180) (-180)
				(-180) (-180)
				(-180) (-180)
				(-180) (-180)
				(-180) (-180)
				(-180) (-180)
				(-180) (-180)
				(-180) (-180)
				(-180) (-180)
				(-180) (-180)
				(-180) (-180)
				(-180) (-180)
				(-180) (-180)
				(-180) (-180)
				(-180) (-180)
				(-180) (-180)
				(-180) (-180)
				(-180) (-180)
				(-180) (-180)
				(-180) (-180)
				(-180) (-180)
				(-180) (-180)
				(-180) (-180)
				(-180) (-180)
				(-180) (-180)
				(-180) (-180)
				(-180) (-180)
				(-180) (-180)
				(-180) (-180)
				(-180) (-180)
				(-180) (-180)
				(-180) (-180)
				(-180) (-180)
				(-180) (-180)
				(-180) (-180)
				(-180) (-180)
				(-180) (-180)
				(-180) (-180)
				(-180) (-180)
				(-180) (-180)
				(-180) (-180)
				(-180) (-180)
				(-180) (-180)
				(-180) (-180)
				(-180) (-180)
				(-180) (-180)
				(-180) (-180)
				(-180) (-180)
				(-180) (-180)
				(-180) (-180)>;
		};

		/*for Samsung OT9 HSD8.68" module*/
		novatek-mp-criteria-724B@0 {
			#address-cells = <1>;
			#size-cells = <0>;
			compatible = "novatek-mp-criteria-724B";

			/* sec cmd test config */
			open_test_spec = <(-511) 5120>;
			short_test_spec = <10000 14008>;
			diff_test_frame = <50>;
			/* sec cmd fdm test config */
			fdm_x_num = <2>;
			fdm_diff_test_frame = <50>;

			/* MP Config */
			IC_X_CFG_SIZE = <22>;
			IC_Y_CFG_SIZE = <36>;
			IC_KEY_CFG_SIZE = <4>;
			X_Channel = <22>;
			Y_Channel = <36>;
			AIN_X = <0 1 2 3 4 5 6 7 8 9 10 11 12 13 14 15 16 17 18 19 20 21>;
			AIN_Y = <0 1 2 3 4 5 6 7 8 9 10 11 12 13 14 15 16 17
						18 19 20 21 22 23 24 25 26 27 28 29 30 31 32 33 34 35>;
			AIN_KEY = <0 1 2 0xFF 0xFF 0xFF 0xFF 0xFF>;

			/* MP Criteria */
			PS_Config_Lmt_Short_Rawdata_P = <
				14008 14008 14008 14008 14008 14008 14008 14008 14008 14008 14008 14008 14008 14008 14008 14008 14008 14008 14008 14008 14008 14008
				14008 14008 14008 14008 14008 14008 14008 14008 14008 14008 14008 14008 14008 14008 14008 14008 14008 14008 14008 14008 14008 14008
				14008 14008 14008 14008 14008 14008 14008 14008 14008 14008 14008 14008 14008 14008 14008 14008 14008 14008 14008 14008 14008 14008
				14008 14008 14008 14008 14008 14008 14008 14008 14008 14008 14008 14008 14008 14008 14008 14008 14008 14008 14008 14008 14008 14008
				14008 14008 14008 14008 14008 14008 14008 14008 14008 14008 14008 14008 14008 14008 14008 14008 14008 14008 14008 14008 14008 14008
				14008 14008 14008 14008 14008 14008 14008 14008 14008 14008 14008 14008 14008 14008 14008 14008 14008 14008 14008 14008 14008 14008
				14008 14008 14008 14008 14008 14008 14008 14008 14008 14008 14008 14008 14008 14008 14008 14008 14008 14008 14008 14008 14008 14008
				14008 14008 14008 14008 14008 14008 14008 14008 14008 14008 14008 14008 14008 14008 14008 14008 14008 14008 14008 14008 14008 14008
				14008 14008 14008 14008 14008 14008 14008 14008 14008 14008 14008 14008 14008 14008 14008 14008 14008 14008 14008 14008 14008 14008
				14008 14008 14008 14008 14008 14008 14008 14008 14008 14008 14008 14008 14008 14008 14008 14008 14008 14008 14008 14008 14008 14008
				14008 14008 14008 14008 14008 14008 14008 14008 14008 14008 14008 14008 14008 14008 14008 14008 14008 14008 14008 14008 14008 14008
				14008 14008 14008 14008 14008 14008 14008 14008 14008 14008 14008 14008 14008 14008 14008 14008 14008 14008 14008 14008 14008 14008
				14008 14008 14008 14008 14008 14008 14008 14008 14008 14008 14008 14008 14008 14008 14008 14008 14008 14008 14008 14008 14008 14008
				14008 14008 14008 14008 14008 14008 14008 14008 14008 14008 14008 14008 14008 14008 14008 14008 14008 14008 14008 14008 14008 14008
				14008 14008 14008 14008 14008 14008 14008 14008 14008 14008 14008 14008 14008 14008 14008 14008 14008 14008 14008 14008 14008 14008
				14008 14008 14008 14008 14008 14008 14008 14008 14008 14008 14008 14008 14008 14008 14008 14008 14008 14008 14008 14008 14008 14008
				14008 14008 14008 14008 14008 14008 14008 14008 14008 14008 14008 14008 14008 14008 14008 14008 14008 14008 14008 14008 14008 14008
				14008 14008 14008 14008 14008 14008 14008 14008 14008 14008 14008 14008 14008 14008 14008 14008 14008 14008 14008 14008 14008 14008
				14008 14008 14008 14008 14008 14008 14008 14008 14008 14008 14008 14008 14008 14008 14008 14008 14008 14008 14008 14008 14008 14008
				14008 14008 14008 14008 14008 14008 14008 14008 14008 14008 14008 14008 14008 14008 14008 14008 14008 14008 14008 14008 14008 14008
				14008 14008 14008 14008 14008 14008 14008 14008 14008 14008 14008 14008 14008 14008 14008 14008 14008 14008 14008 14008 14008 14008
				14008 14008 14008 14008 14008 14008 14008 14008 14008 14008 14008 14008 14008 14008 14008 14008 14008 14008 14008 14008 14008 14008
				14008 14008 14008 14008 14008 14008 14008 14008 14008 14008 14008 14008 14008 14008 14008 14008 14008 14008 14008 14008 14008 14008
				14008 14008 14008 14008 14008 14008 14008 14008 14008 14008 14008 14008 14008 14008 14008 14008 14008 14008 14008 14008 14008 14008
				14008 14008 14008 14008 14008 14008 14008 14008 14008 14008 14008 14008 14008 14008 14008 14008 14008 14008 14008 14008 14008 14008
				14008 14008 14008 14008 14008 14008 14008 14008 14008 14008 14008 14008 14008 14008 14008 14008 14008 14008 14008 14008 14008 14008
				14008 14008 14008 14008 14008 14008 14008 14008 14008 14008 14008 14008 14008 14008 14008 14008 14008 14008 14008 14008 14008 14008
				14008 14008 14008 14008 14008 14008 14008 14008 14008 14008 14008 14008 14008 14008 14008 14008 14008 14008 14008 14008 14008 14008
				14008 14008 14008 14008 14008 14008 14008 14008 14008 14008 14008 14008 14008 14008 14008 14008 14008 14008 14008 14008 14008 14008
				14008 14008 14008 14008 14008 14008 14008 14008 14008 14008 14008 14008 14008 14008 14008 14008 14008 14008 14008 14008 14008 14008
				14008 14008 14008 14008 14008 14008 14008 14008 14008 14008 14008 14008 14008 14008 14008 14008 14008 14008 14008 14008 14008 14008
				14008 14008 14008 14008 14008 14008 14008 14008 14008 14008 14008 14008 14008 14008 14008 14008 14008 14008 14008 14008 14008 14008
				14008 14008 14008 14008 14008 14008 14008 14008 14008 14008 14008 14008 14008 14008 14008 14008 14008 14008 14008 14008 14008 14008
				14008 14008 14008 14008 14008 14008 14008 14008 14008 14008 14008 14008 14008 14008 14008 14008 14008 14008 14008 14008 14008 14008
				14008 14008 14008 14008 14008 14008 14008 14008 14008 14008 14008 14008 14008 14008 14008 14008 14008 14008 14008 14008 14008 14008
				14008 14008 14008 14008 14008 14008 14008 14008 14008 14008 14008 14008 14008 14008 14008 14008 14008 14008 14008 14008 14008 14008
				14008 14008 14008>;

			PS_Config_Lmt_Short_Rawdata_N = <
				10100	10100	10100	10100	10100	10100	10100	10100	10100	10100	10100	10100	10100	10100	10100	10100	10100	10100	10100	10100	10100	10100
				10100	10100	10100	10100	10100	10100	10100	10100	10100	10100	10100	10100	10100	10100	10100	10100	10100	10100	10100	10100	10100	10100
				10100	10100	10100	10100	10100	10100	10100	10100	10100	10100	10100	10100	10100	10100	10100	10100	10100	10100	10100	10100	10100	10100
				10100	10100	10100	10100	10100	10100	10100	10100	10100	10100	10100	10100	10100	10100	10100	10100	10100	10100	10100	10100	10100	10100
				10100	10100	10100	10100	10100	10100	10100	10100	10100	10100	10100	10100	10100	10100	10100	10100	10100	10100	10100	10100	10100	10100
				10100	10100	10100	10100	10100	10100	10100	10100	10100	10100	10100	10100	10100	10100	10100	10100	10100	10100	10100	10100	10100	10100
				10100	10100	10100	10100	10100	10100	10100	10100	10100	10100	10100	10100	10100	10100	10100	10100	10100	10100	10100	10100	10100	10100
				10100	10100	10100	10100	10100	10100	10100	10100	10100	10100	10100	10100	10100	10100	10100	10100	10100	10100	10100	10100	10100	10100
				10100	10100	10100	10100	10100	10100	10100	10100	10100	10100	10100	10100	10100	10100	10100	10100	10100	10100	10100	10100	10100	10100
				10100	10100	10100	10100	10100	10100	10100	10100	10100	10100	10100	10100	10100	10100	10100	10100	10100	10100	10100	10100	10100	10100
				10100	10100	10100	10100	10100	10100	10100	10100	10100	10100	10100	10100	10100	10100	10100	10100	10100	10100	10100	10100	10100	10100
				10100	10100	10100	10100	10100	10100	10100	10100	10100	10100	10100	10100	10100	10100	10100	10100	10100	10100	10100	10100	10100	10100
				10100	10100	10100	10100	10100	10100	10100	10100	10100	10100	10100	10100	10100	10100	10100	10100	10100	10100	10100	10100	10100	10100
				10100	10100	10100	10100	10100	10100	10100	10100	10100	10100	10100	10100	10100	10100	10100	10100	10100	10100	10100	10100	10100	10100
				10100	10100	10100	10100	10100	10100	10100	10100	10100	10100	10100	10100	10100	10100	10100	10100	10100	10100	10100	10100	10100	10100
				10100	10100	10100	10100	10100	10100	10100	10100	10100	10100	10100	10100	10100	10100	10100	10100	10100	10100	10100	10100	10100	10100
				10100	10100	10100	10100	10100	10100	10100	10100	10100	10100	10100	10100	10100	10100	10100	10100	10100	10100	10100	10100	10100	10100
				10100	10100	10100	10100	10100	10100	10100	10100	10100	10100	10100	10100	10100	10100	10100	10100	10100	10100	10100	10100	10100	10100
				10100	10100	10100	10100	10100	10100	10100	10100	10100	10100	10100	10100	10100	10100	10100	10100	10100	10100	10100	10100	10100	10100
				10100	10100	10100	10100	10100	10100	10100	10100	10100	10100	10100	10100	10100	10100	10100	10100	10100	10100	10100	10100	10100	10100
				10100	10100	10100	10100	10100	10100	10100	10100	10100	10100	10100	10100	10100	10100	10100	10100	10100	10100	10100	10100	10100	10100
				10100	10100	10100	10100	10100	10100	10100	10100	10100	10100	10100	10100	10100	10100	10100	10100	10100	10100	10100	10100	10100	10100
				10100	10100	10100	10100	10100	10100	10100	10100	10100	10100	10100	10100	10100	10100	10100	10100	10100	10100	10100	10100	10100	10100
				10100	10100	10100	10100	10100	10100	10100	10100	10100	10100	10100	10100	10100	10100	10100	10100	10100	10100	10100	10100	10100	10100
				10100	10100	10100	10100	10100	10100	10100	10100	10100	10100	10100	10100	10100	10100	10100	10100	10100	10100	10100	10100	10100	10100
				10100	10100	10100	10100	10100	10100	10100	10100	10100	10100	10100	10100	10100	10100	10100	10100	10100	10100	10100	10100	10100	10100
				10100	10100	10100	10100	10100	10100	10100	10100	10100	10100	10100	10100	10100	10100	10100	10100	10100	10100	10100	10100	10100	10100
				10100	10100	10100	10100	10100	10100	10100	10100	10100	10100	10100	10100	10100	10100	10100	10100	10100	10100	10100	10100	10100	10100
				10100	10100	10100	10100	10100	10100	10100	10100	10100	10100	10100	10100	10100	10100	10100	10100	10100	10100	10100	10100	10100	10100
				10100	10100	10100	10100	10100	10100	10100	10100	10100	10100	10100	10100	10100	10100	10100	10100	10100	10100	10100	10100	10100	10100
				10100	10100	10100	10100	10100	10100	10100	10100	10100	10100	10100	10100	10100	10100	10100	10100	10100	10100	10100	10100	10100	10100
				10100	10100	10100	10100	10100	10100	10100	10100	10100	10100	10100	10100	10100	10100	10100	10100	10100	10100	10100	10100	10100	10100
				10100	10100	10100	10100	10100	10100	10100	10100	10100	10100	10100	10100	10100	10100	10100	10100	10100	10100	10100	10100	10100	10100
				10100	10100	10100	10100	10100	10100	10100	10100	10100	10100	10100	10100	10100	10100	10100	10100	10100	10100	10100	10100	10100	10100
				10100	10100	10100	10100	10100	10100	10100	10100	10100	10100	10100	10100	10100	10100	10100	10100	10100	10100	10100	10100	10100	10100
				10100	10100	10100	10100	10100	10100	10100	10100	10100	10100	10100	10100	10100	10100	10100	10100	10100	10100	10100	10100	10100	10100
				10000 10000 10000>;

			PS_Config_Lmt_Open_Rawdata_P = <
				3015	3038	3064	2945	3127	3094	3035	2970	3238	3080	2947	2968	3123	2983	2926	3109	3018	2980	2983	3117	3082	3029
				3052	2982	3029	2966	3124	3116	2949	2912	3144	3036	2951	2930	3126	2954	2935	3239	3071	2968	2928	3063	2986	3040
				3133	3092	3117	2991	2902	3158	3012	2942	3250	3162	2871	3035	3183	3126	2977	3221	3087	3021	3003	3138	3110	2941
				3056	3001	3064	3004	2965	3166	3130	3021	3239	3080	3007	2987	3143	3015	2977	3201	3075	3004	2968	3155	3007	3074
				3095	3103	3185	3105	3001	3267	3099	2989	3291	2958	3081	3050	3218	3145	3068	3292	3178	3003	3029	3178	2942	3127
				3164	3078	3075	3082	2993	3217	3123	3061	3329	3201	3015	3021	3243	3053	3025	3220	3129	3050	3017	3199	3085	3096
				3124	3105	3091	3172	3057	3325	3182	2882	3150	3207	3138	3063	3259	3152	3099	3060	3211	3082	2867	3011	3115	3187
				3187	3133	3176	3071	3063	3281	3137	3077	3344	3225	3060	3075	3297	3157	3063	3029	3196	3057	3031	3285	3165	3178
				3162	3124	3192	3207	3131	3390	3099	3108	3005	3263	3120	3071	3273	3190	3157	3133	3271	3077	3074	3255	3157	3235
				3192	3126	3218	3119	3032	3267	3189	3112	3050	3290	3225	3080	3411	3250	3124	3043	3187	3124	3102	3235	3138	3210
				3225	3092	3232	3193	2984	3288	3323	3190	3096	3379	3200	3130	3386	3257	3189	3022	3182	3262	3197	3315	3238	3204
				3238	3147	3241	3253	3182	3403	3241	3176	3102	3320	3253	3154	3360	3264	3123	3127	3330	3165	3158	3236	3180	3248
				3340	3199	3333	3204	3151	3446	3283	3269	3182	3448	3304	3243	3460	3361	3078	3180	3348	3264	3207	3201	3260	3266
				3315	3115	3210	3299	3221	3480	3375	3201	3178	3406	3263	3201	3392	3246	3239	3192	3407	3278	3176	3155	3250	3264
				3403	3155	3322	3376	3208	3462	3402	3326	3232	3486	3389	3287	3133	3325	3277	3199	3374	3320	3271	3269	3312	3388
				3217	3269	3360	3344	3231	3486	3420	3218	3183	3397	3315	3136	3185	3393	3239	3187	3505	3367	3257	3215	3255	3273
				3364	3333	3442	3446	3267	3150	3446	3288	3214	3516	3437	3253	3305	3472	3402	3228	3483	3374	3325	3292	3340	3414
				3341	3257	3340	3385	3269	3203	3469	3403	3305	3512	3368	3313	3243	3411	3295	3256	3466	3364	3297	3253	3346	3308
				3400	3301	3463	3528	3368	3260	3550	3386	3263	3536	3399	3369	3301	3493	3425	3348	3563	3473	3302	3313	3360	3402
				3512	3389	3434	3421	3348	3245	3493	3421	3347	3593	3505	3350	3284	3512	3350	3304	3480	3409	3344	3329	3413	3420
				3486	3350	3455	3462	3439	3313	3637	3493	3320	3567	3494	3371	3333	3532	3449	3388	3311	3516	3386	3316	3365	3458
				3477	3410	3495	3553	3362	3325	3591	3442	3346	3593	3514	3400	3334	3585	3430	3327	3277	3495	3350	3327	3493	3501
				3535	3404	3477	3543	3479	3378	3666	3549	3385	3257	3539	3435	3333	3542	3477	3414	3395	3572	3540	3360	3456	3493
				3494	3441	3488	3578	3393	3323	3572	3473	3367	3295	3561	3403	3347	3684	3539	3407	3332	3511	3425	3390	3448	3467
				3596	3470	3343	3599	3456	3357	3698	3600	3466	3354	3641	3567	3393	3665	3535	3467	3399	3602	3567	3494	3525	3581
				3539	3459	3385	3605	3557	3446	3687	3511	3444	3341	3578	3458	3404	3630	3549	3441	3368	3627	3462	3442	3434	3530
				3668	3563	3441	3682	3564	3389	3704	3570	3529	3406	3705	3588	3493	3724	3645	3451	3423	3631	3563	3522	3500	3620
				3572	3532	3406	3620	3558	3459	3757	3654	3427	3404	3654	3502	3423	3637	3574	3494	3416	3684	3564	3460	3451	3598
				3624	3661	3515	3773	3677	3483	3780	3697	3613	3511	3778	3640	3554	3495	3728	3575	3453	3682	3642	3596	3617	3704
				3719	3571	3530	3746	3623	3516	3796	3710	3523	3459	3686	3619	3515	3458	3700	3533	3466	3848	3708	3571	3557	3656
				3708	3715	3592	3824	3719	3556	3411	3739	3593	3486	3812	3651	3610	3584	3778	3697	3515	3816	3697	3654	3624	3736
				3729	3627	3542	3726	3659	3542	3448	3760	3686	3581	3819	3733	3585	3515	3726	3606	3523	3773	3683	3624	3589	3757
				3778	3687	3550	3840	3781	3631	3514	3851	3676	3519	3822	3733	3648	3561	3808	3736	3623	3858	3789	3628	3648	3766
				3799	3761	3645	3798	3710	3607	3488	3782	3683	3585	3873	3728	3592	3530	3806	3630	3535	3753	3689	3677	3634	3812
				3878	3719	3592	3798	3738	3675	3533	3893	3742	3547	3805	3813	3603	3571	3799	3710	3612	3564	3791	3682	3630	3756
				3817	3700	3663	3819	3806	3571	3550	3816	3672	3565	3826	3719	3642	3585	3841	3668	3575	3537	3752	3641	3647	3928
				5120 5120 5120>;

			PS_Config_Lmt_Open_Rawdata_N = <
				1292	1302	1313	1262	1340	1326	1300	1273	1387	1320	1263	1272	1338	1278	1254	1332	1293	1277	1278	1336	1321	1298
				1308	1278	1298	1271	1339	1335	1264	1248	1347	1301	1264	1255	1339	1266	1258	1388	1316	1272	1255	1312	1279	1303
				1342	1325	1336	1282	1243	1353	1291	1261	1393	1355	1230	1300	1364	1339	1276	1380	1323	1294	1287	1345	1333	1260
				1309	1286	1313	1287	1270	1357	1341	1294	1388	1320	1288	1280	1347	1292	1276	1372	1318	1287	1272	1352	1288	1317
				1326	1330	1365	1330	1286	1400	1328	1281	1410	1267	1320	1307	1379	1348	1315	1411	1362	1287	1298	1362	1261	1340
				1356	1319	1318	1321	1282	1378	1338	1312	1426	1372	1292	1294	1390	1308	1296	1380	1341	1307	1293	1371	1322	1327
				1339	1330	1324	1359	1310	1425	1363	1235	1350	1374	1345	1312	1396	1351	1328	1311	1376	1321	1228	1290	1335	1366
				1366	1342	1361	1316	1312	1406	1344	1318	1433	1382	1311	1318	1413	1353	1312	1298	1369	1310	1299	1408	1356	1362
				1355	1339	1368	1374	1342	1453	1328	1332	1288	1398	1337	1316	1402	1367	1353	1342	1402	1318	1317	1395	1353	1386
				1368	1339	1379	1336	1299	1400	1366	1333	1307	1410	1382	1320	1462	1393	1339	1304	1366	1339	1329	1386	1345	1375
				1382	1325	1385	1368	1279	1409	1424	1367	1327	1448	1371	1341	1451	1396	1366	1295	1363	1398	1370	1420	1387	1373
				1387	1348	1389	1394	1363	1458	1389	1361	1329	1423	1394	1351	1440	1399	1338	1340	1427	1356	1353	1387	1363	1392
				1431	1371	1428	1373	1350	1477	1407	1401	1363	1477	1416	1390	1483	1440	1319	1363	1435	1399	1374	1372	1397	1399
				1420	1335	1375	1414	1380	1491	1446	1372	1362	1459	1398	1372	1453	1391	1388	1368	1460	1405	1361	1352	1393	1399
				1458	1352	1423	1447	1375	1483	1458	1425	1385	1494	1452	1408	1342	1425	1404	1371	1446	1423	1402	1401	1419	1452
				1378	1401	1440	1433	1384	1494	1465	1379	1364	1456	1420	1344	1365	1454	1388	1366	1502	1443	1396	1378	1395	1402
				1441	1428	1475	1477	1400	1350	1477	1409	1377	1507	1473	1394	1416	1488	1458	1383	1492	1446	1425	1411	1431	1463
				1432	1396	1431	1450	1401	1372	1486	1458	1416	1505	1443	1420	1390	1462	1412	1395	1485	1441	1413	1394	1434	1417
				1457	1414	1484	1512	1443	1397	1521	1451	1398	1515	1456	1444	1414	1497	1468	1435	1527	1488	1415	1420	1440	1458
				1505	1452	1471	1466	1435	1390	1497	1466	1434	1540	1502	1435	1407	1505	1435	1416	1491	1461	1433	1426	1462	1465
				1494	1435	1480	1483	1474	1420	1558	1497	1423	1528	1497	1444	1428	1513	1478	1452	1419	1507	1451	1421	1442	1482
				1490	1461	1498	1522	1441	1425	1539	1475	1434	1540	1506	1457	1429	1536	1470	1426	1404	1498	1435	1426	1497	1500
				1515	1459	1490	1518	1491	1447	1571	1521	1450	1396	1516	1472	1428	1518	1490	1463	1455	1531	1517	1440	1481	1497
				1497	1474	1495	1533	1454	1424	1531	1488	1443	1412	1526	1458	1434	1579	1516	1460	1428	1504	1468	1453	1477	1486
				1541	1487	1432	1542	1481	1438	1585	1543	1485	1437	1560	1528	1454	1570	1515	1486	1456	1543	1528	1497	1510	1534
				1516	1482	1450	1545	1524	1477	1580	1504	1476	1432	1533	1482	1459	1555	1521	1474	1443	1554	1483	1475	1471	1513
				1572	1527	1474	1578	1527	1452	1587	1530	1512	1459	1588	1537	1497	1596	1562	1479	1467	1556	1527	1509	1500	1551
				1531	1513	1459	1551	1525	1482	1610	1566	1468	1459	1566	1501	1467	1558	1531	1497	1464	1579	1527	1483	1479	1542
				1553	1569	1506	1617	1576	1492	1620	1584	1548	1504	1619	1560	1523	1498	1597	1532	1480	1578	1561	1541	1550	1587
				1594	1530	1513	1605	1552	1507	1627	1590	1510	1482	1579	1551	1506	1482	1585	1514	1485	1649	1589	1530	1524	1567
				1589	1592	1539	1639	1594	1524	1462	1602	1540	1494	1633	1564	1547	1536	1619	1584	1506	1635	1584	1566	1553	1601
				1598	1554	1518	1597	1568	1518	1477	1611	1579	1534	1636	1600	1536	1506	1597	1545	1510	1617	1578	1553	1538	1610
				1619	1580	1521	1645	1620	1556	1506	1650	1575	1508	1638	1600	1563	1526	1632	1601	1552	1653	1624	1555	1563	1614
				1628	1612	1562	1627	1590	1546	1495	1621	1578	1536	1660	1597	1539	1513	1631	1555	1515	1608	1581	1576	1557	1633
				1662	1594	1539	1627	1602	1575	1514	1668	1603	1520	1630	1634	1544	1530	1628	1590	1548	1527	1624	1578	1555	1609
				1636	1585	1570	1636	1631	1530	1521	1635	1573	1528	1639	1594	1561	1536	1646	1572	1532	1516	1608	1560	1563	1683
				(-511) (-511) (-511)>;

			PS_Config_Lmt_FW_Rawdata_P = <
				1122	1127	1128	1128	1115	1127	1124	1132	1115	1132	1120	1106	1114	1124	1120	1122	1111	1106	1115	1114	1122	1118
				1122	1110	1107	1135	1115	1131	1124	1115	1125	1124	1117	1122	1121	1122	1121	1114	1100	1108	1115	1131	1107	1124
				1122	1114	1132	1100	1131	1122	1127	1120	1125	1118	1108	1128	1125	1145	1115	1117	1110	1132	1103	1128	1127	1125
				1113	1115	1111	1118	1100	1135	1128	1134	1117	1121	1122	1115	1132	1127	1108	1132	1121	1129	1115	1117	1132	1125
				1128	1124	1115	1110	1118	1104	1127	1117	1115	1110	1131	1120	1128	1111	1101	1101	1124	1111	1108	1117	1121	1127
				1108	1104	1122	1115	1104	1108	1141	1129	1122	1118	1122	1124	1115	1117	1125	1099	1135	1103	1114	1117	1110	1117
				1129	1118	1124	1127	1132	1121	1127	1131	1121	1120	1104	1141	1120	1114	1131	1117	1108	1115	1111	1124	1108	1122
				1101	1125	1122	1125	1118	1106	1121	1122	1118	1121	1110	1120	1131	1128	1121	1115	1114	1117	1121	1128	1132	1114
				1114	1111	1108	1125	1115	1125	1122	1125	1124	1124	1114	1136	1124	1104	1115	1128	1120	1125	1111	1134	1125	1138
				1125	1122	1111	1127	1117	1114	1108	1118	1128	1128	1127	1114	1111	1108	1118	1104	1111	1122	1120	1141	1097	1127
				1101	1121	1134	1127	1124	1117	1131	1125	1110	1113	1106	1121	1124	1108	1124	1134	1128	1121	1124	1108	1121	1107
				1111	1131	1118	1115	1118	1122	1113	1134	1135	1125	1113	1113	1120	1117	1118	1128	1120	1125	1121	1100	1125	1153
				1122	1117	1124	1108	1138	1132	1120	1117	1115	1118	1122	1107	1124	1111	1129	1127	1113	1125	1121	1114	1114	1125
				1114	1124	1103	1114	1121	1115	1104	1111	1106	1125	1118	1120	1120	1108	1132	1107	1113	1114	1125	1113	1125	1107
				1127	1115	1121	1113	1131	1120	1117	1107	1128	1121	1115	1099	1108	1121	1127	1122	1125	1101	1128	1125	1114	1131
				1128	1106	1107	1108	1135	1124	1115	1128	1125	1127	1120	1118	1120	1127	1128	1128	1110	1121	1121	1121	1118	1127
				1127	1120	1135	1122	1106	1124	1136	1121	1111	1124	1113	1124	1125	1132	1122	1113	1131	1113	1132	1121	1128	1111
				1122	1125	1101	1131	1122	1125	1113	1128	1118	1125	1128	1117	1120	1121	1117	1111	1128	1115	1121	1117	1120	1114
				1108	1115	1110	1113	1111	1103	1122	1111	1111	1114	1125	1117	1124	1122	1103	1113	1117	1129	1118	1115	1125	1115
				1117	1124	1120	1134	1106	1124	1096	1132	1125	1120	1104	1134	1103	1117	1118	1111	1117	1107	1108	1114	1122	1134
				1113	1108	1132	1122	1121	1125	1118	1103	1108	1122	1114	1134	1093	1122	1104	1120	1129	1110	1127	1122	1107	1124
				1120	1114	1128	1118	1121	1118	1118	1136	1104	1104	1103	1096	1124	1139	1131	1108	1124	1117	1114	1104	1115	1106
				1120	1107	1131	1131	1129	1114	1110	1120	1129	1113	1138	1118	1118	1115	1118	1115	1110	1122	1121	1127	1111	1136
				1124	1107	1117	1113	1122	1120	1106	1115	1125	1124	1117	1129	1108	1101	1103	1113	1118	1100	1117	1128	1113	1117
				1121	1127	1113	1110	1125	1131	1101	1124	1121	1110	1118	1125	1127	1122	1122	1124	1118	1125	1127	1120	1115	1138
				1117	1113	1128	1129	1131	1136	1110	1125	1131	1131	1127	1111	1134	1129	1111	1132	1115	1138	1127	1115	1118	1111
				1128	1127	1128	1103	1141	1131	1117	1104	1104	1115	1113	1107	1129	1114	1114	1124	1124	1108	1120	1115	1113	1122
				1108	1129	1115	1104	1125	1135	1117	1124	1118	1118	1132	1122	1108	1118	1106	1114	1143	1110	1115	1115	1122	1110
				1110	1118	1120	1128	1122	1129	1115	1110	1122	1131	1135	1113	1124	1120	1127	1110	1106	1132	1139	1120	1111	1117
				1122	1132	1115	1111	1118	1120	1118	1125	1120	1120	1127	1121	1108	1121	1120	1125	1115	1127	1122	1108	1117	1118
				1121	1127	1121	1103	1124	1113	1128	1108	1104	1120	1122	1117	1132	1115	1128	1135	1120	1138	1104	1131	1134	1120
				1117	1127	1108	1106	1120	1111	1115	1131	1124	1135	1107	1122	1115	1115	1136	1121	1120	1120	1113	1124	1117	1134
				1136	1128	1117	1107	1110	1135	1110	1127	1115	1120	1115	1117	1107	1139	1115	1117	1121	1113	1118	1108	1136	1122
				1115	1120	1122	1122	1113	1128	1118	1134	1136	1107	1114	1127	1129	1121	1115	1103	1124	1115	1113	1117	1111	1120
				1121	1108	1107	1117	1143	1111	1114	1108	1124	1125	1108	1110	1121	1136	1125	1114	1118	1114	1117	1108	1120	1132
				1117	1113	1115	1127	1111	1128	1115	1104	1118	1115	1115	1118	1114	1113	1125	1134	1097	1131	1108	1108	1108	1118
				3840 3840 3840>;

			PS_Config_Lmt_FW_Rawdata_N = <
				481	483	483	483	478	483	481	485	478	485	480	474	477	481	480	481	476	474	478	477	481	479
				481	475	474	486	478	484	481	478	482	481	478	481	480	481	480	477	471	475	478	484	474	481
				481	477	485	471	484	481	483	480	482	479	475	483	482	490	478	478	475	485	472	483	483	482
				477	478	476	479	471	486	483	486	478	480	481	478	485	483	475	485	480	484	478	478	485	482
				483	481	478	475	479	473	483	478	478	475	484	480	483	476	472	472	481	476	475	478	480	483
				475	473	481	478	473	475	489	484	481	479	481	481	478	478	482	471	486	472	477	478	475	478
				484	479	481	483	485	480	483	484	480	480	473	489	480	477	484	478	475	478	476	481	475	481
				472	482	481	482	479	474	480	481	479	480	475	480	484	483	480	478	477	478	480	483	485	477
				477	476	475	482	478	482	481	482	481	481	477	487	481	473	478	483	480	482	476	486	482	487
				482	481	476	483	478	477	475	479	483	483	483	477	476	475	479	473	476	481	480	489	470	483
				472	480	486	483	481	478	484	482	475	477	474	480	481	475	481	486	483	480	481	475	480	474
				476	484	479	478	479	481	477	486	486	482	477	477	480	478	479	483	480	482	480	471	482	494
				481	478	481	475	487	485	480	478	478	479	481	474	481	476	484	483	477	482	480	477	477	482
				477	481	472	477	480	478	473	476	474	482	479	480	480	475	485	474	477	477	482	477	482	474
				483	478	480	477	484	480	478	474	483	480	478	471	475	480	483	481	482	472	483	482	477	484
				483	474	474	475	486	481	478	483	482	483	480	479	480	483	483	483	475	480	480	480	479	483
				483	480	486	481	474	481	487	480	476	481	477	481	482	485	481	477	484	477	485	480	483	476
				481	482	472	484	481	482	477	483	479	482	483	478	480	480	478	476	483	478	480	478	480	477
				475	478	475	477	476	472	481	476	476	477	482	478	481	481	472	477	478	484	479	478	482	478
				478	481	480	486	474	481	469	485	482	480	473	486	472	478	479	476	478	474	475	477	481	486
				477	475	485	481	480	482	479	472	475	481	477	486	468	481	473	480	484	475	483	481	474	481
				480	477	483	479	480	479	479	487	473	473	472	469	481	488	484	475	481	478	477	473	478	474
				480	474	484	484	484	477	475	480	484	477	487	479	479	478	479	478	475	481	480	483	476	487
				481	474	478	477	481	480	474	478	482	481	478	484	475	472	472	477	479	471	478	483	477	478
				480	483	477	475	482	484	472	481	480	475	479	482	483	481	481	481	479	482	483	480	478	487
				478	477	483	484	484	487	475	482	484	484	483	476	486	484	476	485	478	487	483	478	479	476
				483	483	483	472	489	484	478	473	473	478	477	474	484	477	477	481	481	475	480	478	477	481
				475	484	478	473	482	486	478	481	479	479	485	481	475	479	474	477	490	475	478	478	481	475
				475	479	480	483	481	484	478	475	481	484	486	477	481	480	483	475	474	485	488	480	476	478
				481	485	478	476	479	480	479	482	480	480	483	480	475	480	480	482	478	483	481	475	478	479
				480	483	480	472	481	477	483	475	473	480	481	478	485	478	483	486	480	487	473	484	486	480
				478	483	475	474	480	476	478	484	481	486	474	481	478	478	487	480	480	480	477	481	478	486
				487	483	478	474	475	486	475	483	478	480	478	478	474	488	478	478	480	477	479	475	487	481
				478	480	481	481	477	483	479	486	487	474	477	483	484	480	478	472	481	478	477	478	476	480
				480	475	474	478	490	476	477	475	481	482	475	475	480	487	482	477	479	477	478	475	480	485
				478	477	478	483	476	483	478	473	479	478	478	479	477	477	482	486	470	484	475	475	475	479
				240 240 240>;

			PS_Config_Lmt_FW_CC_P = <
				64	63	66	64	64	64	66	66	66	66	66	62	66	66	66	64	64	64	66	66	64	64
				63	62	63	63	62	63	63	62	63	63	63	57	63	63	63	64	63	63	62	62	63	63
				62	62	63	63	56	63	63	63	64	64	63	64	64	63	63	63	63	63	63	62	64	62
				62	62	63	63	57	64	64	63	63	63	64	63	63	63	63	63	63	63	63	63	63	62
				62	63	63	63	63	64	63	63	63	64	64	63	63	64	64	63	64	63	63	63	63	63
				63	62	63	64	62	63	63	64	64	64	63	64	64	63	63	63	63	64	63	63	64	62
				62	62	63	64	63	64	64	63	64	64	64	64	64	64	64	59	64	64	64	63	63	63
				63	64	64	63	64	64	63	64	64	64	64	64	64	66	63	59	64	64	64	64	63	63
				62	62	63	64	64	64	64	64	57	64	64	64	64	64	64	64	64	64	64	63	63	63
				63	62	64	63	63	64	64	63	59	64	64	64	66	64	64	63	64	64	64	63	63	63
				64	57	63	63	63	64	64	64	64	66	64	64	64	64	64	63	64	66	64	63	64	63
				63	59	64	64	64	64	64	64	63	64	64	64	64	64	64	64	64	64	63	62	63	63
				63	64	64	64	63	64	64	64	63	64	66	64	64	64	64	64	64	64	64	59	63	63
				63	63	63	64	64	66	64	64	64	66	64	64	63	64	64	63	64	66	63	59	63	63
				63	63	64	66	63	64	64	66	64	66	66	66	59	64	64	64	64	64	64	64	64	64
				63	64	64	64	64	64	66	64	63	64	66	64	59	64	64	64	66	64	64	63	63	63
				64	64	64	64	64	57	64	64	64	66	66	64	64	66	64	64	64	64	64	64	63	64
				63	63	64	64	64	59	66	66	64	66	64	66	63	64	64	64	64	64	64	64	64	63
				63	64	64	66	64	64	66	64	64	66	66	66	64	64	66	64	64	64	64	64	64	63
				64	64	64	64	64	63	64	64	64	66	66	64	64	66	64	64	63	64	66	64	64	64
				63	63	64	64	66	64	66	67	64	64	66	64	64	66	66	66	60	66	64	64	64	63
				64	64	64	66	64	64	66	64	64	64	66	66	64	66	67	64	59	66	64	64	64	64
				64	63	64	66	66	64	67	66	66	59	66	66	64	66	66	64	66	66	64	64	64	64
				63	64	64	66	64	63	66	66	64	60	66	66	64	67	66	66	64	66	64	64	64	64
				64	66	59	66	64	64	67	66	66	66	67	66	64	66	66	66	64	66	67	66	64	64
				64	64	59	66	66	64	66	66	66	64	66	66	66	66	66	64	64	66	64	64	63	64
				64	66	64	67	64	64	66	66	66	64	66	67	66	66	66	66	66	66	66	66	60	64
				64	66	64	66	66	66	67	67	64	66	67	66	64	66	66	66	64	66	67	64	60	64
				64	66	64	66	67	64	66	66	67	66	67	67	67	62	66	66	66	66	66	64	67	64
				64	64	64	66	66	66	66	67	66	64	66	67	64	60	66	66	66	67	66	66	64	64
				64	66	66	67	66	66	59	66	66	66	67	66	66	66	67	66	64	66	66	66	64	64
				64	64	64	66	66	64	60	67	67	66	67	67	66	64	66	66	66	66	66	66	64	64
				64	64	64	67	67	66	66	67	66	66	67	67	67	66	66	67	66	66	66	66	66	64
				64	66	64	66	66	66	64	66	66	66	67	66	66	66	67	66	64	64	66	66	64	64
				66	64	64	66	66	66	64	67	67	64	66	67	66	66	67	66	66	62	66	66	66	64
				64	66	66	66	67	66	66	67	66	66	67	66	67	66	67	67	66	60	66	66	66	66
				314 314 314>;

			PS_Config_Lmt_FW_CC_N = <
				29	28	29	29	29	29	29	29	29	29	29	27	29	29	29	29	29	29	29	29	29	29
				28	27	28	28	27	28	28	27	28	28	28	26	28	28	28	29	28	28	27	27	28	28
				27	27	28	28	25	28	28	28	29	29	28	29	29	28	28	28	28	28	28	27	29	27
				27	27	28	28	26	29	29	28	28	28	29	28	28	28	28	28	28	28	28	28	28	27
				27	28	28	28	28	29	28	28	28	29	29	28	28	29	29	28	29	28	28	28	28	28
				28	27	28	29	27	28	28	29	29	29	28	29	29	28	28	28	28	29	28	28	29	27
				27	27	28	29	28	29	29	28	29	29	29	29	29	29	29	26	29	29	29	28	28	28
				28	29	29	28	29	29	28	29	29	29	29	29	29	29	28	26	29	29	29	29	28	28
				27	27	28	29	29	29	29	29	26	29	29	29	29	29	29	29	29	29	29	28	28	28
				28	27	29	28	28	29	29	28	26	29	29	29	29	29	29	28	29	29	29	28	28	28
				29	26	28	28	28	29	29	29	29	29	29	29	29	29	29	28	29	29	29	28	29	28
				28	26	29	29	29	29	29	29	28	29	29	29	29	29	29	29	29	29	28	27	28	28
				28	29	29	29	28	29	29	29	28	29	29	29	29	29	29	29	29	29	29	26	28	28
				28	28	28	29	29	29	29	29	29	29	29	29	28	29	29	28	29	29	28	26	28	28
				28	28	29	29	28	29	29	29	29	29	29	29	26	29	29	29	29	29	29	29	29	29
				28	29	29	29	29	29	29	29	28	29	29	29	26	29	29	29	29	29	29	28	28	28
				29	29	29	29	29	26	29	29	29	29	29	29	29	29	29	29	29	29	29	29	28	29
				28	28	29	29	29	26	29	29	29	29	29	29	28	29	29	29	29	29	29	29	29	28
				28	29	29	29	29	29	29	29	29	29	29	29	29	29	29	29	29	29	29	29	29	28
				29	29	29	29	29	28	29	29	29	29	29	29	29	29	29	29	28	29	29	29	29	29
				28	28	29	29	29	29	29	30	29	29	29	29	29	29	29	29	27	29	29	29	29	28
				29	29	29	29	29	29	29	29	29	29	29	29	29	29	30	29	26	29	29	29	29	29
				29	28	29	29	29	29	30	29	29	26	29	29	29	29	29	29	29	29	29	29	29	29
				28	29	29	29	29	28	29	29	29	27	29	29	29	30	29	29	29	29	29	29	29	29
				29	29	26	29	29	29	30	29	29	29	30	29	29	29	29	29	29	29	30	29	29	29
				29	29	26	29	29	29	29	29	29	29	29	29	29	29	29	29	29	29	29	29	28	29
				29	29	29	30	29	29	29	29	29	29	29	30	29	29	29	29	29	29	29	29	27	29
				29	29	29	29	29	29	30	30	29	29	30	29	29	29	29	29	29	29	30	29	27	29
				29	29	29	29	30	29	29	29	30	29	30	30	30	27	29	29	29	29	29	29	30	29
				29	29	29	29	29	29	29	30	29	29	29	30	29	27	29	29	29	30	29	29	29	29
				29	29	29	30	29	29	26	29	29	29	30	29	29	29	30	29	29	29	29	29	29	29
				29	29	29	29	29	29	27	30	30	29	30	30	29	29	29	29	29	29	29	29	29	29
				29	29	29	30	30	29	29	30	29	29	30	30	30	29	29	30	29	29	29	29	29	29
				29	29	29	29	29	29	29	29	29	29	30	29	29	29	30	29	29	29	29	29	29	29
				29	29	29	29	29	29	29	30	30	29	29	30	29	29	30	29	29	27	29	29	29	29
				29	29	29	29	30	29	29	30	29	29	30	29	30	29	30	30	29	27	29	29	29	29
				0 0 0>;

			PS_Config_Lmt_FW_Diff_P = <
				50	50	50	50	50	50	50	50	50	50	50	50	50	50	50	50	50	50	50	50	50	50
				50	50	50	50	50	50	50	50	50	50	50	50	50	50	50	50	50	50	50	50	50	50
				50	50	50	50	50	50	50	50	50	50	50	50	50	50	50	50	50	50	50	50	50	50
				50	50	50	50	50	50	50	50	50	50	50	50	50	50	50	50	50	50	50	50	50	50
				50	50	50	50	50	50	50	50	50	50	50	50	50	50	50	50	50	50	50	50	50	50
				50	50	50	50	50	50	50	50	50	50	50	50	50	50	50	50	50	50	50	50	50	50
				50	50	50	50	50	50	50	50	50	50	50	50	50	50	50	50	50	50	50	50	50	50
				50	50	50	50	50	50	50	50	50	50	50	50	50	50	50	50	50	50	50	50	50	50
				50	50	50	50	50	50	50	50	50	50	50	50	50	50	50	50	50	50	50	50	50	50
				50	50	50	50	50	50	50	50	50	50	50	50	50	50	50	50	50	50	50	50	50	50
				50	50	50	50	50	50	50	50	50	50	50	50	50	50	50	50	50	50	50	50	50	50
				50	50	50	50	50	50	50	50	50	50	50	50	50	50	50	50	50	50	50	50	50	50
				50	50	50	50	50	50	50	50	50	50	50	50	50	50	50	50	50	50	50	50	50	50
				50	50	50	50	50	50	50	50	50	50	50	50	50	50	50	50	50	50	50	50	50	50
				50	50	50	50	50	50	50	50	50	50	50	50	50	50	50	50	50	50	50	50	50	50
				50	50	50	50	50	50	50	50	50	50	50	50	50	50	50	50	50	50	50	50	50	50
				50	50	50	50	50	50	50	50	50	50	50	50	50	50	50	50	50	50	50	50	50	50
				50	50	50	50	50	50	50	50	50	50	50	50	50	50	50	50	50	50	50	50	50	50
				50	50	50	50	50	50	50	50	50	50	50	50	50	50	50	50	50	50	50	50	50	50
				50	50	50	50	50	50	50	50	50	50	50	50	50	50	50	50	50	50	50	50	50	50
				50	50	50	50	50	50	50	50	50	50	50	50	50	50	50	50	50	50	50	50	50	50
				50	50	50	50	50	50	50	50	50	50	50	50	50	50	50	50	50	50	50	50	50	50
				50	50	50	50	50	50	50	50	50	50	50	50	50	50	50	50	50	50	50	50	50	50
				50	50	50	50	50	50	50	50	50	50	50	50	50	50	50	50	50	50	50	50	50	50
				50	50	50	50	50	50	50	50	50	50	50	50	50	50	50	50	50	50	50	50	50	50
				50	50	50	50	50	50	50	50	50	50	50	50	50	50	50	50	50	50	50	50	50	50
				50	50	50	50	50	50	50	50	50	50	50	50	50	50	50	50	50	50	50	50	50	50
				50	50	50	50	50	50	50	50	50	50	50	50	50	50	50	50	50	50	50	50	50	50
				50	50	50	50	50	50	50	50	50	50	50	50	50	50	50	50	50	50	50	50	50	50
				50	50	50	50	50	50	50	50	50	50	50	50	50	50	50	50	50	50	50	50	50	50
				50	50	50	50	50	50	50	50	50	50	50	50	50	50	50	50	50	50	50	50	50	50
				50	50	50	50	50	50	50	50	50	50	50	50	50	50	50	50	50	50	50	50	50	50
				50	50	50	50	50	50	50	50	50	50	50	50	50	50	50	50	50	50	50	50	50	50
				50	50	50	50	50	50	50	50	50	50	50	50	50	50	50	50	50	50	50	50	50	50
				50	50	50	50	50	50	50	50	50	50	50	50	50	50	50	50	50	50	50	50	50	50
				50	50	50	50	50	50	50	50	50	50	50	50	50	50	50	50	50	50	50	50	50	50
				75 75 75>;

			PS_Config_Lmt_FW_Diff_N = <
				(-50)	(-50)	(-50)	(-50)	(-50)	(-50)	(-50)	(-50)	(-50)	(-50)	(-50)	(-50)	(-50)	(-50)	(-50)	(-50)	(-50)	(-50)	(-50)	(-50)	(-50)	(-50)
				(-50)	(-50)	(-50)	(-50)	(-50)	(-50)	(-50)	(-50)	(-50)	(-50)	(-50)	(-50)	(-50)	(-50)	(-50)	(-50)	(-50)	(-50)	(-50)	(-50)	(-50)	(-50)
				(-50)	(-50)	(-50)	(-50)	(-50)	(-50)	(-50)	(-50)	(-50)	(-50)	(-50)	(-50)	(-50)	(-50)	(-50)	(-50)	(-50)	(-50)	(-50)	(-50)	(-50)	(-50)
				(-50)	(-50)	(-50)	(-50)	(-50)	(-50)	(-50)	(-50)	(-50)	(-50)	(-50)	(-50)	(-50)	(-50)	(-50)	(-50)	(-50)	(-50)	(-50)	(-50)	(-50)	(-50)
				(-50)	(-50)	(-50)	(-50)	(-50)	(-50)	(-50)	(-50)	(-50)	(-50)	(-50)	(-50)	(-50)	(-50)	(-50)	(-50)	(-50)	(-50)	(-50)	(-50)	(-50)	(-50)
				(-50)	(-50)	(-50)	(-50)	(-50)	(-50)	(-50)	(-50)	(-50)	(-50)	(-50)	(-50)	(-50)	(-50)	(-50)	(-50)	(-50)	(-50)	(-50)	(-50)	(-50)	(-50)
				(-50)	(-50)	(-50)	(-50)	(-50)	(-50)	(-50)	(-50)	(-50)	(-50)	(-50)	(-50)	(-50)	(-50)	(-50)	(-50)	(-50)	(-50)	(-50)	(-50)	(-50)	(-50)
				(-50)	(-50)	(-50)	(-50)	(-50)	(-50)	(-50)	(-50)	(-50)	(-50)	(-50)	(-50)	(-50)	(-50)	(-50)	(-50)	(-50)	(-50)	(-50)	(-50)	(-50)	(-50)
				(-50)	(-50)	(-50)	(-50)	(-50)	(-50)	(-50)	(-50)	(-50)	(-50)	(-50)	(-50)	(-50)	(-50)	(-50)	(-50)	(-50)	(-50)	(-50)	(-50)	(-50)	(-50)
				(-50)	(-50)	(-50)	(-50)	(-50)	(-50)	(-50)	(-50)	(-50)	(-50)	(-50)	(-50)	(-50)	(-50)	(-50)	(-50)	(-50)	(-50)	(-50)	(-50)	(-50)	(-50)
				(-50)	(-50)	(-50)	(-50)	(-50)	(-50)	(-50)	(-50)	(-50)	(-50)	(-50)	(-50)	(-50)	(-50)	(-50)	(-50)	(-50)	(-50)	(-50)	(-50)	(-50)	(-50)
				(-50)	(-50)	(-50)	(-50)	(-50)	(-50)	(-50)	(-50)	(-50)	(-50)	(-50)	(-50)	(-50)	(-50)	(-50)	(-50)	(-50)	(-50)	(-50)	(-50)	(-50)	(-50)
				(-50)	(-50)	(-50)	(-50)	(-50)	(-50)	(-50)	(-50)	(-50)	(-50)	(-50)	(-50)	(-50)	(-50)	(-50)	(-50)	(-50)	(-50)	(-50)	(-50)	(-50)	(-50)
				(-50)	(-50)	(-50)	(-50)	(-50)	(-50)	(-50)	(-50)	(-50)	(-50)	(-50)	(-50)	(-50)	(-50)	(-50)	(-50)	(-50)	(-50)	(-50)	(-50)	(-50)	(-50)
				(-50)	(-50)	(-50)	(-50)	(-50)	(-50)	(-50)	(-50)	(-50)	(-50)	(-50)	(-50)	(-50)	(-50)	(-50)	(-50)	(-50)	(-50)	(-50)	(-50)	(-50)	(-50)
				(-50)	(-50)	(-50)	(-50)	(-50)	(-50)	(-50)	(-50)	(-50)	(-50)	(-50)	(-50)	(-50)	(-50)	(-50)	(-50)	(-50)	(-50)	(-50)	(-50)	(-50)	(-50)
				(-50)	(-50)	(-50)	(-50)	(-50)	(-50)	(-50)	(-50)	(-50)	(-50)	(-50)	(-50)	(-50)	(-50)	(-50)	(-50)	(-50)	(-50)	(-50)	(-50)	(-50)	(-50)
				(-50)	(-50)	(-50)	(-50)	(-50)	(-50)	(-50)	(-50)	(-50)	(-50)	(-50)	(-50)	(-50)	(-50)	(-50)	(-50)	(-50)	(-50)	(-50)	(-50)	(-50)	(-50)
				(-50)	(-50)	(-50)	(-50)	(-50)	(-50)	(-50)	(-50)	(-50)	(-50)	(-50)	(-50)	(-50)	(-50)	(-50)	(-50)	(-50)	(-50)	(-50)	(-50)	(-50)	(-50)
				(-50)	(-50)	(-50)	(-50)	(-50)	(-50)	(-50)	(-50)	(-50)	(-50)	(-50)	(-50)	(-50)	(-50)	(-50)	(-50)	(-50)	(-50)	(-50)	(-50)	(-50)	(-50)
				(-50)	(-50)	(-50)	(-50)	(-50)	(-50)	(-50)	(-50)	(-50)	(-50)	(-50)	(-50)	(-50)	(-50)	(-50)	(-50)	(-50)	(-50)	(-50)	(-50)	(-50)	(-50)
				(-50)	(-50)	(-50)	(-50)	(-50)	(-50)	(-50)	(-50)	(-50)	(-50)	(-50)	(-50)	(-50)	(-50)	(-50)	(-50)	(-50)	(-50)	(-50)	(-50)	(-50)	(-50)
				(-50)	(-50)	(-50)	(-50)	(-50)	(-50)	(-50)	(-50)	(-50)	(-50)	(-50)	(-50)	(-50)	(-50)	(-50)	(-50)	(-50)	(-50)	(-50)	(-50)	(-50)	(-50)
				(-50)	(-50)	(-50)	(-50)	(-50)	(-50)	(-50)	(-50)	(-50)	(-50)	(-50)	(-50)	(-50)	(-50)	(-50)	(-50)	(-50)	(-50)	(-50)	(-50)	(-50)	(-50)
				(-50)	(-50)	(-50)	(-50)	(-50)	(-50)	(-50)	(-50)	(-50)	(-50)	(-50)	(-50)	(-50)	(-50)	(-50)	(-50)	(-50)	(-50)	(-50)	(-50)	(-50)	(-50)
				(-50)	(-50)	(-50)	(-50)	(-50)	(-50)	(-50)	(-50)	(-50)	(-50)	(-50)	(-50)	(-50)	(-50)	(-50)	(-50)	(-50)	(-50)	(-50)	(-50)	(-50)	(-50)
				(-50)	(-50)	(-50)	(-50)	(-50)	(-50)	(-50)	(-50)	(-50)	(-50)	(-50)	(-50)	(-50)	(-50)	(-50)	(-50)	(-50)	(-50)	(-50)	(-50)	(-50)	(-50)
				(-50)	(-50)	(-50)	(-50)	(-50)	(-50)	(-50)	(-50)	(-50)	(-50)	(-50)	(-50)	(-50)	(-50)	(-50)	(-50)	(-50)	(-50)	(-50)	(-50)	(-50)	(-50)
				(-50)	(-50)	(-50)	(-50)	(-50)	(-50)	(-50)	(-50)	(-50)	(-50)	(-50)	(-50)	(-50)	(-50)	(-50)	(-50)	(-50)	(-50)	(-50)	(-50)	(-50)	(-50)
				(-50)	(-50)	(-50)	(-50)	(-50)	(-50)	(-50)	(-50)	(-50)	(-50)	(-50)	(-50)	(-50)	(-50)	(-50)	(-50)	(-50)	(-50)	(-50)	(-50)	(-50)	(-50)
				(-50)	(-50)	(-50)	(-50)	(-50)	(-50)	(-50)	(-50)	(-50)	(-50)	(-50)	(-50)	(-50)	(-50)	(-50)	(-50)	(-50)	(-50)	(-50)	(-50)	(-50)	(-50)
				(-50)	(-50)	(-50)	(-50)	(-50)	(-50)	(-50)	(-50)	(-50)	(-50)	(-50)	(-50)	(-50)	(-50)	(-50)	(-50)	(-50)	(-50)	(-50)	(-50)	(-50)	(-50)
				(-50)	(-50)	(-50)	(-50)	(-50)	(-50)	(-50)	(-50)	(-50)	(-50)	(-50)	(-50)	(-50)	(-50)	(-50)	(-50)	(-50)	(-50)	(-50)	(-50)	(-50)	(-50)
				(-50)	(-50)	(-50)	(-50)	(-50)	(-50)	(-50)	(-50)	(-50)	(-50)	(-50)	(-50)	(-50)	(-50)	(-50)	(-50)	(-50)	(-50)	(-50)	(-50)	(-50)	(-50)
				(-50)	(-50)	(-50)	(-50)	(-50)	(-50)	(-50)	(-50)	(-50)	(-50)	(-50)	(-50)	(-50)	(-50)	(-50)	(-50)	(-50)	(-50)	(-50)	(-50)	(-50)	(-50)
				(-50)	(-50)	(-50)	(-50)	(-50)	(-50)	(-50)	(-50)	(-50)	(-50)	(-50)	(-50)	(-50)	(-50)	(-50)	(-50)	(-50)	(-50)	(-50)	(-50)	(-50)	(-50)
				(-75) (-75) (-75)>;

			PS_Config_Diff_Test_Frame = <50>;

			PS_Config_Lmt_LPWG_Rawdata_P = <
				3840 3840 3840 3840 3840 3840 3840 3840 3840 3840 3840 3840 3840 3840 3840 3840 3840 3840 3840 3840 3840 3840 3840 3840 3840 3840 3840 3840 3840 3840 3840 3840
				3840 3840 3840 3840 3840 3840 3840 3840 3840 3840 3840 3840 3840 3840 3840 3840 3840 3840 3840 3840 3840 3840 3840 3840 3840 3840 3840 3840 3840 3840 3840 3840
				3840 3840 3840 3840 3840 3840 3840 3840 3840 3840 3840 3840 3840 3840 3840 3840 3840 3840 3840 3840 3840 3840 3840 3840 3840 3840 3840 3840 3840 3840 3840 3840
				3840 3840 3840 3840 3840 3840 3840 3840 3840 3840 3840 3840 3840 3840 3840 3840 3840 3840 3840 3840 3840 3840 3840 3840 3840 3840 3840 3840 3840 3840 3840 3840
				3840 3840 3840 3840 3840 3840 3840 3840 3840 3840 3840 3840 3840 3840 3840 3840 3840 3840 3840 3840 3840 3840 3840 3840 3840 3840 3840 3840 3840 3840 3840 3840
				3840 3840 3840 3840 3840 3840 3840 3840 3840 3840 3840 3840 3840 3840 3840 3840 3840 3840 3840 3840 3840 3840 3840 3840 3840 3840 3840 3840 3840 3840 3840 3840
				3840 3840 3840 3840 3840 3840 3840 3840 3840 3840 3840 3840 3840 3840 3840 3840 3840 3840 3840 3840 3840 3840 3840 3840 3840 3840 3840 3840 3840 3840 3840 3840
				3840 3840 3840 3840 3840 3840 3840 3840 3840 3840 3840 3840 3840 3840 3840 3840 3840 3840 3840 3840 3840 3840 3840 3840 3840 3840 3840 3840 3840 3840 3840 3840
				3840 3840 3840 3840 3840 3840 3840 3840 3840 3840 3840 3840 3840 3840 3840 3840 3840 3840 3840 3840 3840 3840 3840 3840 3840 3840 3840 3840 3840 3840 3840 3840
				3840 3840 3840 3840 3840 3840 3840 3840 3840 3840 3840 3840 3840 3840 3840 3840 3840 3840 3840 3840 3840 3840 3840 3840 3840 3840 3840 3840 3840 3840 3840 3840
				3840 3840 3840 3840 3840 3840 3840 3840 3840 3840 3840 3840 3840 3840 3840 3840 3840 3840 3840 3840 3840 3840 3840 3840 3840 3840 3840 3840 3840 3840 3840 3840
				3840 3840 3840 3840 3840 3840 3840 3840 3840 3840 3840 3840 3840 3840 3840 3840 3840 3840 3840 3840 3840 3840 3840 3840 3840 3840 3840 3840 3840 3840 3840 3840
				3840 3840 3840 3840 3840 3840 3840 3840 3840 3840 3840 3840 3840 3840 3840 3840 3840 3840 3840 3840 3840 3840 3840 3840 3840 3840 3840 3840 3840 3840 3840 3840
				3840 3840 3840 3840 3840 3840 3840 3840 3840 3840 3840 3840 3840 3840 3840 3840 3840 3840 3840 3840 3840 3840 3840 3840 3840 3840 3840 3840 3840 3840 3840 3840
				3840 3840 3840 3840 3840 3840 3840 3840 3840 3840 3840 3840 3840 3840 3840 3840 3840 3840 3840 3840 3840 3840 3840 3840 3840 3840 3840 3840 3840 3840 3840 3840
				3840 3840 3840 3840 3840 3840 3840 3840 3840 3840 3840 3840 3840 3840 3840 3840 3840 3840 3840 3840 3840 3840 3840 3840 3840 3840 3840 3840 3840 3840 3840 3840
				3840 3840 3840 3840 3840 3840 3840 3840 3840 3840 3840 3840 3840 3840 3840 3840 3840 3840 3840 3840 3840 3840 3840 3840 3840 3840 3840 3840 3840 3840 3840 3840
				3840 3840 3840 3840 3840 3840 3840 3840 3840 3840 3840 3840 3840 3840 3840 3840 3840 3840 3840 3840 3840 3840 3840 3840 3840 3840 3840 3840 3840 3840 3840 3840
				3840 3840 3840 3840 3840 3840 3840 3840 3840 3840 3840 3840 3840 3840 3840 3840 3840 3840 3840 3840 3840 3840 3840 3840 3840 3840 3840 3840 3840 3840 3840 3840
				3840 3840 3840 3840 3840 3840 3840 3840 3840 3840 3840 3840 3840 3840 3840 3840 3840 3840 3840 3840 3840 3840 3840 3840 3840 3840 3840 3840 3840 3840 3840 3840
				3840 3840 3840 3840 3840 3840 3840 3840 3840 3840 3840 3840 3840 3840 3840 3840 3840 3840 3840 3840 3840 3840 3840 3840 3840 3840 3840 3840 3840 3840 3840 3840
				3840 3840 3840 3840 3840 3840 3840 3840 3840 3840 3840 3840 3840 3840 3840 3840 3840 3840 3840 3840 3840 3840 3840 3840 3840 3840 3840 3840 3840 3840 3840 3840
				3840 3840 3840 3840 3840 3840 3840 3840 3840 3840 3840 3840 3840 3840 3840 3840 3840 3840 3840 3840 3840 3840 3840 3840 3840 3840 3840 3840 3840 3840 3840 3840
				3840 3840 3840 3840 3840 3840 3840 3840 3840 3840 3840 3840 3840 3840 3840 3840 3840 3840 3840 3840 3840 3840 3840 3840 3840 3840 3840 3840 3840 3840 3840 3840
				3840 3840 3840 3840 3840 3840 3840 3840 3840 3840 3840 3840 3840 3840 3840 3840 3840 3840 3840 3840 3840 3840 3840 3840 3840 3840 3840 3840 3840 3840 3840 3840
				3840 3840 3840 3840 3840 3840 3840 3840 3840 3840 3840 3840 3840 3840 3840 3840 3840 3840 3840 3840 3840 3840 3840 3840 3840 3840 3840 3840 3840 3840 3840 3840
				3840 3840 3840 3840 3840 3840 3840 3840 3840 3840 3840 3840 3840 3840 3840 3840 3840 3840 3840 3840 3840 3840 3840 3840 3840 3840 3840 3840 3840 3840 3840 3840
				3840 3840 3840 3840 3840 3840 3840 3840 3840 3840 3840 3840 3840 3840 3840 3840 3840 3840 3840 3840 3840 3840 3840 3840 3840 3840 3840 3840 3840 3840 3840 3840
				3840 3840 3840 3840 3840 3840 3840 3840 3840 3840 3840 3840 3840 3840 3840 3840 3840 3840 3840 3840 3840 3840 3840 3840 3840 3840 3840 3840 3840 3840 3840 3840
				3840 3840 3840 3840 3840 3840 3840 3840 3840 3840 3840 3840 3840 3840 3840 3840 3840 3840 3840 3840 3840 3840 3840 3840 3840 3840 3840 3840 3840 3840 3840 3840
				3840 3840 3840 3840 3840 3840 3840 3840 3840 3840 3840 3840 3840 3840 3840 3840 3840 3840 3840 3840 3840 3840 3840 3840 3840 3840 3840 3840 3840 3840 3840 3840
				3840 3840 3840 3840 3840 3840 3840 3840 3840 3840 3840 3840 3840 3840 3840 3840 3840 3840 3840 3840 3840 3840 3840 3840 3840 3840 3840 3840 3840 3840 3840 3840
				3840 3840 3840 3840 3840 3840 3840 3840 3840 3840 3840 3840 3840 3840 3840 3840 3840 3840 3840 3840 3840 3840 3840 3840 3840 3840 3840 3840 3840 3840 3840 3840
				3840 3840 3840 3840 3840 3840 3840 3840 3840 3840 3840 3840 3840 3840 3840 3840 3840 3840 3840 3840 3840 3840 3840 3840 3840 3840 3840 3840 3840 3840 3840 3840
				3840 3840 3840 3840 3840 3840 3840 3840 3840 3840 3840 3840 3840 3840 3840 3840 3840 3840 3840 3840 3840 3840 3840 3840 3840 3840 3840 3840 3840 3840 3840 3840
				3840 3840 3840 3840 3840 3840 3840 3840 3840 3840 3840 3840 3840 3840 3840 3840 3840 3840 3840 3840 3840 3840 3840 3840 3840 3840 3840 3840 3840 3840 3840 3840
				3840 3840 3840 3840 3840 3840 3840 3840 3840 3840 3840 3840 3840 3840 3840 3840 3840 3840 3840 3840 3840 3840 3840 3840 3840 3840 3840 3840 3840 3840 3840 3840
				3840 3840 3840 3840 3840 3840 3840 3840 3840 3840 3840 3840 3840 3840 3840 3840 3840 3840 3840 3840 3840 3840 3840 3840 3840 3840 3840 3840 3840 3840 3840 3840
				3840 3840 3840 3840 3840 3840 3840 3840 3840 3840 3840 3840 3840 3840 3840 3840 3840 3840 3840 3840 3840 3840 3840 3840 3840 3840 3840 3840 3840 3840 3840 3840
				3840 3840 3840 3840 3840 3840 3840 3840 3840 3840 3840 3840 3840 3840 3840 3840 3840 3840 3840 3840 3840 3840 3840 3840 3840 3840 3840 3840 3840 3840 3840 3840
				3840 3840 3840 3840 3840 3840 3840 3840 3840 3840 3840 3840 3840 3840 3840 3840 3840 3840 3840 3840 3840 3840 3840 3840 3840 3840 3840 3840 3840 3840 3840 3840
				3840 3840 3840 3840 3840 3840 3840 3840 3840 3840 3840 3840 3840 3840 3840 3840 3840 3840 3840 3840 3840 3840 3840 3840 3840 3840 3840 3840 3840 3840 3840 3840
				3840 3840 3840 3840 3840 3840 3840 3840 3840 3840 3840 3840 3840 3840 3840 3840 3840 3840 3840 3840 3840 3840 3840 3840 3840 3840 3840 3840 3840 3840 3840 3840
				3840 3840 3840 3840 3840 3840 3840 3840 3840 3840 3840 3840 3840 3840 3840 3840 3840 3840 3840 3840 3840 3840 3840 3840 3840 3840 3840 3840 3840 3840 3840 3840
				3840 3840 3840 3840 3840 3840 3840 3840 3840 3840 3840 3840 3840 3840 3840 3840 3840 3840 3840 3840 3840 3840 3840 3840 3840 3840 3840 3840 3840 3840 3840 3840
				3840 3840 3840 3840 3840 3840 3840 3840 3840 3840 3840 3840 3840 3840 3840 3840 3840 3840 3840 3840 3840 3840 3840 3840 3840 3840 3840 3840 3840 3840 3840 3840
				3840 3840 3840 3840 3840 3840 3840 3840 3840 3840 3840 3840 3840 3840 3840 3840 3840 3840 3840 3840 3840 3840 3840 3840 3840 3840 3840 3840 3840 3840 3840 3840
				3840 3840 3840 3840 3840 3840 3840 3840 3840 3840 3840 3840 3840 3840 3840 3840 3840 3840 3840 3840 3840 3840 3840 3840 3840 3840 3840 3840 3840 3840 3840 3840
				3840 3840 3840 3840 3840 3840 3840 3840 3840 3840 3840 3840 3840 3840 3840 3840 3840 3840 3840 3840 3840 3840 3840 3840 3840 3840 3840 3840 3840 3840 3840 3840
				3840 3840 3840 3840 3840 3840 3840 3840 3840 3840 3840 3840 3840 3840 3840 3840 3840 3840 3840 3840 3840 3840 3840 3840 3840 3840 3840 3840 3840 3840 3840 3840
				3840 3840 3840>;

			PS_Config_Lmt_LPWG_Rawdata_N = <
				240 240 240 240 240 240 240 240 240 240 240 240 240 240 240 240 240 240 240 240 240 240 240 240 240 240 240 240 240 240 240 240
				240 240 240 240 240 240 240 240 240 240 240 240 240 240 240 240 240 240 240 240 240 240 240 240 240 240 240 240 240 240 240 240
				240 240 240 240 240 240 240 240 240 240 240 240 240 240 240 240 240 240 240 240 240 240 240 240 240 240 240 240 240 240 240 240
				240 240 240 240 240 240 240 240 240 240 240 240 240 240 240 240 240 240 240 240 240 240 240 240 240 240 240 240 240 240 240 240
				240 240 240 240 240 240 240 240 240 240 240 240 240 240 240 240 240 240 240 240 240 240 240 240 240 240 240 240 240 240 240 240
				240 240 240 240 240 240 240 240 240 240 240 240 240 240 240 240 240 240 240 240 240 240 240 240 240 240 240 240 240 240 240 240
				240 240 240 240 240 240 240 240 240 240 240 240 240 240 240 240 240 240 240 240 240 240 240 240 240 240 240 240 240 240 240 240
				240 240 240 240 240 240 240 240 240 240 240 240 240 240 240 240 240 240 240 240 240 240 240 240 240 240 240 240 240 240 240 240
				240 240 240 240 240 240 240 240 240 240 240 240 240 240 240 240 240 240 240 240 240 240 240 240 240 240 240 240 240 240 240 240
				240 240 240 240 240 240 240 240 240 240 240 240 240 240 240 240 240 240 240 240 240 240 240 240 240 240 240 240 240 240 240 240
				240 240 240 240 240 240 240 240 240 240 240 240 240 240 240 240 240 240 240 240 240 240 240 240 240 240 240 240 240 240 240 240
				240 240 240 240 240 240 240 240 240 240 240 240 240 240 240 240 240 240 240 240 240 240 240 240 240 240 240 240 240 240 240 240
				240 240 240 240 240 240 240 240 240 240 240 240 240 240 240 240 240 240 240 240 240 240 240 240 240 240 240 240 240 240 240 240
				240 240 240 240 240 240 240 240 240 240 240 240 240 240 240 240 240 240 240 240 240 240 240 240 240 240 240 240 240 240 240 240
				240 240 240 240 240 240 240 240 240 240 240 240 240 240 240 240 240 240 240 240 240 240 240 240 240 240 240 240 240 240 240 240
				240 240 240 240 240 240 240 240 240 240 240 240 240 240 240 240 240 240 240 240 240 240 240 240 240 240 240 240 240 240 240 240
				240 240 240 240 240 240 240 240 240 240 240 240 240 240 240 240 240 240 240 240 240 240 240 240 240 240 240 240 240 240 240 240
				240 240 240 240 240 240 240 240 240 240 240 240 240 240 240 240 240 240 240 240 240 240 240 240 240 240 240 240 240 240 240 240
				240 240 240 240 240 240 240 240 240 240 240 240 240 240 240 240 240 240 240 240 240 240 240 240 240 240 240 240 240 240 240 240
				240 240 240 240 240 240 240 240 240 240 240 240 240 240 240 240 240 240 240 240 240 240 240 240 240 240 240 240 240 240 240 240
				240 240 240 240 240 240 240 240 240 240 240 240 240 240 240 240 240 240 240 240 240 240 240 240 240 240 240 240 240 240 240 240
				240 240 240 240 240 240 240 240 240 240 240 240 240 240 240 240 240 240 240 240 240 240 240 240 240 240 240 240 240 240 240 240
				240 240 240 240 240 240 240 240 240 240 240 240 240 240 240 240 240 240 240 240 240 240 240 240 240 240 240 240 240 240 240 240
				240 240 240 240 240 240 240 240 240 240 240 240 240 240 240 240 240 240 240 240 240 240 240 240 240 240 240 240 240 240 240 240
				240 240 240 240 240 240 240 240 240 240 240 240 240 240 240 240 240 240 240 240 240 240 240 240 240 240 240 240 240 240 240 240
				240 240 240 240 240 240 240 240 240 240 240 240 240 240 240 240 240 240 240 240 240 240 240 240 240 240 240 240 240 240 240 240
				240 240 240 240 240 240 240 240 240 240 240 240 240 240 240 240 240 240 240 240 240 240 240 240 240 240 240 240 240 240 240 240
				240 240 240 240 240 240 240 240 240 240 240 240 240 240 240 240 240 240 240 240 240 240 240 240 240 240 240 240 240 240 240 240
				240 240 240 240 240 240 240 240 240 240 240 240 240 240 240 240 240 240 240 240 240 240 240 240 240 240 240 240 240 240 240 240
				240 240 240 240 240 240 240 240 240 240 240 240 240 240 240 240 240 240 240 240 240 240 240 240 240 240 240 240 240 240 240 240
				240 240 240 240 240 240 240 240 240 240 240 240 240 240 240 240 240 240 240 240 240 240 240 240 240 240 240 240 240 240 240 240
				240 240 240 240 240 240 240 240 240 240 240 240 240 240 240 240 240 240 240 240 240 240 240 240 240 240 240 240 240 240 240 240
				240 240 240 240 240 240 240 240 240 240 240 240 240 240 240 240 240 240 240 240 240 240 240 240 240 240 240 240 240 240 240 240
				240 240 240 240 240 240 240 240 240 240 240 240 240 240 240 240 240 240 240 240 240 240 240 240 240 240 240 240 240 240 240 240
				240 240 240 240 240 240 240 240 240 240 240 240 240 240 240 240 240 240 240 240 240 240 240 240 240 240 240 240 240 240 240 240
				240 240 240 240 240 240 240 240 240 240 240 240 240 240 240 240 240 240 240 240 240 240 240 240 240 240 240 240 240 240 240 240
				240 240 240 240 240 240 240 240 240 240 240 240 240 240 240 240 240 240 240 240 240 240 240 240 240 240 240 240 240 240 240 240
				240 240 240 240 240 240 240 240 240 240 240 240 240 240 240 240 240 240 240 240 240 240 240 240 240 240 240 240 240 240 240 240
				240 240 240 240 240 240 240 240 240 240 240 240 240 240 240 240 240 240 240 240 240 240 240 240 240 240 240 240 240 240 240 240
				240 240 240 240 240 240 240 240 240 240 240 240 240 240 240 240 240 240 240 240 240 240 240 240 240 240 240 240 240 240 240 240
				240 240 240 240 240 240 240 240 240 240 240 240 240 240 240 240 240 240 240 240 240 240 240 240 240 240 240 240 240 240 240 240
				240 240 240 240 240 240 240 240 240 240 240 240 240 240 240 240 240 240 240 240 240 240 240 240 240 240 240 240 240 240 240 240
				240 240 240 240 240 240 240 240 240 240 240 240 240 240 240 240 240 240 240 240 240 240 240 240 240 240 240 240 240 240 240 240
				240 240 240 240 240 240 240 240 240 240 240 240 240 240 240 240 240 240 240 240 240 240 240 240 240 240 240 240 240 240 240 240
				240 240 240 240 240 240 240 240 240 240 240 240 240 240 240 240 240 240 240 240 240 240 240 240 240 240 240 240 240 240 240 240
				240 240 240 240 240 240 240 240 240 240 240 240 240 240 240 240 240 240 240 240 240 240 240 240 240 240 240 240 240 240 240 240
				240 240 240 240 240 240 240 240 240 240 240 240 240 240 240 240 240 240 240 240 240 240 240 240 240 240 240 240 240 240 240 240
				240 240 240 240 240 240 240 240 240 240 240 240 240 240 240 240 240 240 240 240 240 240 240 240 240 240 240 240 240 240 240 240
				240 240 240 240 240 240 240 240 240 240 240 240 240 240 240 240 240 240 240 240 240 240 240 240 240 240 240 240 240 240 240 240
				240 240 240 240 240 240 240 240 240 240 240 240 240 240 240 240 240 240 240 240 240 240 240 240 240 240 240 240 240 240 240 240
				240 240 240>;

			PS_Config_Lmt_LPWG_Diff_P = <
				75 75 75 75 75 75 75 75 75 75 75 75 75 75 75 75 75 75 75 75 75 75 75 75 75 75 75 75 75 75 75 75
				75 75 75 75 75 75 75 75 75 75 75 75 75 75 75 75 75 75 75 75 75 75 75 75 75 75 75 75 75 75 75 75
				75 75 75 75 75 75 75 75 75 75 75 75 75 75 75 75 75 75 75 75 75 75 75 75 75 75 75 75 75 75 75 75
				75 75 75 75 75 75 75 75 75 75 75 75 75 75 75 75 75 75 75 75 75 75 75 75 75 75 75 75 75 75 75 75
				75 75 75 75 75 75 75 75 75 75 75 75 75 75 75 75 75 75 75 75 75 75 75 75 75 75 75 75 75 75 75 75
				75 75 75 75 75 75 75 75 75 75 75 75 75 75 75 75 75 75 75 75 75 75 75 75 75 75 75 75 75 75 75 75
				75 75 75 75 75 75 75 75 75 75 75 75 75 75 75 75 75 75 75 75 75 75 75 75 75 75 75 75 75 75 75 75
				75 75 75 75 75 75 75 75 75 75 75 75 75 75 75 75 75 75 75 75 75 75 75 75 75 75 75 75 75 75 75 75
				75 75 75 75 75 75 75 75 75 75 75 75 75 75 75 75 75 75 75 75 75 75 75 75 75 75 75 75 75 75 75 75
				75 75 75 75 75 75 75 75 75 75 75 75 75 75 75 75 75 75 75 75 75 75 75 75 75 75 75 75 75 75 75 75
				75 75 75 75 75 75 75 75 75 75 75 75 75 75 75 75 75 75 75 75 75 75 75 75 75 75 75 75 75 75 75 75
				75 75 75 75 75 75 75 75 75 75 75 75 75 75 75 75 75 75 75 75 75 75 75 75 75 75 75 75 75 75 75 75
				75 75 75 75 75 75 75 75 75 75 75 75 75 75 75 75 75 75 75 75 75 75 75 75 75 75 75 75 75 75 75 75
				75 75 75 75 75 75 75 75 75 75 75 75 75 75 75 75 75 75 75 75 75 75 75 75 75 75 75 75 75 75 75 75
				75 75 75 75 75 75 75 75 75 75 75 75 75 75 75 75 75 75 75 75 75 75 75 75 75 75 75 75 75 75 75 75
				75 75 75 75 75 75 75 75 75 75 75 75 75 75 75 75 75 75 75 75 75 75 75 75 75 75 75 75 75 75 75 75
				75 75 75 75 75 75 75 75 75 75 75 75 75 75 75 75 75 75 75 75 75 75 75 75 75 75 75 75 75 75 75 75
				75 75 75 75 75 75 75 75 75 75 75 75 75 75 75 75 75 75 75 75 75 75 75 75 75 75 75 75 75 75 75 75
				75 75 75 75 75 75 75 75 75 75 75 75 75 75 75 75 75 75 75 75 75 75 75 75 75 75 75 75 75 75 75 75
				75 75 75 75 75 75 75 75 75 75 75 75 75 75 75 75 75 75 75 75 75 75 75 75 75 75 75 75 75 75 75 75
				75 75 75 75 75 75 75 75 75 75 75 75 75 75 75 75 75 75 75 75 75 75 75 75 75 75 75 75 75 75 75 75
				75 75 75 75 75 75 75 75 75 75 75 75 75 75 75 75 75 75 75 75 75 75 75 75 75 75 75 75 75 75 75 75
				75 75 75 75 75 75 75 75 75 75 75 75 75 75 75 75 75 75 75 75 75 75 75 75 75 75 75 75 75 75 75 75
				75 75 75 75 75 75 75 75 75 75 75 75 75 75 75 75 75 75 75 75 75 75 75 75 75 75 75 75 75 75 75 75
				75 75 75 75 75 75 75 75 75 75 75 75 75 75 75 75 75 75 75 75 75 75 75 75 75 75 75 75 75 75 75 75
				75 75 75 75 75 75 75 75 75 75 75 75 75 75 75 75 75 75 75 75 75 75 75 75 75 75 75 75 75 75 75 75
				75 75 75 75 75 75 75 75 75 75 75 75 75 75 75 75 75 75 75 75 75 75 75 75 75 75 75 75 75 75 75 75
				75 75 75 75 75 75 75 75 75 75 75 75 75 75 75 75 75 75 75 75 75 75 75 75 75 75 75 75 75 75 75 75
				75 75 75 75 75 75 75 75 75 75 75 75 75 75 75 75 75 75 75 75 75 75 75 75 75 75 75 75 75 75 75 75
				75 75 75 75 75 75 75 75 75 75 75 75 75 75 75 75 75 75 75 75 75 75 75 75 75 75 75 75 75 75 75 75
				75 75 75 75 75 75 75 75 75 75 75 75 75 75 75 75 75 75 75 75 75 75 75 75 75 75 75 75 75 75 75 75
				75 75 75 75 75 75 75 75 75 75 75 75 75 75 75 75 75 75 75 75 75 75 75 75 75 75 75 75 75 75 75 75
				75 75 75 75 75 75 75 75 75 75 75 75 75 75 75 75 75 75 75 75 75 75 75 75 75 75 75 75 75 75 75 75
				75 75 75 75 75 75 75 75 75 75 75 75 75 75 75 75 75 75 75 75 75 75 75 75 75 75 75 75 75 75 75 75
				75 75 75 75 75 75 75 75 75 75 75 75 75 75 75 75 75 75 75 75 75 75 75 75 75 75 75 75 75 75 75 75
				75 75 75 75 75 75 75 75 75 75 75 75 75 75 75 75 75 75 75 75 75 75 75 75 75 75 75 75 75 75 75 75
				75 75 75 75 75 75 75 75 75 75 75 75 75 75 75 75 75 75 75 75 75 75 75 75 75 75 75 75 75 75 75 75
				75 75 75 75 75 75 75 75 75 75 75 75 75 75 75 75 75 75 75 75 75 75 75 75 75 75 75 75 75 75 75 75
				75 75 75 75 75 75 75 75 75 75 75 75 75 75 75 75 75 75 75 75 75 75 75 75 75 75 75 75 75 75 75 75
				75 75 75 75 75 75 75 75 75 75 75 75 75 75 75 75 75 75 75 75 75 75 75 75 75 75 75 75 75 75 75 75
				75 75 75 75 75 75 75 75 75 75 75 75 75 75 75 75 75 75 75 75 75 75 75 75 75 75 75 75 75 75 75 75
				75 75 75 75 75 75 75 75 75 75 75 75 75 75 75 75 75 75 75 75 75 75 75 75 75 75 75 75 75 75 75 75
				75 75 75 75 75 75 75 75 75 75 75 75 75 75 75 75 75 75 75 75 75 75 75 75 75 75 75 75 75 75 75 75
				75 75 75 75 75 75 75 75 75 75 75 75 75 75 75 75 75 75 75 75 75 75 75 75 75 75 75 75 75 75 75 75
				75 75 75 75 75 75 75 75 75 75 75 75 75 75 75 75 75 75 75 75 75 75 75 75 75 75 75 75 75 75 75 75
				75 75 75 75 75 75 75 75 75 75 75 75 75 75 75 75 75 75 75 75 75 75 75 75 75 75 75 75 75 75 75 75
				75 75 75 75 75 75 75 75 75 75 75 75 75 75 75 75 75 75 75 75 75 75 75 75 75 75 75 75 75 75 75 75
				75 75 75 75 75 75 75 75 75 75 75 75 75 75 75 75 75 75 75 75 75 75 75 75 75 75 75 75 75 75 75 75
				75 75 75 75 75 75 75 75 75 75 75 75 75 75 75 75 75 75 75 75 75 75 75 75 75 75 75 75 75 75 75 75
				75 75 75 75 75 75 75 75 75 75 75 75 75 75 75 75 75 75 75 75 75 75 75 75 75 75 75 75 75 75 75 75
				75 75 75>;

			PS_Config_Lmt_LPWG_Diff_N = <
				(-75) (-75) (-75) (-75) (-75) (-75) (-75) (-75) (-75) (-75) (-75) (-75) (-75) (-75) (-75) (-75) (-75) (-75) (-75) (-75) (-75) (-75) (-75) (-75) (-75) (-75) (-75) (-75) (-75) (-75) (-75) (-75) (-75) (-75) (-75) (-75)
				(-75) (-75) (-75) (-75) (-75) (-75) (-75) (-75) (-75) (-75) (-75) (-75) (-75) (-75) (-75) (-75) (-75) (-75) (-75) (-75) (-75) (-75) (-75) (-75) (-75) (-75) (-75) (-75) (-75) (-75) (-75) (-75) (-75) (-75) (-75) (-75)
				(-75) (-75) (-75) (-75) (-75) (-75) (-75) (-75) (-75) (-75) (-75) (-75) (-75) (-75) (-75) (-75) (-75) (-75) (-75) (-75) (-75) (-75) (-75) (-75) (-75) (-75) (-75) (-75) (-75) (-75) (-75) (-75) (-75) (-75) (-75) (-75)
				(-75) (-75) (-75) (-75) (-75) (-75) (-75) (-75) (-75) (-75) (-75) (-75) (-75) (-75) (-75) (-75) (-75) (-75) (-75) (-75) (-75) (-75) (-75) (-75) (-75) (-75) (-75) (-75) (-75) (-75) (-75) (-75) (-75) (-75) (-75) (-75)
				(-75) (-75) (-75) (-75) (-75) (-75) (-75) (-75) (-75) (-75) (-75) (-75) (-75) (-75) (-75) (-75) (-75) (-75) (-75) (-75) (-75) (-75) (-75) (-75) (-75) (-75) (-75) (-75) (-75) (-75) (-75) (-75) (-75) (-75) (-75) (-75)
				(-75) (-75) (-75) (-75) (-75) (-75) (-75) (-75) (-75) (-75) (-75) (-75) (-75) (-75) (-75) (-75) (-75) (-75) (-75) (-75) (-75) (-75) (-75) (-75) (-75) (-75) (-75) (-75) (-75) (-75) (-75) (-75) (-75) (-75) (-75) (-75)
				(-75) (-75) (-75) (-75) (-75) (-75) (-75) (-75) (-75) (-75) (-75) (-75) (-75) (-75) (-75) (-75) (-75) (-75) (-75) (-75) (-75) (-75) (-75) (-75) (-75) (-75) (-75) (-75) (-75) (-75) (-75) (-75) (-75) (-75) (-75) (-75)
				(-75) (-75) (-75) (-75) (-75) (-75) (-75) (-75) (-75) (-75) (-75) (-75) (-75) (-75) (-75) (-75) (-75) (-75) (-75) (-75) (-75) (-75) (-75) (-75) (-75) (-75) (-75) (-75) (-75) (-75) (-75) (-75) (-75) (-75) (-75) (-75)
				(-75) (-75) (-75) (-75) (-75) (-75) (-75) (-75) (-75) (-75) (-75) (-75) (-75) (-75) (-75) (-75) (-75) (-75) (-75) (-75) (-75) (-75) (-75) (-75) (-75) (-75) (-75) (-75) (-75) (-75) (-75) (-75) (-75) (-75) (-75) (-75)
				(-75) (-75) (-75) (-75) (-75) (-75) (-75) (-75) (-75) (-75) (-75) (-75) (-75) (-75) (-75) (-75) (-75) (-75) (-75) (-75) (-75) (-75) (-75) (-75) (-75) (-75) (-75) (-75) (-75) (-75) (-75) (-75) (-75) (-75) (-75) (-75)
				(-75) (-75) (-75) (-75) (-75) (-75) (-75) (-75) (-75) (-75) (-75) (-75) (-75) (-75) (-75) (-75) (-75) (-75) (-75) (-75) (-75) (-75) (-75) (-75) (-75) (-75) (-75) (-75) (-75) (-75) (-75) (-75) (-75) (-75) (-75) (-75)
				(-75) (-75) (-75) (-75) (-75) (-75) (-75) (-75) (-75) (-75) (-75) (-75) (-75) (-75) (-75) (-75) (-75) (-75) (-75) (-75) (-75) (-75) (-75) (-75) (-75) (-75) (-75) (-75) (-75) (-75) (-75) (-75) (-75) (-75) (-75) (-75)
				(-75) (-75) (-75) (-75) (-75) (-75) (-75) (-75) (-75) (-75) (-75) (-75) (-75) (-75) (-75) (-75) (-75) (-75) (-75) (-75) (-75) (-75) (-75) (-75) (-75) (-75) (-75) (-75) (-75) (-75) (-75) (-75) (-75) (-75) (-75) (-75)
				(-75) (-75) (-75) (-75) (-75) (-75) (-75) (-75) (-75) (-75) (-75) (-75) (-75) (-75) (-75) (-75) (-75) (-75) (-75) (-75) (-75) (-75) (-75) (-75) (-75) (-75) (-75) (-75) (-75) (-75) (-75) (-75) (-75) (-75) (-75) (-75)
				(-75) (-75) (-75) (-75) (-75) (-75) (-75) (-75) (-75) (-75) (-75) (-75) (-75) (-75) (-75) (-75) (-75) (-75) (-75) (-75) (-75) (-75) (-75) (-75) (-75) (-75) (-75) (-75) (-75) (-75) (-75) (-75) (-75) (-75) (-75) (-75)
				(-75) (-75) (-75) (-75) (-75) (-75) (-75) (-75) (-75) (-75) (-75) (-75) (-75) (-75) (-75) (-75) (-75) (-75) (-75) (-75) (-75) (-75) (-75) (-75) (-75) (-75) (-75) (-75) (-75) (-75) (-75) (-75) (-75) (-75) (-75) (-75)
				(-75) (-75) (-75) (-75) (-75) (-75) (-75) (-75) (-75) (-75) (-75) (-75) (-75) (-75) (-75) (-75) (-75) (-75) (-75) (-75) (-75) (-75) (-75) (-75) (-75) (-75) (-75) (-75) (-75) (-75) (-75) (-75) (-75) (-75) (-75) (-75)
				(-75) (-75) (-75) (-75) (-75) (-75) (-75) (-75) (-75) (-75) (-75) (-75) (-75) (-75) (-75) (-75) (-75) (-75) (-75) (-75) (-75) (-75) (-75) (-75) (-75) (-75) (-75) (-75) (-75) (-75) (-75) (-75) (-75) (-75) (-75) (-75)
				(-75) (-75) (-75) (-75) (-75) (-75) (-75) (-75) (-75) (-75) (-75) (-75) (-75) (-75) (-75) (-75) (-75) (-75) (-75) (-75) (-75) (-75) (-75) (-75) (-75) (-75) (-75) (-75) (-75) (-75) (-75) (-75) (-75) (-75) (-75) (-75)
				(-75) (-75) (-75) (-75) (-75) (-75) (-75) (-75) (-75) (-75) (-75) (-75) (-75) (-75) (-75) (-75) (-75) (-75) (-75) (-75) (-75) (-75) (-75) (-75) (-75) (-75) (-75) (-75) (-75) (-75) (-75) (-75) (-75) (-75) (-75) (-75)
				(-75) (-75) (-75) (-75) (-75) (-75) (-75) (-75) (-75) (-75) (-75) (-75) (-75) (-75) (-75) (-75) (-75) (-75) (-75) (-75) (-75) (-75) (-75) (-75) (-75) (-75) (-75) (-75) (-75) (-75) (-75) (-75) (-75) (-75) (-75) (-75)
				(-75) (-75) (-75) (-75) (-75) (-75) (-75) (-75) (-75) (-75) (-75) (-75) (-75) (-75) (-75) (-75) (-75) (-75) (-75) (-75) (-75) (-75) (-75) (-75) (-75) (-75) (-75) (-75) (-75) (-75) (-75) (-75) (-75) (-75) (-75) (-75)
				(-75) (-75) (-75) (-75) (-75) (-75) (-75) (-75) (-75) (-75) (-75) (-75) (-75) (-75) (-75) (-75) (-75) (-75) (-75) (-75) (-75) (-75) (-75) (-75) (-75) (-75) (-75) (-75) (-75) (-75) (-75) (-75) (-75) (-75) (-75) (-75)
				(-75) (-75) (-75) (-75) (-75) (-75) (-75) (-75) (-75) (-75) (-75) (-75) (-75) (-75) (-75) (-75) (-75) (-75) (-75) (-75) (-75) (-75) (-75) (-75) (-75) (-75) (-75) (-75) (-75) (-75) (-75) (-75) (-75) (-75) (-75) (-75)
				(-75) (-75) (-75) (-75) (-75) (-75) (-75) (-75) (-75) (-75) (-75) (-75) (-75) (-75) (-75) (-75) (-75) (-75) (-75) (-75) (-75) (-75) (-75) (-75) (-75) (-75) (-75) (-75) (-75) (-75) (-75) (-75) (-75) (-75) (-75) (-75)
				(-75) (-75) (-75) (-75) (-75) (-75) (-75) (-75) (-75) (-75) (-75) (-75) (-75) (-75) (-75) (-75) (-75) (-75) (-75) (-75) (-75) (-75) (-75) (-75) (-75) (-75) (-75) (-75) (-75) (-75) (-75) (-75) (-75) (-75) (-75) (-75)
				(-75) (-75) (-75) (-75) (-75) (-75) (-75) (-75) (-75) (-75) (-75) (-75) (-75) (-75) (-75) (-75) (-75) (-75) (-75) (-75) (-75) (-75) (-75) (-75) (-75) (-75) (-75) (-75) (-75) (-75) (-75) (-75) (-75) (-75) (-75) (-75)
				(-75) (-75) (-75) (-75) (-75) (-75) (-75) (-75) (-75) (-75) (-75) (-75) (-75) (-75) (-75) (-75) (-75) (-75) (-75) (-75) (-75) (-75) (-75) (-75) (-75) (-75) (-75) (-75) (-75) (-75) (-75) (-75) (-75) (-75) (-75) (-75)
				(-75) (-75) (-75) (-75) (-75) (-75) (-75) (-75) (-75) (-75) (-75) (-75) (-75) (-75) (-75) (-75) (-75) (-75) (-75) (-75) (-75) (-75) (-75) (-75) (-75) (-75) (-75) (-75) (-75) (-75) (-75) (-75) (-75) (-75) (-75) (-75)
				(-75) (-75) (-75) (-75) (-75) (-75) (-75) (-75) (-75) (-75) (-75) (-75) (-75) (-75) (-75) (-75) (-75) (-75) (-75) (-75) (-75) (-75) (-75) (-75) (-75) (-75) (-75) (-75) (-75) (-75) (-75) (-75) (-75) (-75) (-75) (-75)
				(-75) (-75) (-75) (-75) (-75) (-75) (-75) (-75) (-75) (-75) (-75) (-75) (-75) (-75) (-75) (-75) (-75) (-75) (-75) (-75) (-75) (-75) (-75) (-75) (-75) (-75) (-75) (-75) (-75) (-75) (-75) (-75) (-75) (-75) (-75) (-75)
				(-75) (-75) (-75) (-75) (-75) (-75) (-75) (-75) (-75) (-75) (-75) (-75) (-75) (-75) (-75) (-75) (-75) (-75) (-75) (-75) (-75) (-75) (-75) (-75) (-75) (-75) (-75) (-75) (-75) (-75) (-75) (-75) (-75) (-75) (-75) (-75)
				(-75) (-75) (-75) (-75) (-75) (-75) (-75) (-75) (-75) (-75) (-75) (-75) (-75) (-75) (-75) (-75) (-75) (-75) (-75) (-75) (-75) (-75) (-75) (-75) (-75) (-75) (-75) (-75) (-75) (-75) (-75) (-75) (-75) (-75) (-75) (-75)
				(-75) (-75) (-75) (-75) (-75) (-75) (-75) (-75) (-75) (-75) (-75) (-75) (-75) (-75) (-75) (-75) (-75) (-75) (-75) (-75) (-75) (-75) (-75) (-75) (-75) (-75) (-75) (-75) (-75) (-75) (-75) (-75) (-75) (-75) (-75) (-75)
				(-75) (-75) (-75) (-75) (-75) (-75) (-75) (-75) (-75) (-75) (-75) (-75) (-75) (-75) (-75) (-75) (-75) (-75) (-75) (-75) (-75) (-75) (-75) (-75) (-75) (-75) (-75) (-75) (-75) (-75) (-75) (-75) (-75) (-75) (-75) (-75)
				(-75) (-75) (-75) (-75) (-75) (-75) (-75) (-75) (-75) (-75) (-75) (-75) (-75) (-75) (-75) (-75) (-75) (-75) (-75) (-75) (-75) (-75) (-75) (-75) (-75) (-75) (-75) (-75) (-75) (-75) (-75) (-75) (-75) (-75) (-75) (-75)
				(-75) (-75) (-75) (-75) (-75) (-75) (-75) (-75) (-75) (-75) (-75) (-75) (-75) (-75) (-75) (-75) (-75) (-75) (-75) (-75) (-75) (-75) (-75) (-75) (-75) (-75) (-75) (-75) (-75) (-75) (-75) (-75) (-75) (-75) (-75) (-75)
				(-75) (-75) (-75) (-75) (-75) (-75) (-75) (-75) (-75) (-75) (-75) (-75) (-75) (-75) (-75) (-75) (-75) (-75) (-75) (-75) (-75) (-75) (-75) (-75) (-75) (-75) (-75) (-75) (-75) (-75) (-75) (-75) (-75) (-75) (-75) (-75)
				(-75) (-75) (-75) (-75) (-75) (-75) (-75) (-75) (-75) (-75) (-75) (-75) (-75) (-75) (-75) (-75) (-75) (-75) (-75) (-75) (-75) (-75) (-75) (-75) (-75) (-75) (-75) (-75) (-75) (-75) (-75) (-75) (-75) (-75) (-75) (-75)
				(-75) (-75) (-75) (-75) (-75) (-75) (-75) (-75) (-75) (-75) (-75) (-75) (-75) (-75) (-75) (-75) (-75) (-75) (-75) (-75) (-75) (-75) (-75) (-75) (-75) (-75) (-75) (-75) (-75) (-75) (-75) (-75) (-75) (-75) (-75) (-75)
				(-75) (-75) (-75) (-75) (-75) (-75) (-75) (-75) (-75) (-75) (-75) (-75) (-75) (-75) (-75) (-75) (-75) (-75) (-75) (-75) (-75) (-75) (-75) (-75) (-75) (-75) (-75) (-75) (-75) (-75) (-75) (-75) (-75) (-75) (-75) (-75)
				(-75) (-75) (-75) (-75) (-75) (-75) (-75) (-75) (-75) (-75) (-75) (-75) (-75) (-75) (-75) (-75) (-75) (-75) (-75) (-75) (-75) (-75) (-75) (-75) (-75) (-75) (-75) (-75) (-75) (-75) (-75) (-75) (-75) (-75) (-75) (-75)
				(-75) (-75) (-75) (-75) (-75) (-75) (-75) (-75) (-75) (-75) (-75) (-75) (-75) (-75) (-75) (-75) (-75) (-75) (-75) (-75) (-75) (-75) (-75) (-75) (-75) (-75) (-75) (-75) (-75) (-75) (-75) (-75) (-75) (-75) (-75) (-75)
				(-75) (-75) (-75) (-75) (-75) (-75) (-75) (-75) (-75) (-75) (-75) (-75) (-75) (-75) (-75) (-75) (-75) (-75) (-75) (-75) (-75) (-75) (-75) (-75) (-75) (-75) (-75) (-75) (-75) (-75) (-75) (-75) (-75) (-75) (-75) (-75)
				(-75) (-75) (-75) (-75) (-75) (-75) (-75) (-75) (-75) (-75) (-75) (-75) (-75) (-75) (-75) (-75) (-75) (-75) (-75) (-75) (-75) (-75) (-75) (-75) (-75) (-75) (-75) (-75) (-75) (-75) (-75) (-75) (-75) (-75) (-75) (-75)
				(-75) (-75) (-75) (-75) (-75) (-75) (-75) (-75) (-75) (-75) (-75) (-75) (-75) (-75) (-75) (-75) (-75) (-75) (-75) (-75) (-75) (-75) (-75) (-75) (-75) (-75) (-75) (-75) (-75) (-75) (-75) (-75) (-75) (-75) (-75) (-75)
				(-75) (-75) (-75) (-75) (-75) (-75) (-75) (-75) (-75) (-75) (-75) (-75) (-75) (-75) (-75) (-75) (-75) (-75) (-75) (-75) (-75) (-75) (-75) (-75) (-75) (-75) (-75) (-75) (-75) (-75) (-75) (-75) (-75) (-75) (-75) (-75)
				(-75) (-75) (-75) (-75) (-75) (-75) (-75) (-75) (-75) (-75) (-75) (-75) (-75) (-75) (-75) (-75) (-75) (-75) (-75) (-75) (-75) (-75) (-75) (-75) (-75) (-75) (-75) (-75) (-75) (-75) (-75) (-75) (-75) (-75) (-75) (-75)
				(-75) (-75) (-75) (-75) (-75) (-75) (-75) (-75) (-75) (-75) (-75) (-75) (-75) (-75) (-75) (-75) (-75) (-75) (-75) (-75) (-75) (-75) (-75) (-75) (-75) (-75) (-75) (-75) (-75) (-75) (-75) (-75) (-75) (-75) (-75) (-75)
				(-75) (-75) (-75) (-75) (-75) (-75) (-75) (-75) (-75) (-75) (-75) (-75) (-75) (-75) (-75) (-75) (-75) (-75) (-75) (-75) (-75) (-75) (-75) (-75) (-75) (-75) (-75) (-75) (-75) (-75) (-75) (-75) (-75) (-75) (-75) (-75)
				(-75) (-75) (-75)>;

			/* FDM config */
			FDM_X_Channel = <2>;

			PS_Config_Lmt_FDM_Rawdata_P = <
				900 900
				900 900
				900 900
				900 900
				900 900
				900 900
				900 900
				900 900
				900 900
				900 900
				900 900
				900 900
				900 900
				900 900
				900 900
				900 900
				900 900
				900 900
				900 900
				900 900
				900 900
				900 900
				900 900
				900 900
				900 900
				900 900
				900 900
				900 900
				900 900
				900 900
				900 900
				900 900
				900 900
				900 900
				900 900
				900 900
				900 900
				900 900
				900 900
				900 900
				900 900
				900 900
				900 900
				900 900
				900 900
				900 900
				900 900
				900 900
				900 900
				900 900>;

			PS_Config_Lmt_FDM_Rawdata_N = <
				50 50
				50 50
				50 50
				50 50
				50 50
				50 50
				50 50
				50 50
				50 50
				50 50
				50 50
				50 50
				50 50
				50 50
				50 50
				50 50
				50 50
				50 50
				50 50
				50 50
				50 50
				50 50
				50 50
				50 50
				50 50
				50 50
				50 50
				50 50
				50 50
				50 50
				50 50
				50 50
				50 50
				50 50
				50 50
				50 50
				50 50
				50 50
				50 50
				50 50
				50 50
				50 50
				50 50
				50 50
				50 50
				50 50
				50 50
				50 50
				50 50
				50 50>;

			PS_Config_FDM_Noise_Test_Frame = <50>;
			PS_Config_Lmt_FDM_Diff_P = <
				180 180
				180 180
				180 180
				180 180
				180 180
				180 180
				180 180
				180 180
				180 180
				180 180
				180 180
				180 180
				180 180
				180 180
				180 180
				180 180
				180 180
				180 180
				180 180
				180 180
				180 180
				180 180
				180 180
				180 180
				180 180
				180 180
				180 180
				180 180
				180 180
				180 180
				180 180
				180 180
				180 180
				180 180
				180 180
				180 180
				180 180
				180 180
				180 180
				180 180
				180 180
				180 180
				180 180
				180 180
				180 180
				180 180
				180 180
				180 180
				180 180
				180 180>;

			PS_Config_Lmt_FDM_Diff_N = <
				(-180) (-180)
				(-180) (-180)
				(-180) (-180)
				(-180) (-180)
				(-180) (-180)
				(-180) (-180)
				(-180) (-180)
				(-180) (-180)
				(-180) (-180)
				(-180) (-180)
				(-180) (-180)
				(-180) (-180)
				(-180) (-180)
				(-180) (-180)
				(-180) (-180)
				(-180) (-180)
				(-180) (-180)
				(-180) (-180)
				(-180) (-180)
				(-180) (-180)
				(-180) (-180)
				(-180) (-180)
				(-180) (-180)
				(-180) (-180)
				(-180) (-180)
				(-180) (-180)
				(-180) (-180)
				(-180) (-180)
				(-180) (-180)
				(-180) (-180)
				(-180) (-180)
				(-180) (-180)
				(-180) (-180)
				(-180) (-180)
				(-180) (-180)
				(-180) (-180)
				(-180) (-180)
				(-180) (-180)
				(-180) (-180)
				(-180) (-180)
				(-180) (-180)
				(-180) (-180)
				(-180) (-180)
				(-180) (-180)
				(-180) (-180)
				(-180) (-180)
				(-180) (-180)
				(-180) (-180)
				(-180) (-180)
				(-180) (-180)>;
		};
	};
	/*Tab A7 T618 code for SR-AX6189A-01-148 by suyurui at 2021/12/22 end*/

};
/*Tab A7 T618 code for AX6189DEV-20|AX6189DEV-26 by suyurui at 2021/12/21 end*/
